[part 10 of 22: package /Cluster]
AUTOSAR XML (schema 4-3-0)
package /Cluster  (continued)
  can cluster E3V_K2CANFD: baudrate=500000, protocol-name=CAN, protocol-version=2.0, bus-off-recovery={bor-counter-l-1-to-l-2=1, bor-time-l-1=0.05, bor-time-l-2=0.2}, can-fd-baudrate=500000  (continued)
    can physical channel CHNL: comm-connectors=CN_E3V_K2CANFD  (continued)
      frame SAD_01_XIX_E3V_K2CANFD: id 0x5E0, to SAM, frame-length=8, can-addressing-mode=STANDARD, can-frame-rx-behavior=CAN-FD, can-frame-tx-behavior=CAN-FD
        pdu SAD_01_XIX_E3V_K2CANFD: length=8, minimum-delay=0.05, transmission-mode-true-timing={cyclic-timing={time-offset=0.0, time-period=0.5}, event-controlled-timing={number-of-repetitions=5, repetition-period=0.1}}, unused-bit-pattern=0  # MLBevo 8Byte LIN-CAN (1:1) Botschaft wird geroutet: - wenn entsprechender Slave codiert ist - wenn fehlerfreie Kommunikation zum Slave besteht - bei fehlerhafter Kommunikation zum Slave wird die Botschaft für 4s mit den letzten gültigen Werten versendet
          signal MD1_Position_XIX_SAD_01_XIX_E3V_K2CANFD: start 8, 7 bit, little-endian, data-type-policy=OVERRIDE, i-signal-type=PRIMITIVE, init-value=126, base-type=BT_MD1_Position, compu {phys=raw for raw 0..100, 126=Cx7e_Init (CM_MD1_Position_Cx7e_Init), 127=Cx7f_nicht_normiert (CM_MD1_Position_Cx7f_nicht_normiert); unit Unit_PerCent}, range phys 0..100 Unit_PerCent, raw 0..127, unit=Unit_PerCent, transfer-property=PENDING, to SAM  # Aktuelle Öffnungsweite Schiebedach.
          signal MD1_Lage_XIX_SAD_01_XIX_E3V_K2CANFD: start 15, 1 bit, little-endian, data-type-policy=OVERRIDE, i-signal-type=PRIMITIVE, init-value=0, base-type=BT_MD1_Lage, compu {0=Cx0_Ausstelllage (CM_MD1_Lage_Cx0_Ausstelllage), 1=Cx1_Schiebelage (CM_MD1_Lage_Cx1_Schiebelage)}, range raw 0..1, transfer-property=PENDING, to SAM  # Lage Schiebedachstellung 1 (Signal wird 1:1 vom BCM2 geroutet; ursprünglicher Sender: SAD = LIN-Slave vom BCM2)
          signal MD3_Position_XIX_SAD_01_XIX_E3V_K2CANFD: start 16, 7 bit, little-endian, data-type-policy=OVERRIDE, i-signal-type=PRIMITIVE, init-value=0, base-type=BT_MD3_Position, compu {phys=raw for raw 0..100; unit Unit_PerCent}, range phys 0..100 Unit_PerCent, raw 0..100, unit=Unit_PerCent, transfer-property=PENDING  # Schiebedachstellung 3 (Signal wird 1:1 vom BCM2 geroutet; ursprünglicher Sender: SAD = LIN-Slave vom BCM2)
          signal MD3_Lage_XIX_SAD_01_XIX_E3V_K2CANFD: start 23, 1 bit, little-endian, data-type-policy=OVERRIDE, i-signal-type=PRIMITIVE, init-value=0, base-type=BT_MD3_Lage, compu {0=Cx0_Ausstelllage (CM_MD3_Lage_Cx0_Ausstelllage), 1=Cx1_Schiebelage (CM_MD3_Lage_Cx1_Schiebelage)}, range raw 0..1, transfer-property=PENDING  # Lage Schiebedachstellung 3 (Signal wird 1:1 vom BCM2 geroutet; ursprünglicher Sender: SAD = LIN-Slave vom BCM2)
          signal MRollo_Position_XIX_SAD_01_XIX_E3V_K2CANFD: start 24, 7 bit, little-endian, data-type-policy=OVERRIDE, i-signal-type=PRIMITIVE, init-value=126, base-type=BT_MRollo_Position, compu {phys=raw for raw 0..100, 126=Cx7e_Init (CM_MRollo_Position_Cx7e_Init), 127=Cx7f_nicht_normiert (CM_MRollo_Position_Cx7f_nicht_normiert); unit Unit_PerCent}, range phys 0..100 Unit_PerCent, raw 0..127, unit=Unit_PerCent, transfer-property=PENDING  # Aktuelle Öffnungsweite des Dachrollos.
          signal MRollo_Lage_XIX_SAD_01_XIX_E3V_K2CANFD: start 31, 1 bit, little-endian, data-type-policy=OVERRIDE, i-signal-type=PRIMITIVE, init-value=0, base-type=BT_MRollo_Lage, compu {0=Cx0_Ausstelllage (CM_MRollo_Lage_Cx0_Ausstelllage), 1=Cx1_Schiebelage (CM_MRollo_Lage_Cx1_Schiebelage)}, range raw 0..1, transfer-property=PENDING  # Lage Rollo (Signal wird 1:1 vom BCM2 geroutet; ursprünglicher Sender: Rollo = LIN-Slave vom BCM2)
          signal SAD_normiert_XIX_SAD_01_XIX_E3V_K2CANFD: start 32, 1 bit, little-endian, data-type-policy=OVERRIDE, i-signal-type=PRIMITIVE, init-value=0, base-type=BT_SAD_normiert, compu {0=Cx0_inaktiv (CM_SAD_normiert_Cx0_inaktiv), 1=Cx1_aktiv (CM_SAD_normiert_Cx1_aktiv)}, range raw 0..1, transfer-property=TRIGGERED-ON-CHANGE-WITHOUT-REPETITION  # Anzeige Normierung des Schiebeausstelldaches
          signal SAD_Thermoschutz_XIX_SAD_01_XIX_E3V_K2CANFD: start 33, 1 bit, little-endian, data-type-policy=OVERRIDE, i-signal-type=PRIMITIVE, init-value=0, base-type=BT_SAD_Thermoschutz, compu {0=Cx0_inaktiv (CM_SAD_Thermoschutz_Cx0_inaktiv), 1=Cx1_aktiv (CM_SAD_Thermoschutz_Cx1_aktiv)}, range raw 0..1, transfer-property=TRIGGERED-ON-CHANGE-WITHOUT-REPETITION  # Anzeige aktivierter Thermoschutz des Schiebeausstelldaches
          signal SAD_UEKB_aktiv_XIX_SAD_01_XIX_E3V_K2CANFD: start 34, 1 bit, little-endian, data-type-policy=OVERRIDE, i-signal-type=PRIMITIVE, init-value=0, base-type=BT_SAD_UEKB_aktiv, compu {0=Cx0_inaktiv (CM_SAD_UEKB_aktiv_Cx0_inaktiv), 1=Cx1_aktiv (CM_SAD_UEKB_aktiv_Cx1_aktiv)}, range raw 0..1, transfer-property=TRIGGERED-ON-CHANGE-WITHOUT-REPETITION  # Anzeige aktivierter Überschusskraftbegrenzung des Schiebeausstelldaches
          signal Rollo_normiert_XIX_SAD_01_XIX_E3V_K2CANFD: start 35, 1 bit, little-endian, data-type-policy=OVERRIDE, i-signal-type=PRIMITIVE, init-value=0, base-type=BT_Rollo_normiert, compu {0=Cx0_inaktiv (CM_Rollo_normiert_Cx0_inaktiv), 1=Cx1_aktiv (CM_Rollo_normiert_Cx1_aktiv)}, range raw 0..1, transfer-property=TRIGGERED-ON-CHANGE-WITHOUT-REPETITION  # Anzeigen Normierung des Dachrollos
          signal Rollo_Thermoschutz_XIX_SAD_01_XIX_E3V_K2CANFD: start 36, 1 bit, little-endian, data-type-policy=OVERRIDE, i-signal-type=PRIMITIVE, init-value=0, base-type=BT_Rollo_Thermoschutz, compu {0=Cx0_inaktiv (CM_Rollo_Thermoschutz_Cx0_inaktiv), 1=Cx1_aktiv (CM_Rollo_Thermoschutz_Cx1_aktiv)}, range raw 0..1, transfer-property=TRIGGERED-ON-CHANGE-WITHOUT-REPETITION  # Anzeigen aktivierter Thermoschutz des Dachrollo
          signal Rollo_UEKB_aktiv_XIX_SAD_01_XIX_E3V_K2CANFD: start 37, 1 bit, little-endian, data-type-policy=OVERRIDE, i-signal-type=PRIMITIVE, init-value=0, base-type=BT_Rollo_UEKB_aktiv, compu {0=Cx0_inaktiv (CM_Rollo_UEKB_aktiv_Cx0_inaktiv), 1=Cx1_aktiv (CM_Rollo_UEKB_aktiv_Cx1_aktiv)}, range raw 0..1, transfer-property=TRIGGERED-ON-CHANGE-WITHOUT-REPETITION  # Anzeigen aktivierter Überschusskraftbegrenzung des Dachrollos
          signal SAD_Taster_Deckel_hi_XIX_SAD_01_XIX_E3V_K2CANFD: start 38, 4 bit, little-endian, data-type-policy=OVERRIDE, i-signal-type=PRIMITIVE, init-value=0, base-type=BT_SAD_Taster_Deckel_hi, compu {0=Cx0_nicht_betaetigt (CM_SAD_Taster_Deckel_hi_Cx0_nicht_betaetigt), 1=Cx1_man_sl_zu (CM_SAD_Taster_Deckel_hi_Cx1_man_sl_zu), 2=Cx2_auto_sl_zu (CM_SAD_Taster_Deckel_hi_Cx2_auto_sl_zu), 3=Cx3_man_sl_auf (CM_SAD_Taster_Deckel_hi_Cx3_man_sl_auf), 4=Cx4_auto_sl_auf (CM_SAD_Taster_Deckel_hi_Cx4_auto_sl_auf), 5=Cx5_man_al_auf (CM_SAD_Taster_Deckel_hi_Cx5_man_al_auf), 6=Cx6_auto_al_auf (CM_SAD_Taster_Deckel_hi_Cx6_auto_al_auf), 7=Cx7_man_al_zu (CM_SAD_Taster_Deckel_hi_Cx7_man_al_zu), 8=Cx8_auto_al_zu (CM_SAD_Taster_Deckel_hi_Cx8_auto_al_zu), 14=Cxe_fehler_schalter_haengt (CM_SAD_Taster_Deckel_hi_Cxe_fehler_schalter_haengt), 15=Cxf_fehler_schalter_unplausibel (CM_SAD_Taster_Deckel_hi_Cxf_fehler_schalter_unplausibel)}, range raw 0..15, transfer-property=TRIGGERED-ON-CHANGE  # Taster für SAD Deckel hinten
          signal SAD_Taster_Deckel_vo_XIX_SAD_01_XIX_E3V_K2CANFD: start 42, 4 bit, little-endian, data-type-policy=OVERRIDE, i-signal-type=PRIMITIVE, init-value=0, base-type=BT_SAD_Taster_Deckel_vo, compu {0=Cx0_nicht_betaetigt (CM_SAD_Taster_Deckel_vo_Cx0_nicht_betaetigt), 1=Cx1_man_sl_zu (CM_SAD_Taster_Deckel_vo_Cx1_man_sl_zu), 2=Cx2_auto_sl_zu (CM_SAD_Taster_Deckel_vo_Cx2_auto_sl_zu), 3=Cx3_man_sl_auf (CM_SAD_Taster_Deckel_vo_Cx3_man_sl_auf), 4=Cx4_auto_sl_auf (CM_SAD_Taster_Deckel_vo_Cx4_auto_sl_auf), 5=Cx5_man_al_auf (CM_SAD_Taster_Deckel_vo_Cx5_man_al_auf), 6=Cx6_auto_al_auf (CM_SAD_Taster_Deckel_vo_Cx6_auto_al_auf), 7=Cx7_man_al_zu (CM_SAD_Taster_Deckel_vo_Cx7_man_al_zu), 8=Cx8_auto_al_zu (CM_SAD_Taster_Deckel_vo_Cx8_auto_al_zu), 14=Cxe_fehler_schalter_haengt (CM_SAD_Taster_Deckel_vo_Cxe_fehler_schalter_haengt), 15=Cxf_fehler_schalter_unplausibel (CM_SAD_Taster_Deckel_vo_Cxf_fehler_schalter_unplausibel)}, range raw 0..15, transfer-property=TRIGGERED-ON-CHANGE  # Taster für SAD Deckel vorne
          signal SAD_Taster_Rollo_hi_XIX_SAD_01_XIX_E3V_K2CANFD: start 46, 3 bit, little-endian, data-type-policy=OVERRIDE, i-signal-type=PRIMITIVE, init-value=0, base-type=BT_SAD_Taster_Rollo_hi, compu {0=Cx0_nicht_betaetigt (CM_SAD_Taster_Rollo_hi_Cx0_nicht_betaetigt), 1=Cx1_man_zu (CM_SAD_Taster_Rollo_hi_Cx1_man_zu), 2=Cx2_auto_zu (CM_SAD_Taster_Rollo_hi_Cx2_auto_zu), 3=Cx3_man_auf (CM_SAD_Taster_Rollo_hi_Cx3_man_auf), 4=Cx4_auto_auf (CM_SAD_Taster_Rollo_hi_Cx4_auto_auf), 6=Cx6_fehler_schalter_haengt (CM_SAD_Taster_Rollo_hi_Cx6_fehler_schalter_haengt), 7=Cx7_fehler_schalter_unplausibel (CM_SAD_Taster_Rollo_hi_Cx7_fehler_schalter_unplausibel)}, range raw 0..7, transfer-property=TRIGGERED-ON-CHANGE  # Taster für SAD Rollo hinten
          signal SAD_Taster_Rollo_vo_XIX_SAD_01_XIX_E3V_K2CANFD: start 49, 3 bit, little-endian, data-type-policy=OVERRIDE, i-signal-type=PRIMITIVE, init-value=0, base-type=BT_SAD_Taster_Rollo_vo, compu {0=Cx0_nicht_betaetigt (CM_SAD_Taster_Rollo_vo_Cx0_nicht_betaetigt), 1=Cx1_man_zu (CM_SAD_Taster_Rollo_vo_Cx1_man_zu), 2=Cx2_auto_zu (CM_SAD_Taster_Rollo_vo_Cx2_auto_zu), 3=Cx3_man_auf (CM_SAD_Taster_Rollo_vo_Cx3_man_auf), 4=Cx4_auto_auf (CM_SAD_Taster_Rollo_vo_Cx4_auto_auf), 6=Cx6_fehler_schalter_haengt (CM_SAD_Taster_Rollo_vo_Cx6_fehler_schalter_haengt), 7=Cx7_fehler_schalter_unplausibel (CM_SAD_Taster_Rollo_vo_Cx7_fehler_schalter_unplausibel)}, range raw 0..7, transfer-property=TRIGGERED-ON-CHANGE  # Taster für SAD Rollo vorne
          signal SAD_Anf_ESC_Zuschaltung_XIX_SAD_01_XIX_E3V_K2CANFD: start 52, 1 bit, little-endian, data-type-policy=OVERRIDE, i-signal-type=PRIMITIVE, init-value=0, base-type=BT_SAD_Anf_ESC_Zuschaltung, compu {0=Cx0_inaktiv (CM_SAD_Anf_ESC_Zuschaltung_Cx0_inaktiv), 1=Cx1_aktiv (CM_SAD_Anf_ESC_Zuschaltung_Cx1_aktiv)}, range raw 0..1, transfer-property=TRIGGERED-ON-CHANGE-WITHOUT-REPETITION  # Zwangsaktivierung ESP durch SAD-SG (bei geöffnetem Schiebedach und V> xx km/h).
          signal SAD_Text_XIX_SAD_01_XIX_E3V_K2CANFD: start 53, 1 bit, little-endian, data-type-policy=OVERRIDE, i-signal-type=PRIMITIVE, init-value=0, base-type=BT_SAD_Text, compu {0=Cx0_inaktiv (CM_SAD_Text_Cx0_inaktiv), 1=Cx1_aktiv (CM_SAD_Text_Cx1_aktiv)}, range raw 0..1, transfer-property=TRIGGERED-ON-CHANGE  # Fehler Windabweiser in Abhängigkeit von der Geschwindigkeit
          signal SAD_ToggleBit_XIX_SAD_01_XIX_E3V_K2CANFD: start 54, 1 bit, little-endian, data-type-policy=OVERRIDE, i-signal-type=PRIMITIVE, init-value=0, base-type=BT_SAD_ToggleBit, compu {phys=raw for raw 0..1}, range phys 0..1, raw 0..1, transfer-property=PENDING  # SIL A Absicherung für die Signale: SAD_normiert, MD1_Lage, MD1_Position, SAD_Anf_ESC_Zuschaltung
          signal SAD_ParityBit_XIX_SAD_01_XIX_E3V_K2CANFD: start 55, 1 bit, little-endian, data-type-policy=OVERRIDE, i-signal-type=PRIMITIVE, init-value=0, base-type=BT_SAD_ParityBit, compu {phys=raw for raw 0..1}, range phys 0..1, raw 0..1, transfer-property=PENDING  # SIL A Absicherung für die Signale: SAD_normiert, MD1_Lage, MD1_Position, SAD_Anf_ESC_Zuschaltung
      frame SAL_01_XIX_E3V_K2CANFD: id 0x12DD54C9, to SAM, frame-length=8, can-addressing-mode=EXTENDED, can-frame-rx-behavior=CAN-FD, can-frame-tx-behavior=CAN-FD
        pdu SAL_01_XIX_E3V_K2CANFD_E2E: length=8, minimum-delay=0.01, transmission-mode-true-timing=event-controlled-timing={number-of-repetitions=0, repetition-period=0.0}, unused-bit-pattern=0  # Fuer die Botschaft ist das Cyclic-Timing 0.08 zu verwenden.
          signal SAL_01_CRC_XIX_SAL_01_XIX_E3V_K2CANFD: start 0, 8 bit, little-endian, data-type-policy=OVERRIDE, i-signal-type=PRIMITIVE, base-type=BT_SAL_01_CRC, compu {phys=raw for raw 0..255}, range phys 0..255, raw 0..255, to SAM(timeout 0.8 s)  # Für MLB: Berechnung siehe Lastenheft "Kommunikationsabsicherung für FlexRay und CAN" Ab MQB und MLBevo: Berechnung siehe Lastenheft "End-to-End Kommunikationsabsicherung" Endwerte siehe Begleitdokument "S-PDU Kennungsfolgen"
          signal SAL_01_BZ_XIX_SAL_01_XIX_E3V_K2CANFD: start 8, 4 bit, little-endian, data-type-policy=OVERRIDE, i-signal-type=PRIMITIVE, base-type=BT_SAL_01_BZ, compu {phys=raw for raw 0..15}, range phys 0..15, raw 0..15, to SAM(timeout 0.8 s)  # 4bit Botschaftszähler, wird mit jeder Sendebotschaft inkrementiert
          signal SAL_LDS_Abblendlicht_Anf_XIX_SAL_01_XIX_E3V_K2CANFD: start 12, 1 bit, little-endian, data-type-policy=OVERRIDE, i-signal-type=PRIMITIVE, init-value=0, base-type=BT_SAL_LDS_Abblendlicht_Anf, compu {0=Cx0_nicht_aktiv (CM_SAL_LDS_Abblendlicht_Anf_Cx0_nicht_aktiv), 1=Cx1_aktiv (CM_SAL_LDS_Abblendlicht_Anf_Cx1_aktiv)}, range raw 0..1, to SAM(timeout 0.8 s)  # Signal gibt an, ob das Abblendlicht angefordert wird.
          signal SAL_LDS_Assistenzfahrlicht_Anf_XIX_SAL_01_XIX_E3V_K2CANFD: start 13, 1 bit, little-endian, data-type-policy=OVERRIDE, i-signal-type=PRIMITIVE, init-value=0, base-type=BT_SAL_LDS_Assistenzfahrlicht_Anf, compu {0=Cx0_nicht_aktiv (CM_SAL_LDS_Assistenzfahrlicht_Anf_Cx0_nicht_aktiv), 1=Cx1_aktiv (CM_SAL_LDS_Assistenzfahrlicht_Anf_Cx1_aktiv)}, range raw 0..1, to SAM(timeout 0.8 s)  # Signal gibt an, ob das Assistenzfahrlicht (AUTO) angefordert wird.
          signal SAL_LDS_Nullstellung_Anf_XIX_SAL_01_XIX_E3V_K2CANFD: start 14, 1 bit, little-endian, data-type-policy=OVERRIDE, i-signal-type=PRIMITIVE, init-value=0, base-type=BT_SAL_LDS_Nullstellung_Anf, compu {0=Cx0_nicht_aktiv (CM_SAL_LDS_Nullstellung_Anf_Cx0_nicht_aktiv), 1=Cx1_aktiv (CM_SAL_LDS_Nullstellung_Anf_Cx1_aktiv)}, range raw 0..1, to SAM(timeout 0.8 s)  # Signal gibt an, ob das Nullstellung vom Lichtdrehschalter angefordert wird.
          signal SAL_LDS_Standlicht_Anf_XIX_SAL_01_XIX_E3V_K2CANFD: start 15, 1 bit, little-endian, data-type-policy=OVERRIDE, i-signal-type=PRIMITIVE, init-value=0, base-type=BT_SAL_LDS_Standlicht_Anf, compu {0=Cx0_nicht_aktiv (CM_SAL_LDS_Standlicht_Anf_Cx0_nicht_aktiv), 1=Cx1_aktiv (CM_SAL_LDS_Standlicht_Anf_Cx1_aktiv)}, range raw 0..1, to SAM(timeout 0.8 s)  # Signal gibt an, ob das Standlicht angefordert wird.
          signal SBBR_SL_AnimDimm_Freigabe_XIX_SAL_01_XIX_E3V_K2CANFD: start 16, 2 bit, little-endian, data-type-policy=OVERRIDE, i-signal-type=PRIMITIVE, init-value=0, base-type=BT_SBBR_SL_AnimDimm_Freigabe, compu {0=Cx0_Dimmung_aus_Animation_aus (CM_SBBR_SL_AnimDimm_Freigabe_Cx0_Dimmung_aus_Animation_aus), 1=Cx1_Dimmung_an_Animation_aus (CM_SBBR_SL_AnimDimm_Freigabe_Cx1_Dimmung_an_Animation_aus), 2=Cx2_Dimmung_aus_Animation_an (CM_SBBR_SL_AnimDimm_Freigabe_Cx2_Dimmung_aus_Animation_an), 3=Cx3_Dimmung_an_Animation_an (CM_SBBR_SL_AnimDimm_Freigabe_Cx3_Dimmung_an_Animation_an)}, range raw 0..3  # Freigabesignal für Dimmung und Animation
          signal BCM2_Bremsl_durch_ECD_XIX_SAL_01_XIX_E3V_K2CANFD: start 18, 1 bit, little-endian, data-type-policy=OVERRIDE, i-signal-type=PRIMITIVE, init-value=0, base-type=BT_BCM2_Bremsl_durch_ECD, compu {0=Cx0_Bremslicht_ist_aus (CM_BCM2_Bremsl_durch_ECD_Cx0_Bremslicht_ist_aus), 1=Cx1_Bremslicht_durch_ECD_aktiv (CM_BCM2_Bremsl_durch_ECD_Cx1_Bremslicht_durch_ECD_aktiv)}, range raw 0..1  # Bremslicht (ECD-Bremsung)
          signal SAL_LH_Anf_XIX_SAL_01_XIX_E3V_K2CANFD: start 19, 1 bit, little-endian, data-type-policy=OVERRIDE, i-signal-type=PRIMITIVE, init-value=0, base-type=BT_SAL_LH_Anf, compu {0=Cx0_nicht_angefordert (CM_SAL_LH_Anf_Cx0_nicht_angefordert), 1=Cx1_angefordert (CM_SAL_LH_Anf_Cx1_angefordert)}, range raw 0..1, to SAM(timeout 0.8 s)  # Anforderung LH an Lichtrouter
          signal SAL_BRL_Anf_XIX_SAL_01_XIX_E3V_K2CANFD: start 20, 1 bit, little-endian, data-type-policy=OVERRIDE, i-signal-type=PRIMITIVE, init-value=0, base-type=BT_SAL_BRL_Anf, compu {0=Cx0_nicht_angefordert (CM_SAL_BRL_Anf_Cx0_nicht_angefordert), 1=Cx1_angefordert (CM_SAL_BRL_Anf_Cx1_angefordert)}, range raw 0..1, to SAM(timeout 0.8 s)  # Bremslicht-Anforderung an Lichtrouter
          signal SAL_WBT_Bel_XIX_SAL_01_XIX_E3V_K2CANFD: start 21, 1 bit, little-endian, data-type-policy=OVERRIDE, i-signal-type=PRIMITIVE, init-value=0, base-type=BT_SAL_WBT_Bel, compu {0=Cx0_nicht_angefordert (CM_SAL_WBT_Bel_Cx0_nicht_angefordert), 1=Cx1_angefordert (CM_SAL_WBT_Bel_Cx1_angefordert)}, range raw 0..1, to SAM(timeout 0.8 s)  # Beleuchtung Warnblinktaster an SAM
          signal SAL_CH_Anf_XIX_SAL_01_XIX_E3V_K2CANFD: start 22, 1 bit, little-endian, data-type-policy=OVERRIDE, i-signal-type=PRIMITIVE, init-value=0, base-type=BT_SAL_CH_Anf, compu {0=Cx0_nicht_angefordert (CM_SAL_CH_Anf_Cx0_nicht_angefordert), 1=Cx1_angefordert (CM_SAL_CH_Anf_Cx1_angefordert)}, range raw 0..1, to SAM(timeout 0.8 s)  # Anforderung CH an Lichtrouter
          signal SAL_PL_R_Anf_XIX_SAL_01_XIX_E3V_K2CANFD: start 23, 1 bit, little-endian, data-type-policy=OVERRIDE, i-signal-type=PRIMITIVE, init-value=0, base-type=BT_SAL_PL_R_Anf, compu {0=Cx0_nicht_angefordert (CM_SAL_PL_R_Anf_Cx0_nicht_angefordert), 1=Cx1_angefordert (CM_SAL_PL_R_Anf_Cx1_angefordert)}, range raw 0..1, to SAM(timeout 0.8 s)  # Anforderung Parklicht rechts an Lichtrouter
          signal SAL_PL_L_Anf_XIX_SAL_01_XIX_E3V_K2CANFD: start 24, 1 bit, little-endian, data-type-policy=OVERRIDE, i-signal-type=PRIMITIVE, init-value=0, base-type=BT_SAL_PL_L_Anf, compu {0=Cx0_nicht_angefordert (CM_SAL_PL_L_Anf_Cx0_nicht_angefordert), 1=Cx1_angefordert (CM_SAL_PL_L_Anf_Cx1_angefordert)}, range raw 0..1, to SAM(timeout 0.8 s)  # Anforderung Parklicht Links an Lichtrouter.
          signal SAL_BLK_R_Anf_XIX_SAL_01_XIX_E3V_K2CANFD: start 25, 1 bit, little-endian, data-type-policy=OVERRIDE, i-signal-type=PRIMITIVE, init-value=0, base-type=BT_SAL_BLK_R_Anf, compu {0=Cx0_nicht_angefordert (CM_SAL_BLK_R_Anf_Cx0_nicht_angefordert), 1=Cx1_angefordert (CM_SAL_BLK_R_Anf_Cx1_angefordert)}, range raw 0..1, to SAM(timeout 0.8 s)  # Anforderung Blinker rechts an Lichtrouter
          signal SAL_BLK_L_Anf_XIX_SAL_01_XIX_E3V_K2CANFD: start 26, 1 bit, little-endian, data-type-policy=OVERRIDE, i-signal-type=PRIMITIVE, init-value=0, base-type=BT_SAL_BLK_L_Anf, compu {0=Cx0_nicht_angefordert (CM_SAL_BLK_L_Anf_Cx0_nicht_angefordert), 1=Cx1_angefordert (CM_SAL_BLK_L_Anf_Cx1_angefordert)}, range raw 0..1, to SAM(timeout 0.8 s)  # Blink-Anforderung links an Lichtrouter
          signal SAL_RFL_Anf_XIX_SAL_01_XIX_E3V_K2CANFD: start 27, 1 bit, little-endian, data-type-policy=OVERRIDE, i-signal-type=PRIMITIVE, init-value=0, base-type=BT_SAL_RFL_Anf, compu {0=Cx0_nicht_angefordert (CM_SAL_RFL_Anf_Cx0_nicht_angefordert), 1=Cx1_angefordert (CM_SAL_RFL_Anf_Cx1_angefordert)}, range raw 0..1, to SAM(timeout 0.8 s)  # Anforderung Rückfahrlicht an Lichtrouter
          signal SAL_NSL_Anf_XIX_SAL_01_XIX_E3V_K2CANFD: start 28, 1 bit, little-endian, data-type-policy=OVERRIDE, i-signal-type=PRIMITIVE, init-value=0, base-type=BT_SAL_NSL_Anf, compu {0=Cx0_nicht_angefordert (CM_SAL_NSL_Anf_Cx0_nicht_angefordert), 1=Cx1_angefordert (CM_SAL_NSL_Anf_Cx1_angefordert)}, range raw 0..1, to SAM(timeout 0.8 s)  # Anforderung Nebelschlussleuchte an Lichtrouter
          signal SAL_SL_Anf_XIX_SAL_01_XIX_E3V_K2CANFD: start 29, 1 bit, little-endian, data-type-policy=OVERRIDE, i-signal-type=PRIMITIVE, init-value=0, base-type=BT_SAL_SL_Anf, compu {0=Cx0_nicht_angefordert (CM_SAL_SL_Anf_Cx0_nicht_angefordert), 1=Cx1_angefordert (CM_SAL_SL_Anf_Cx1_angefordert)}, range raw 0..1, to SAM(timeout 0.8 s)  # Anforderung Standlicht an Lichtrouter.
          signal SAL_HGB_Anf_XIX_SAL_01_XIX_E3V_K2CANFD: start 30, 1 bit, little-endian, data-type-policy=OVERRIDE, i-signal-type=PRIMITIVE, init-value=0, base-type=BT_SAL_HGB_Anf, compu {0=Cx0_nicht_angefordert (CM_SAL_HGB_Anf_Cx0_nicht_angefordert), 1=Cx1_angefordert (CM_SAL_HGB_Anf_Cx1_angefordert)}, range raw 0..1, to SAM(timeout 0.8 s)  # Anforderung HGB an Lichtrouter
          signal ISignalVoid_SAL_01_XIX_E3V_K2CANFD_0: start 31, 1 bit, little-endian, system signal SignalVoid_SAL_01_0, data-type-policy=OVERRIDE, i-signal-type=PRIMITIVE, base-type=BT_SignalVoid
          signal LWR_SollDC_XIX_SAL_01_XIX_E3V_K2CANFD: start 32, 8 bit, little-endian, data-type-policy=OVERRIDE, i-signal-type=PRIMITIVE, init-value=254, base-type=BT_LWR_SollDC, invalid-value=Invalid_LWR_SollDC_XIX_SAL_01_XIX_E3V_K2CANFD:255, compu {phys=raw*0.5 for raw 0..200, 254=Cxfe_Init (CM_LWR_SollDC_Cxfe_Init), 255=Cxff_Fehler (CM_LWR_SollDC_Cxff_Fehler); unit Unit_PerCent}, range phys 0..100 Unit_PerCent, raw 0..255, unit=Unit_PerCent, to SAM(timeout 0.8 s)  # Sollspannung in [% von UBatt] des linken und rechten Abblendlichtbündels.
          signal ISignalVoid_SAL_01_XIX_E3V_K2CANFD_1: start 40, 3 bit, little-endian, system signal SignalVoid_SAL_01_1, data-type-policy=OVERRIDE, i-signal-type=PRIMITIVE, base-type=BT_SignalVoid
          signal SAL_Bremszyklus_XIX_SAL_01_XIX_E3V_K2CANFD: start 43, 1 bit, little-endian, data-type-policy=OVERRIDE, i-signal-type=PRIMITIVE, init-value=0, base-type=BT_SAL_Bremszyklus, compu {0=Cx0_nicht_aktiv (CM_SAL_Bremszyklus_Cx0_nicht_aktiv), 1=Cx1_aktiv (CM_SAL_Bremszyklus_Cx1_aktiv)}, range raw 0..1, to SAM(timeout 0.8 s)  # Das Signal ist aktiv, wenn im Falle einer Notbremsung (Bremslicht-Blinken EA bzw. NBA) das Bremslicht hochfrequenz blinkt.
          signal SAL_Blinkerzyklus_R_XIX_SAL_01_XIX_E3V_K2CANFD: start 44, 1 bit, little-endian, data-type-policy=OVERRIDE, i-signal-type=PRIMITIVE, init-value=0, base-type=BT_SAL_Blinkerzyklus_R, compu {0=Cx0_inaktiv (CM_SAL_Blinkerzyklus_R_Cx0_inaktiv), 1=Cx1_aktiv (CM_SAL_Blinkerzyklus_R_Cx1_aktiv)}, range raw 0..1, to SAM(timeout 0.8 s)  # Signal wird im MEB benötigt, um dem SAM mitzuteilen, dass eine Blinkfunktion für die rechte Seite aktiv ist.
          signal SAL_Blinkerzyklus_L_XIX_SAL_01_XIX_E3V_K2CANFD: start 45, 1 bit, little-endian, data-type-policy=OVERRIDE, i-signal-type=PRIMITIVE, init-value=0, base-type=BT_SAL_Blinkerzyklus_L, compu {0=Cx0_inaktiv (CM_SAL_Blinkerzyklus_L_Cx0_inaktiv), 1=Cx1_aktiv (CM_SAL_Blinkerzyklus_L_Cx1_aktiv)}, range raw 0..1, to SAM(timeout 0.8 s)  # Signal wird im MEB benötigt, um dem SAM mitzuteilen, dass eine Blinkfunktion für die linke Seite aktiv ist.
          signal LWR_Lampe_XIX_SAL_01_XIX_E3V_K2CANFD: start 46, 1 bit, little-endian, data-type-policy=OVERRIDE, i-signal-type=PRIMITIVE, init-value=0, base-type=BT_LWR_Lampe, compu {0=Cx0_LWR_Fehlerlampe_aus (CM_LWR_Lampe_Cx0_LWR_Fehlerlampe_aus) (LWR Fehlerlampe aus), 1=Cx1_LWR_Fehlerlampe_ein (CM_LWR_Lampe_Cx1_LWR_Fehlerlampe_ein) (LWR Fehlerlampe ein)}, range raw 0..1  # Status der Fehlerlampe: aktuell anliegender Fehlerzustand
          signal AFS_Lampe_XIX_SAL_01_XIX_E3V_K2CANFD: start 47, 1 bit, little-endian, data-type-policy=OVERRIDE, i-signal-type=PRIMITIVE, init-value=0, base-type=BT_AFS_Lampe, compu {0=Cx0_Aus (CM_AFS_Lampe_Cx0_Aus), 1=Cx1_Ein (CM_AFS_Lampe_Cx1_Ein)}, range raw 0..1  # Status der Fehlerlampe: aktuell anliegender Fehlerzustand des dynamischen oder statischen Kurvenlichtes
          signal LWR_Reisemodus_Texte_XIX_SAL_01_XIX_E3V_K2CANFD: start 48, 2 bit, little-endian, data-type-policy=OVERRIDE, i-signal-type=PRIMITIVE, init-value=0, base-type=BT_LWR_Reisemodus_Texte, compu {0=Cx0_keine_Anzeige (CM_LWR_Reisemodus_Texte_Cx0_keine_Anzeige), 1=Cx1_Umschaltung_auf_Linksverkehr_aktiv (CM_LWR_Reisemodus_Texte_Cx1_Umschaltung_auf_Linksverkehr_aktiv), 2=Cx2_Umschaltung_auf_Rechtsverkehr_aktiv (CM_LWR_Reisemodus_Texte_Cx2_Umschaltung_auf_Rechtsverkehr_aktiv)}, range raw 0..2  # Anzeige der eingestellten Verkehrsart bei aktivem Touristenlicht
          signal SAL_KZL_Anf_XIX_SAL_01_XIX_E3V_K2CANFD: start 50, 1 bit, little-endian, data-type-policy=OVERRIDE, i-signal-type=PRIMITIVE, init-value=0, base-type=BT_SAL_KZL_Anf, compu {0=Cx0_nicht_angefordert (CM_SAL_KZL_Anf_Cx0_nicht_angefordert), 1=Cx1_angefordert (CM_SAL_KZL_Anf_Cx1_angefordert)}, range raw 0..1, to SAM(timeout 0.8 s)  # Anforderung Kennzeichenleuchte an Lichtrouter
          signal SAL_KL_50_XIX_SAL_01_XIX_E3V_K2CANFD: start 51, 1 bit, little-endian, data-type-policy=OVERRIDE, i-signal-type=PRIMITIVE, init-value=0, base-type=BT_SAL_KL_50, compu {0=Cx0_aus (CM_SAL_KL_50_Cx0_aus), 1=Cx1_ein (CM_SAL_KL_50_Cx1_ein)}, range raw 0..1, to SAM(timeout 0.8 s)  # Klemme 50 nach Plausibilisierung des Startwunsches. Dies wird für das Außenlicht benötigt.
          signal SAL_KL_75a_vFzg_XIX_SAL_01_XIX_E3V_K2CANFD: start 52, 1 bit, little-endian, data-type-policy=OVERRIDE, i-signal-type=PRIMITIVE, init-value=0, base-type=BT_SAL_KL_75a_vFzg, compu {0=Cx0_aus (CM_SAL_KL_75a_vFzg_Cx0_aus), 1=Cx1_ein (CM_SAL_KL_75a_vFzg_Cx1_ein)}, range raw 0..1, to SAM(timeout 0.8 s)  # Die um die Geschwindigkeitsinformation erweiterte Kl75a.
          signal SAL_KL_75a_XIX_SAL_01_XIX_E3V_K2CANFD: start 53, 1 bit, little-endian, data-type-policy=OVERRIDE, i-signal-type=PRIMITIVE, init-value=0, base-type=BT_SAL_KL_75a, compu {0=Cx0_aus (CM_SAL_KL_75a_Cx0_aus), 1=Cx1_ein (CM_SAL_KL_75a_Cx1_ein)}, range raw 0..1, to SAM(timeout 0.8 s)  # Für Standard-Außenlicht wird die abgesicherte Kl.75a benötigt. Diese wird um das Geschwindigkeitssignal erweitert.
          signal SAL_KL_75_vFzg_XIX_SAL_01_XIX_E3V_K2CANFD: start 54, 1 bit, little-endian, data-type-policy=OVERRIDE, i-signal-type=PRIMITIVE, init-value=0, base-type=BT_SAL_KL_75_vFzg, compu {0=Cx0_aus (CM_SAL_KL_75_vFzg_Cx0_aus), 1=Cx1_ein (CM_SAL_KL_75_vFzg_Cx1_ein)}, range raw 0..1, to SAM(timeout 0.8 s)  # Die um das Geschwindigkeitssignal erweiterte Klemme 75.
          signal SAL_Kl_75_XIX_SAL_01_XIX_E3V_K2CANFD: start 55, 1 bit, little-endian, data-type-policy=OVERRIDE, i-signal-type=PRIMITIVE, init-value=0, base-type=BT_SAL_Kl_75, compu {0=Cx0_aus (CM_SAL_Kl_75_Cx0_aus), 1=Cx1_ein (CM_SAL_Kl_75_Cx1_ein)}, range raw 0..1, to SAM(timeout 0.8 s)  # Für Standard-Außenlicht wird die abgesicherte Kl.75 benötigt. Diese wird um das Geschwindigkeitssignal erweitert.
          signal SAL_KL_50_5s_XIX_SAL_01_XIX_E3V_K2CANFD: start 56, 1 bit, little-endian, data-type-policy=OVERRIDE, i-signal-type=PRIMITIVE, init-value=0, base-type=BT_SAL_KL_50_5s, compu {0=Cx0_aus (CM_SAL_KL_50_5s_Cx0_aus), 1=Cx1_ein (CM_SAL_KL_50_5s_Cx1_ein)}, range raw 0..1, to SAM(timeout 0.8 s)  # Kl_50_5s ist die um 5 Sekunden verzögerte Klemme 50.
          signal SAL_Kl_15_vFzg_S_XIX_SAL_01_XIX_E3V_K2CANFD: start 57, 1 bit, little-endian, data-type-policy=OVERRIDE, i-signal-type=PRIMITIVE, init-value=0, base-type=BT_SAL_Kl_15_vFzg_S, compu {0=Cx0_aus (CM_SAL_Kl_15_vFzg_S_Cx0_aus), 1=Cx1_ein (CM_SAL_Kl_15_vFzg_S_Cx1_ein)}, range raw 0..1, to SAM(timeout 0.8 s)  # Kl_15_vfzg_S für Sicherheitsanforderung im Außenlicht.
          signal SAL_Kl_15_vFzg_XIX_SAL_01_XIX_E3V_K2CANFD: start 58, 1 bit, little-endian, data-type-policy=OVERRIDE, i-signal-type=PRIMITIVE, init-value=0, base-type=BT_SAL_Kl_15_vFzg, compu {0=Cx0_aus (CM_SAL_Kl_15_vFzg_Cx0_aus), 1=Cx1_ein (CM_SAL_Kl_15_vFzg_Cx1_ein)}, range raw 0..1, to SAM(timeout 0.8 s)  # Die Kl-15 Botschaft, erweitert um die Information, ob das Fahrzeug aktive Wegstrecke zurücklegt.
          signal SAL_Kl_15_XIX_SAL_01_XIX_E3V_K2CANFD: start 59, 1 bit, little-endian, data-type-policy=OVERRIDE, i-signal-type=PRIMITIVE, init-value=0, base-type=BT_SAL_Kl_15, compu {0=Cx0_aus (CM_SAL_Kl_15_Cx0_aus), 1=Cx1_ein (CM_SAL_Kl_15_Cx1_ein)}, range raw 0..1, to SAM(timeout 0.8 s)  # Vom Standard Außenlicht generierte Kl15, welche durch das Geschwindigkeitssignal plausibilisiert ist. Hiermit wird sichergestellt, dass das Licht nicht erlischt, wenn die Kl15 aus ist und das FZG trotzdem rollt.
          signal DLI_Ambex_RefStatus_XIX_SAL_01_XIX_E3V_K2CANFD: start 60, 3 bit, little-endian, data-type-policy=OVERRIDE, i-signal-type=PRIMITIVE, init-value=0, base-type=BT_DLI_Ambex_RefStatus, invalid-value=Invalid_DLI_Ambex_RefStatus_XIX_SAL_01_XIX_E3V_K2CANFD:4, compu {0=Cx0_Init (CM_DLI_Ambex_RefStatus_Cx0_Init), 1=Cx1_notAvailable (CM_DLI_Ambex_RefStatus_Cx1_notAvailable), 2=Cx2_Referenzlaufaktiv (CM_DLI_Ambex_RefStatus_Cx2_Referenzlaufaktiv), 3=Cx3_Referenzlaufbeendet (CM_DLI_Ambex_RefStatus_Cx3_Referenzlaufbeendet), 4=Cx4_Fehler (CM_DLI_Ambex_RefStatus_Cx4_Fehler)}, range raw 0..4, to SAM(timeout 0.8 s)  # Status vom DLI an das Exterieur Ambiente
          signal SAL_Aussenbeleuchtung_defekt_XIX_SAL_01_XIX_E3V_K2CANFD: start 63, 1 bit, little-endian, data-type-policy=OVERRIDE, i-signal-type=PRIMITIVE, init-value=0, base-type=BT_SAL_Aussenbeleuchtung_defekt, compu {0=Cx0_ok (CM_SAL_Aussenbeleuchtung_defekt_Cx0_ok), 1=Cx1_defekt (CM_SAL_Aussenbeleuchtung_defekt_Cx1_defekt)}, range raw 0..1  # Signal gibt an, ob mindestens ein Leuchtmittel der Außenbeleuchtung defekt ist. Dies wird für Funktionen benötigt, die bei defekter Außenbeleuchtung nicht starten bzw. abbrechen (z.B. IPA/RPA, Parkhauspilot, etc.)
          mapping SG_SAL_01_XIX_E3V_K2CANFD: i-signal-group=SG_SAL_01_XIX_E3V_K2CANFD, transfer-property=TRIGGERED-WITHOUT-REPETITION
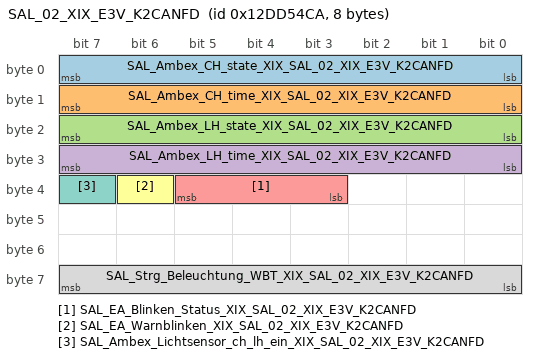
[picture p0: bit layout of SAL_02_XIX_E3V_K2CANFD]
      frame SAL_02_XIX_E3V_K2CANFD: id 0x12DD54CA, to SAM, frame-length=8, can-addressing-mode=EXTENDED, can-frame-rx-behavior=CAN-FD, can-frame-tx-behavior=CAN-FD
        pdu SAL_02_XIX_E3V_K2CANFD: length=8, minimum-delay=0.01, transmission-mode-true-timing={cyclic-timing={time-offset=0.0, time-period=0.1}, event-controlled-timing={number-of-repetitions=5, repetition-period=0.05}}, unused-bit-pattern=0
          signal SAL_Ambex_CH_state_XIX_SAL_02_XIX_E3V_K2CANFD: start 0, 8 bit, little-endian, data-type-policy=OVERRIDE, i-signal-type=PRIMITIVE, init-value=0, base-type=BT_SAL_Ambex_CH_state, compu {0=Cx0_ComingHomeOFF (CM_SAL_Ambex_CH_state_Cx0_ComingHomeOFF), 1=Cx1_ComingHomeSTATIC (CM_SAL_Ambex_CH_state_Cx1_ComingHomeSTATIC), 3=Cx3_ComingHomeAMBIANCE (CM_SAL_Ambex_CH_state_Cx3_ComingHomeAMBIANCE)}, range raw 0..3, transfer-property=TRIGGERED-ON-CHANGE-WITHOUT-REPETITION, to SAM(timeout 1 s)  # Weiterleitung vom Coming Home State aus dem BAP_Aussenlicht
          signal SAL_Ambex_CH_time_XIX_SAL_02_XIX_E3V_K2CANFD: start 8, 8 bit, little-endian, data-type-policy=OVERRIDE, i-signal-type=PRIMITIVE, init-value=0, base-type=BT_SAL_Ambex_CH_time, compu {phys=raw for raw 0..90; unit Unit_Secon}, range phys 0..90 Unit_Secon, raw 0..90, unit=Unit_Secon, transfer-property=TRIGGERED-ON-CHANGE-WITHOUT-REPETITION, to SAM(timeout 1 s)  # Weiterleitung vom Coming Home Time aus dem BAP_Aussenlicht
          signal SAL_Ambex_LH_state_XIX_SAL_02_XIX_E3V_K2CANFD: start 16, 8 bit, little-endian, data-type-policy=OVERRIDE, i-signal-type=PRIMITIVE, init-value=0, base-type=BT_SAL_Ambex_LH_state, compu {0=Cx0_LeavingHomeOFF (CM_SAL_Ambex_LH_state_Cx0_LeavingHomeOFF), 1=Cx1_LeavingHomeSTATIC (CM_SAL_Ambex_LH_state_Cx1_LeavingHomeSTATIC), 3=Cx3_LeavingHomeAMBIANCE (CM_SAL_Ambex_LH_state_Cx3_LeavingHomeAMBIANCE)}, range raw 0..3, transfer-property=TRIGGERED-ON-CHANGE-WITHOUT-REPETITION, to SAM(timeout 1 s)  # Weiterleitung vom Leaving Home State aus dem BAP_Aussenlicht
          signal SAL_Ambex_LH_time_XIX_SAL_02_XIX_E3V_K2CANFD: start 24, 8 bit, little-endian, data-type-policy=OVERRIDE, i-signal-type=PRIMITIVE, init-value=0, base-type=BT_SAL_Ambex_LH_time, compu {phys=raw for raw 0..90; unit Unit_Secon}, range phys 0..90 Unit_Secon, raw 0..90, unit=Unit_Secon, transfer-property=TRIGGERED-ON-CHANGE-WITHOUT-REPETITION, to SAM(timeout 1 s)  # Weiterleitung vom Leaving Home Time aus dem BAP_Aussenlicht
          signal SAL_EA_Blinken_Status_XIX_SAL_02_XIX_E3V_K2CANFD: start 35, 3 bit, little-endian, data-type-policy=OVERRIDE, i-signal-type=PRIMITIVE, init-value=0, base-type=BT_SAL_EA_Blinken_Status, compu {0=Cx0_init (CM_SAL_EA_Blinken_Status_Cx0_init), 1=Cx1_nicht_bereit (CM_SAL_EA_Blinken_Status_Cx1_nicht_bereit), 2=Cx2_bereit (CM_SAL_EA_Blinken_Status_Cx2_bereit), 3=Cx3_aktiv_links (CM_SAL_EA_Blinken_Status_Cx3_aktiv_links), 4=Cx4_aktiv_rechts (CM_SAL_EA_Blinken_Status_Cx4_aktiv_rechts)}, range raw 0..4, transfer-property=TRIGGERED-ON-CHANGE-WITHOUT-REPETITION  # Rückkanal des durch EA angeforderten Warnblinken
          signal SAL_EA_Warnblinken_XIX_SAL_02_XIX_E3V_K2CANFD: start 38, 1 bit, little-endian, data-type-policy=OVERRIDE, i-signal-type=PRIMITIVE, init-value=0, base-type=BT_SAL_EA_Warnblinken, compu {0=Cx0_inaktiv (CM_SAL_EA_Warnblinken_Cx0_inaktiv), 1=Cx1_aktiv (CM_SAL_EA_Warnblinken_Cx1_aktiv)}, range raw 0..1, transfer-property=TRIGGERED-ON-CHANGE-WITHOUT-REPETITION  # SAL Rückmeldung EA Blinker-Status an Funktion EA
          signal SAL_Ambex_Lichtsensor_ch_lh_ein_XIX_SAL_02_XIX_E3V_K2CANFD: start 39, 1 bit, little-endian, data-type-policy=OVERRIDE, i-signal-type=PRIMITIVE, init-value=0, base-type=BT_SAL_Ambex_Lichtsensor_ch_lh_ein, compu {0=Cx0_Tag_erkannt (CM_SAL_Ambex_Lichtsensor_ch_lh_ein_Cx0_Tag_erkannt), 1=Cx1_Nacht_erkannt (CM_SAL_Ambex_Lichtsensor_ch_lh_ein_Cx1_Nacht_erkannt)}, range raw 0..1, transfer-property=TRIGGERED-ON-CHANGE-WITHOUT-REPETITION, to SAM(timeout 1 s)  # Signal gibt an, welchen Zustand das Standardaußenlicht erkennt, bezüglich Tag/Nacht (Umgebungshelligkeit)
          signal SAL_Strg_Beleuchtung_WBT_XIX_SAL_02_XIX_E3V_K2CANFD: start 56, 8 bit, little-endian, data-type-policy=OVERRIDE, i-signal-type=PRIMITIVE, init-value=254, base-type=BT_SAL_Strg_Beleuchtung_WBT, invalid-value=Invalid_SAL_Strg_Beleuchtung_WBT_XIX_SAL_02_XIX_E3V_K2CANFD:255, compu {phys=raw*0.5 for raw 0..200, 254=Cxfe_Init (CM_SAL_Strg_Beleuchtung_WBT_Cxfe_Init), 255=Cxff_Fehler (CM_SAL_Strg_Beleuchtung_WBT_Cxff_Fehler); unit Unit_PerCent}, range phys 0..100 Unit_PerCent, raw 0..255, unit=Unit_PerCent, transfer-property=TRIGGERED-ON-CHANGE  # Anforderungssignal zur Ansteuerung der Warnblinktaster-Beleuchtung. Das Signal gibt den Dimmwert an, mit dem die WBT-Beleuchtung angesteuert werden soll.
      frame SAM_01_XIX_E3V_K2CANFD: id 0x205, from SAM, frame-length=8, can-addressing-mode=STANDARD, can-frame-rx-behavior=CAN-FD, can-frame-tx-behavior=CAN-FD
        pdu SAM_01_XIX_E3V_K2CANFD_E2E: length=8, minimum-delay=0.01, transmission-mode-true-timing=event-controlled-timing={number-of-repetitions=0, repetition-period=0.0}, unused-bit-pattern=0  # Fuer die Botschaft ist das Cyclic-Timing 0.2 zu verwenden.
          signal SAM_01_CRC_XIX_SAM_01_XIX_E3V_K2CANFD: start 0, 8 bit, little-endian, data-type-policy=OVERRIDE, i-signal-type=PRIMITIVE, base-type=BT_SAM_01_CRC, compu {phys=raw for raw 0..255}, range phys 0..255, raw 0..255  # Für MLB: Berechnung siehe Lastenheft "Kommunikationsabsicherung für FlexRay und CAN" Ab MQB und MLBevo: Berechnung siehe Lastenheft "End-to-End Kommunikationsabsicherung" Endwerte siehe Begleitdokument "S-PDU Kennungsfolgen"
          signal SAM_01_BZ_XIX_SAM_01_XIX_E3V_K2CANFD: start 8, 4 bit, little-endian, data-type-policy=OVERRIDE, i-signal-type=PRIMITIVE, base-type=BT_SAM_01_BZ, compu {phys=raw for raw 0..15}, range phys 0..15, raw 0..15  # 4bit Botschaftszähler, wird mit jeder Sendebotschaft inkrementiert
          signal ZV_Ladeklappe_VerEntriegeln_XIX_SAM_01_XIX_E3V_K2CANFD: start 12, 2 bit, little-endian, data-type-policy=OVERRIDE, i-signal-type=PRIMITIVE, init-value=0, base-type=BT_ZV_Ladeklappe_VerEntriegeln, compu {0=Cx0_Init (CM_ZV_Ladeklappe_VerEntriegeln_Cx0_Init), 1=Cx1_Ladeklappe_verriegeln (CM_ZV_Ladeklappe_VerEntriegeln_Cx1_Ladeklappe_verriegeln), 2=Cx2_Ladeklappe_entriegeln (CM_ZV_Ladeklappe_VerEntriegeln_Cx2_Ladeklappe_entriegeln), 3=Cx3_keine_Anforderung (CM_ZV_Ladeklappe_VerEntriegeln_Cx3_keine_Anforderung)}, range raw 0..3  # Ver- u. Entriegeln der Ladeklappe
          signal ZV_LadeklappenStatus_XIX_SAM_01_XIX_E3V_K2CANFD: start 14, 1 bit, little-endian, data-type-policy=OVERRIDE, i-signal-type=PRIMITIVE, init-value=0, base-type=BT_ZV_LadeklappenStatus, compu {0=Cx0_Ladeklappe_geschlossen (CM_ZV_LadeklappenStatus_Cx0_Ladeklappe_geschlossen), 1=Cx1_Ladeklappe_geoeffnet (CM_ZV_LadeklappenStatus_Cx1_Ladeklappe_geoeffnet)}, range raw 0..1  # Gibt den Staus der Ladeklappe aus
          signal ISignalVoid_SAM_01_XIX_E3V_K2CANFD_0: start 15, 1 bit, little-endian, system signal SignalVoid_SAM_01_0, data-type-policy=OVERRIDE, i-signal-type=PRIMITIVE, base-type=BT_SignalVoid
          signal ISignalVoid_SAM_01_XIX_E3V_K2CANFD_1: start 16, 8 bit, little-endian, system signal SignalVoid_SAM_01_1, data-type-policy=OVERRIDE, i-signal-type=PRIMITIVE, base-type=BT_SignalVoid
          signal ISignalVoid_SAM_01_XIX_E3V_K2CANFD_2: start 24, 5 bit, little-endian, system signal SignalVoid_SAM_01_2, data-type-policy=OVERRIDE, i-signal-type=PRIMITIVE, base-type=BT_SignalVoid
          signal SAM_Fehler_DC_LWR_XIX_SAM_01_XIX_E3V_K2CANFD: start 29, 1 bit, little-endian, data-type-policy=OVERRIDE, i-signal-type=PRIMITIVE, init-value=0, base-type=BT_SAM_Fehler_DC_LWR, invalid-value=Invalid_SAM_Fehler_DC_LWR_XIX_SAM_01_XIX_E3V_K2CANFD:1, compu {0=Cx0_kein_Fehler (CM_SAM_Fehler_DC_LWR_Cx0_kein_Fehler), 1=Cx1_Fehler (CM_SAM_Fehler_DC_LWR_Cx1_Fehler)}, range raw 0..1  # Fehler im DC-Steller
          signal BCM_Bremsbelag_Sensor_Rdw_XIX_SAM_01_XIX_E3V_K2CANFD: start 30, 2 bit, little-endian, data-type-policy=OVERRIDE, i-signal-type=PRIMITIVE, init-value=0, base-type=BT_BCM_Bremsbelag_Sensor_Rdw, compu {0=Cx0_OK (CM_BCM_Bremsbelag_Sensor_Rdw_Cx0_OK), 1=Cx1_Bremsbelag_unter_min_iID (CM_BCM_Bremsbelag_Sensor_Rdw_Cx1_Bremsbelag_unter_min_iID), 2=Cx2_Bremsbelag_unter_min_MOD (CM_BCM_Bremsbelag_Sensor_Rdw_Cx2_Bremsbelag_unter_min_MOD)}, range raw 0..2  # Fahrerinformation Warnfall RdW wenn ISO-Symbol (ggf. auch im Display) oder auch für US, wenn eigene BRAKE WARE- Symbolik vorhanden.
          signal BCM_Bremsbelag_Sensor_NAR_XIX_SAM_01_XIX_E3V_K2CANFD: start 32, 1 bit, little-endian, data-type-policy=OVERRIDE, i-signal-type=PRIMITIVE, init-value=0, base-type=BT_BCM_Bremsbelag_Sensor_NAR, compu {0=Cx0_OK (CM_BCM_Bremsbelag_Sensor_NAR_Cx0_OK), 1=Cx1_Bremsbelag_unter_min (CM_BCM_Bremsbelag_Sensor_NAR_Cx1_Bremsbelag_unter_min)}, range raw 0..1  # Fahrerinformation Warnfall US (sofern keine eigne BRAKE WARE- Symbolik vorhanden und daher die Gesetzeserfüllung über eine statische BKL-Ansteuerung erfolgen muss.
          signal BCM_Bremsbelag_Sensor_CND_XIX_SAM_01_XIX_E3V_K2CANFD: start 33, 1 bit, little-endian, data-type-policy=OVERRIDE, i-signal-type=PRIMITIVE, init-value=0, base-type=BT_BCM_Bremsbelag_Sensor_CND, compu {0=Cx0_OK (CM_BCM_Bremsbelag_Sensor_CND_Cx0_OK), 1=Cx1_Bremsbelag_unter_min (CM_BCM_Bremsbelag_Sensor_CND_Cx1_Bremsbelag_unter_min)}, range raw 0..1  # Fahrerinformation Warnfall CND wenn ISO-Symbol (ggf. auch im Display)
          signal KST_BSW_Klemme_15_HW_Ist_XIX_SAM_01_XIX_E3V_K2CANFD: start 34, 2 bit, little-endian, data-type-policy=OVERRIDE, i-signal-type=PRIMITIVE, init-value=0, base-type=BT_KST_BSW_Klemme_15_HW_Ist, invalid-value=Invalid_KST_BSW_Klemme_15_HW_Ist_XIX_SAM_01_XIX_E3V_K2CANFD:3, compu {0=Cx0_Klemme15HW_aus (CM_KST_BSW_Klemme_15_HW_Ist_Cx0_Klemme15HW_aus), 1=Cx1_Klemme15HW_ein (CM_KST_BSW_Klemme_15_HW_Ist_Cx1_Klemme15HW_ein), 3=Cx3_Fehler (CM_KST_BSW_Klemme_15_HW_Ist_Cx3_Fehler)}, range raw 0..3  # Spiegelung des Klemme 15 Hardware Status auf dem CAN, welcher im MEB durch das SAM gesetzt wird
          signal BRL_Bremslicht_Schalter_XIX_SAM_01_XIX_E3V_K2CANFD: start 36, 1 bit, little-endian, data-type-policy=OVERRIDE, i-signal-type=PRIMITIVE, init-value=0, base-type=BT_BRL_Bremslicht_Schalter, compu {0=Cx0_nicht_betaetigt (CM_BRL_Bremslicht_Schalter_Cx0_nicht_betaetigt), 1=Cx1_betaetigt (CM_BRL_Bremslicht_Schalter_Cx1_betaetigt)}, range raw 0..1  # Einlesen des Bremslicht-Schalters
          signal SAL_li1_Blinker_Status_XIX_SAM_01_XIX_E3V_K2CANFD: start 37, 1 bit, little-endian, data-type-policy=OVERRIDE, i-signal-type=PRIMITIVE, init-value=0, base-type=BT_SAL_li1_Blinker_Status, compu {0=Cx0_Blinker_aus (CM_SAL_li1_Blinker_Status_Cx0_Blinker_aus), 1=Cx1_Blinker_an (CM_SAL_li1_Blinker_Status_Cx1_Blinker_an)}, range raw 0..1  # Blinker-Statusüberwachung des SAM zur Erfüllung der funktionalen Sicherheit (Falschblinken, Blinken ohne Anforderung).
          signal SAL_re1_Blinker_Status_XIX_SAM_01_XIX_E3V_K2CANFD: start 38, 1 bit, little-endian, data-type-policy=OVERRIDE, i-signal-type=PRIMITIVE, init-value=0, base-type=BT_SAL_re1_Blinker_Status, compu {0=Cx0_Blinker_aus (CM_SAL_re1_Blinker_Status_Cx0_Blinker_aus), 1=Cx1_Blinker_an (CM_SAL_re1_Blinker_Status_Cx1_Blinker_an)}, range raw 0..1  # Blinker-Statusüberwachung des SAM zur Erfüllung der funktionalen Sicherheit (Falschblinken, Blinken ohne Anforderung).
          signal KST_BSW_Fehlermode2_XIX_SAM_01_XIX_E3V_K2CANFD: start 39, 1 bit, little-endian, data-type-policy=OVERRIDE, i-signal-type=PRIMITIVE, init-value=0, base-type=BT_KST_BSW_Fehlermode2, compu {0=Cx0_Aus (CM_KST_BSW_Fehlermode2_Cx0_Aus), 1=Cx1_Ein (CM_KST_BSW_Fehlermode2_Cx1_Ein)}, range raw 0..1  # Signal wird gesetzt, wenn das SAM einen klemmensteuerungs-relevanten Fehler diagnostiziert. Fehler, die das Weiterfahren mit der Anforderung eines zeitnahen Werkstattbesuches erlauben, werden in den Fehlermode 2 eingestuft.
          signal HW_Drehfalle_Tuer_HR_XIX_SAM_01_XIX_E3V_K2CANFD: start 40, 1 bit, little-endian, data-type-policy=OVERRIDE, i-signal-type=PRIMITIVE, init-value=0, base-type=BT_HW_Drehfalle_Tuer_HR, compu {0=Cx0_geschlossen (CM_HW_Drehfalle_Tuer_HR_Cx0_geschlossen), 1=Cx1_offen (CM_HW_Drehfalle_Tuer_HR_Cx1_offen)}, range raw 0..1  # Hardwaresignal der Drehfalle der Tür Hinten Rechts
          signal HW_Drehfalle_Tuer_HL_XIX_SAM_01_XIX_E3V_K2CANFD: start 41, 1 bit, little-endian, data-type-policy=OVERRIDE, i-signal-type=PRIMITIVE, init-value=0, base-type=BT_HW_Drehfalle_Tuer_HL, compu {0=Cx0_geschlossen (CM_HW_Drehfalle_Tuer_HL_Cx0_geschlossen), 1=Cx1_offen (CM_HW_Drehfalle_Tuer_HL_Cx1_offen)}, range raw 0..1  # Hardwaresignal der Drehfalle der Tür Hinten Links
          signal HW_Status_Schloss_verriegelt_HR_XIX_SAM_01_XIX_E3V_K2CANFD: start 42, 1 bit, little-endian, data-type-policy=OVERRIDE, i-signal-type=PRIMITIVE, init-value=0, base-type=BT_HW_Status_Schloss_verriegelt_HR, compu {0=Cx0_nicht_verriegelt (CM_HW_Status_Schloss_verriegelt_HR_Cx0_nicht_verriegelt), 1=Cx1_verriegelt (CM_HW_Status_Schloss_verriegelt_HR_Cx1_verriegelt)}, range raw 0..1  # Hardwaresignal Schlossstatus verriegelt
          signal HW_Status_Schloss_verriegelt_HL_XIX_SAM_01_XIX_E3V_K2CANFD: start 43, 1 bit, little-endian, data-type-policy=OVERRIDE, i-signal-type=PRIMITIVE, init-value=0, base-type=BT_HW_Status_Schloss_verriegelt_HL, compu {0=Cx0_nicht_verriegelt (CM_HW_Status_Schloss_verriegelt_HL_Cx0_nicht_verriegelt), 1=Cx1_verriegelt (CM_HW_Status_Schloss_verriegelt_HL_Cx1_verriegelt)}, range raw 0..1  # Hardwaresignal Schlossstatus verriegelt
          signal HW_Status_Schloss_gesafet_HR_XIX_SAM_01_XIX_E3V_K2CANFD: start 44, 1 bit, little-endian, data-type-policy=OVERRIDE, i-signal-type=PRIMITIVE, init-value=0, base-type=BT_HW_Status_Schloss_gesafet_HR, compu {0=Cx0_nicht_gesafet (CM_HW_Status_Schloss_gesafet_HR_Cx0_nicht_gesafet), 1=Cx1_gesafet (CM_HW_Status_Schloss_gesafet_HR_Cx1_gesafet)}, range raw 0..1  # HW-Signal Schlossstatus gesafet
          signal HW_Status_Schloss_gesafet_HL_XIX_SAM_01_XIX_E3V_K2CANFD: start 45, 1 bit, little-endian, data-type-policy=OVERRIDE, i-signal-type=PRIMITIVE, init-value=0, base-type=BT_HW_Status_Schloss_gesafet_HL, compu {0=Cx0_nicht_gesafet (CM_HW_Status_Schloss_gesafet_HL_Cx0_nicht_gesafet), 1=Cx1_gesafet (CM_HW_Status_Schloss_gesafet_HL_Cx1_gesafet)}, range raw 0..1  # HW-Signal Schlossstatus gesafet
          signal HW_Tankdeckel_offen_XIX_SAM_01_XIX_E3V_K2CANFD: start 46, 1 bit, little-endian, data-type-policy=OVERRIDE, i-signal-type=PRIMITIVE, init-value=0, base-type=BT_HW_Tankdeckel_offen, compu {0=Cx0_geschlossen (CM_HW_Tankdeckel_offen_Cx0_geschlossen), 1=Cx1_offen (CM_HW_Tankdeckel_offen_Cx1_offen)}, range raw 0..1  # Signal zum Erfassen des Status des Tankdeckels. Signal vom Aktor Steuergerät für die Auswertung im ZV-Master
          signal BCM_KiSi_Umschalt_gesperrt_XIX_SAM_01_XIX_E3V_K2CANFD: start 47, 1 bit, little-endian, data-type-policy=OVERRIDE, i-signal-type=PRIMITIVE, init-value=0, base-type=BT_BCM_KiSi_Umschalt_gesperrt, compu {0=Cx0_nicht_gesperrt (CM_BCM_KiSi_Umschalt_gesperrt_Cx0_nicht_gesperrt), 1=Cx1_gesperrt (CM_BCM_KiSi_Umschalt_gesperrt_Cx1_gesperrt)}, range raw 0..1  # Umschalten der Kindersicherung gesperrt
          signal Fronthaube_geoeffnet_XIX_SAM_01_XIX_E3V_K2CANFD: start 48, 1 bit, little-endian, data-type-policy=OVERRIDE, i-signal-type=PRIMITIVE, init-value=0, base-type=BT_Fronthaube_geoeffnet, compu {0=Cx0_geschlossen (CM_Fronthaube_geoeffnet_Cx0_geschlossen), 1=Cx1_geoeffnet (CM_Fronthaube_geoeffnet_Cx1_geoeffnet)}, range raw 0..1  # Information über den Status der Fronthaube
          signal Wischer_aktiv_XIX_SAM_01_XIX_E3V_K2CANFD: start 49, 1 bit, little-endian, data-type-policy=OVERRIDE, i-signal-type=PRIMITIVE, init-value=0, base-type=BT_Wischer_aktiv, compu {0=Cx0_inaktiv (CM_Wischer_aktiv_Cx0_inaktiv), 1=Cx1_aktiv (CM_Wischer_aktiv_Cx1_aktiv)}, range raw 0..1  # Frontwischermotor aktiv
          signal ISignalVoid_SAM_01_XIX_E3V_K2CANFD_3: start 50, 2 bit, little-endian, system signal SignalVoid_SAM_01_3, data-type-policy=OVERRIDE, i-signal-type=PRIMITIVE, base-type=BT_SignalVoid
          signal HW_HSB_erkannt_XIX_SAM_01_XIX_E3V_K2CANFD: start 52, 1 bit, little-endian, data-type-policy=OVERRIDE, i-signal-type=PRIMITIVE, init-value=0, base-type=BT_HW_HSB_erkannt, compu {0=Cx0_nicht_aktiv (CM_HW_HSB_erkannt_Cx0_nicht_aktiv), 1=Cx1_aktiv (CM_HW_HSB_erkannt_Cx1_aktiv)}, range raw 0..1  # Signal wird verwendet, um den DWA-Master einen Heckscheibenbruch zu signalisieren. Die Qualifizierung erfolgt im Sensorsteuergerät.
          signal HD_Hauptraste_XIX_SAM_01_XIX_E3V_K2CANFD: start 53, 1 bit, little-endian, data-type-policy=OVERRIDE, i-signal-type=PRIMITIVE, init-value=0, base-type=BT_HD_Hauptraste, compu {0=Cx0_geschlossen (CM_HD_Hauptraste_Cx0_geschlossen), 1=Cx1_offen (CM_HD_Hauptraste_Cx1_offen)}, range raw 0..1  # SBL-Schloss (MQB/MLBevo): Drehfalle Heckdeckel sonst (MQB): Hauptraste Heckdeckel
          signal HD_Vorraste_XIX_SAM_01_XIX_E3V_K2CANFD: start 54, 1 bit, little-endian, data-type-policy=OVERRIDE, i-signal-type=PRIMITIVE, init-value=0, base-type=BT_HD_Vorraste, compu {0=Cx0_geschlossen (CM_HD_Vorraste_Cx0_geschlossen), 1=Cx1_offen (CM_HD_Vorraste_Cx1_offen)}, range raw 0..1  # SBL_Schloss (MQB/MLBevo): Sperrklinke Heckdeckel sonst (MQB): Vorraste Heckdeckel
          signal KST_BSW_Klemmenhochschalten_Sper_XIX_SAM_01_XIX_E3V_K2CANFD: start 55, 1 bit, little-endian, data-type-policy=OVERRIDE, i-signal-type=PRIMITIVE, init-value=0, base-type=BT_KST_BSW_Klemmenhochschalten_Sper, compu {0=Cx0_nicht_gesperrt (CM_KST_BSW_Klemmenhochschalten_Sper_Cx0_nicht_gesperrt), 1=Cx1_gesperrt (CM_KST_BSW_Klemmenhochschalten_Sper_Cx1_gesperrt)}, range raw 0..1  # Hochschalten der Klemmen im SAM gesperrt
          signal BCM_Tankklappensteller_Fehler_XIX_SAM_01_XIX_E3V_K2CANFD: start 56, 1 bit, little-endian, data-type-policy=OVERRIDE, i-signal-type=PRIMITIVE, init-value=0, base-type=BT_BCM_Tankklappensteller_Fehler, invalid-value=Invalid_BCM_Tankklappensteller_Fehler_XIX_SAM_01_XIX_E3V_K2CANFD:1, compu {0=Cx0_kein_Fehler (CM_BCM_Tankklappensteller_Fehler_Cx0_kein_Fehler), 1=Cx1_Fehler (CM_BCM_Tankklappensteller_Fehler_Cx1_Fehler)}, range raw 0..1  # Fehler: nicht Funktionalität des Tankklappenstellers
          signal HW_HD_Taste_Innenraum_XIX_SAM_01_XIX_E3V_K2CANFD: start 57, 1 bit, little-endian, data-type-policy=OVERRIDE, i-signal-type=PRIMITIVE, init-value=0, base-type=BT_HW_HD_Taste_Innenraum, compu {0=Cx0_Innentaster_nicht_betaetigt (CM_HW_HD_Taste_Innenraum_Cx0_Innentaster_nicht_betaetigt), 1=Cx1_Innentaster_betaetigt (CM_HW_HD_Taste_Innenraum_Cx1_Innentaster_betaetigt)}, range raw 0..1  # Hardwaresignal des Heckdeckeltasters im Innenraum
          signal HW_Softtouch_betaetigt_XIX_SAM_01_XIX_E3V_K2CANFD: start 58, 1 bit, little-endian, data-type-policy=OVERRIDE, i-signal-type=PRIMITIVE, init-value=0, base-type=BT_HW_Softtouch_betaetigt, compu {0=Cx0_Softtouch_nicht_betaetigt (CM_HW_Softtouch_betaetigt_Cx0_Softtouch_nicht_betaetigt), 1=Cx1_Softtouch_betaetigt (CM_HW_Softtouch_betaetigt_Cx1_Softtouch_betaetigt)}, range raw 0..1  # Hardwaresignal des Softtouchs.
          signal ISignalVoid_SAM_01_XIX_E3V_K2CANFD_4: start 59, 3 bit, little-endian, system signal SignalVoid_SAM_01_4, data-type-policy=OVERRIDE, i-signal-type=PRIMITIVE, base-type=BT_SignalVoid
          signal KST_BSW_Not_Taster_betaetigt_XIX_SAM_01_XIX_E3V_K2CANFD: start 62, 1 bit, little-endian, data-type-policy=OVERRIDE, i-signal-type=PRIMITIVE, init-value=0, base-type=BT_KST_BSW_Not_Taster_betaetigt, compu {0=Cx0_nicht_betaetigt (CM_KST_BSW_Not_Taster_betaetigt_Cx0_nicht_betaetigt), 1=Cx1_betaetigt (CM_KST_BSW_Not_Taster_betaetigt_Cx1_betaetigt)}, range raw 0..1  # Not-Taster betätigt
          signal KST_BSW_ZAT_betaetigt_XIX_SAM_01_XIX_E3V_K2CANFD: start 63, 1 bit, little-endian, data-type-policy=OVERRIDE, i-signal-type=PRIMITIVE, init-value=0, base-type=BT_KST_BSW_ZAT_betaetigt, compu {0=Cx0_Aus (CM_KST_BSW_ZAT_betaetigt_Cx0_Aus), 1=Cx1_Ein (CM_KST_BSW_ZAT_betaetigt_Cx1_Ein)}, range raw 0..1  # Zündanlass-Taster (ZAT) betätigt
          mapping SG_SAM_01_XIX_E3V_K2CANFD: i-signal-group=SG_SAM_01_XIX_E3V_K2CANFD, transfer-property=TRIGGERED-WITHOUT-REPETITION
      frame SMLS_01_XIX_E3V_K2CANFD: id 0x3D4, from SAM, to SAM, frame-length=8, can-addressing-mode=STANDARD, can-frame-rx-behavior=CAN-FD, can-frame-tx-behavior=CAN-FD
        pdu SMLS_01_XIX_E3V_K2CANFD_E2E: length=8, minimum-delay=0.05, transmission-mode-true-timing=event-controlled-timing={number-of-repetitions=0, repetition-period=0.0}, unused-bit-pattern=0  # Fuer die Botschaft ist das Cyclic-Timing 1.0 zu verwenden.
          signal SMLS_01_CRC_XIX_SMLS_01_XIX_E3V_K2CANFD: start 0, 8 bit, little-endian, data-type-policy=OVERRIDE, i-signal-type=PRIMITIVE, base-type=BT_SMLS_01_CRC, compu {phys=raw for raw 0..255}, range phys 0..255, raw 0..255, to SAM(timeout 5 s)  # Für MLB: "Berechnung siehe Lastenheft "Kommunikationsabsicherung für FlexRay und CAN"" Ab MQB und MLBevo: "Berechnung siehe Lastenheft "End-to-End Kommunikationsabsicherung"" Endwerte siehe Begleitdokument "S-PDU Kennungsfolgen"
          signal SMLS_01_BZ_XIX_SMLS_01_XIX_E3V_K2CANFD: start 8, 4 bit, little-endian, data-type-policy=OVERRIDE, i-signal-type=PRIMITIVE, base-type=BT_SMLS_01_BZ, compu {phys=raw for raw 0..15}, range phys 0..15, raw 0..15, to SAM(timeout 5 s)  # 4bit Botschaftszaehler, wird mit jeder Sendebotschaft inkrementiert
          signal BH_Blinker_li_XIX_SMLS_01_XIX_E3V_K2CANFD: start 12, 1 bit, little-endian, data-type-policy=OVERRIDE, i-signal-type=PRIMITIVE, init-value=0, base-type=BT_BH_Blinker_li, compu {0=Cx0_nicht_betaetigt (CM_BH_Blinker_li_Cx0_nicht_betaetigt), 1=Cx1_Blinkerhebel_Pos_li_betaetigt (CM_BH_Blinker_li_Cx1_Blinkerhebel_Pos_li_betaetigt)}, range raw 0..1, to SAM(timeout 5 s)  # Blinkerhebel Richtung links
          signal BH_Blinker_re_XIX_SMLS_01_XIX_E3V_K2CANFD: start 13, 1 bit, little-endian, data-type-policy=OVERRIDE, i-signal-type=PRIMITIVE, init-value=0, base-type=BT_BH_Blinker_re, compu {0=Cx0_nicht_betaetigt (CM_BH_Blinker_re_Cx0_nicht_betaetigt), 1=Cx1_Blinkerhebel_Pos_re_betaetigt (CM_BH_Blinker_re_Cx1_Blinkerhebel_Pos_re_betaetigt)}, range raw 0..1, to SAM(timeout 5 s)  # Blinkerhebel Richtung rechts
          signal BH_Lichthupe_XIX_SMLS_01_XIX_E3V_K2CANFD: start 14, 1 bit, little-endian, data-type-policy=OVERRIDE, i-signal-type=PRIMITIVE, init-value=0, base-type=BT_BH_Lichthupe, compu {0=Cx0_nicht_betaetigt (CM_BH_Lichthupe_Cx0_nicht_betaetigt), 1=Cx1_Blinkerhebel_in_Richtung_Lichthupe_betaetigt (CM_BH_Lichthupe_Cx1_Blinkerhebel_in_Richtung_Lichthupe_betaetigt) (Blinkerhebel in Richtung Lichthupe betaetigt)}, range raw 0..1, to SAM(timeout 5 s)  # Betaetigung Lichthupe
          signal BH_Fernlicht_XIX_SMLS_01_XIX_E3V_K2CANFD: start 15, 1 bit, little-endian, data-type-policy=OVERRIDE, i-signal-type=PRIMITIVE, init-value=0, base-type=BT_BH_Fernlicht, compu {0=Cx0_nicht_betaetigt (CM_BH_Fernlicht_Cx0_nicht_betaetigt), 1=Cx1_Blinkerhebel_in_Richtung_Fernlicht_betaetigt (CM_BH_Fernlicht_Cx1_Blinkerhebel_in_Richtung_Fernlicht_betaetigt)}, range raw 0..1, to SAM(timeout 5 s)  # Betaetigung Fernlicht
          signal WH_Tipwischen_XIX_SMLS_01_XIX_E3V_K2CANFD: start 16, 1 bit, little-endian, data-type-policy=OVERRIDE, i-signal-type=PRIMITIVE, init-value=0, base-type=BT_WH_Tipwischen, compu {0=Cx0_nicht_betaetigt (CM_WH_Tipwischen_Cx0_nicht_betaetigt), 1=Cx1_betaetigt (CM_WH_Tipwischen_Cx1_betaetigt)}, range raw 0..1, to SAM(timeout 5 s)  # Wischerhebel: Tippwischen MQB A0/ PQ26: Bei Verbau LSS (kein SMLS): gespiegelter Wert zu Signal WH_WischerStufe1
          signal WH_Intervall_XIX_SMLS_01_XIX_E3V_K2CANFD: start 17, 1 bit, little-endian, data-type-policy=OVERRIDE, i-signal-type=PRIMITIVE, init-value=0, base-type=BT_WH_Intervall, compu {0=Cx0_aus (CM_WH_Intervall_Cx0_aus), 1=Cx1_Wischerhebel_in_Stellung_Intervall (CM_WH_Intervall_Cx1_Wischerhebel_in_Stellung_Intervall) (Wischerhebel in Stellung Intervall)}, range raw 0..1, to SAM(timeout 5 s)  # Wischerhebel: Stellung Intervall
          signal WH_WischerStufe1_XIX_SMLS_01_XIX_E3V_K2CANFD: start 18, 1 bit, little-endian, data-type-policy=OVERRIDE, i-signal-type=PRIMITIVE, init-value=0, base-type=BT_WH_WischerStufe1, compu {0=Cx0_aus (CM_WH_WischerStufe1_Cx0_aus), 1=Cx1_Wischerhebel_in_Stufe_Wischen_1 (CM_WH_WischerStufe1_Cx1_Wischerhebel_in_Stufe_Wischen_1) (Wischerhebel in Stufe Wischen 1)}, range raw 0..1, to SAM(timeout 5 s)  # Wischerhebel: Stufe Wischen 1
          signal WH_WischerStufe2_XIX_SMLS_01_XIX_E3V_K2CANFD: start 19, 1 bit, little-endian, data-type-policy=OVERRIDE, i-signal-type=PRIMITIVE, init-value=0, base-type=BT_WH_WischerStufe2, compu {0=Cx0_aus (CM_WH_WischerStufe2_Cx0_aus), 1=Cx1_Wischerhebel_in_Stufe_Wischen_2 (CM_WH_WischerStufe2_Cx1_Wischerhebel_in_Stufe_Wischen_2) (Wischerhebel in Stufe Wischen 2)}, range raw 0..1, to SAM(timeout 5 s)  # Wischerhebel: Stufe Wischen 2
          signal WH_Frontwaschen_XIX_SMLS_01_XIX_E3V_K2CANFD: start 20, 1 bit, little-endian, data-type-policy=OVERRIDE, i-signal-type=PRIMITIVE, init-value=0, base-type=BT_WH_Frontwaschen, compu {0=Cx0_aus (CM_WH_Frontwaschen_Cx0_aus), 1=Cx1_Wischerhebel_in_Stellung_Wisch_Wasch_vorne (CM_WH_Frontwaschen_Cx1_Wischerhebel_in_Stellung_Wisch_Wasch_vorne) (Wischerhebel in Stellung Wisch Wasch vorne)}, range raw 0..1, to SAM(timeout 5 s)  # Wischerhebel: Stellung Wisch Wasch vorne
          signal WH_Heckintervall_XIX_SMLS_01_XIX_E3V_K2CANFD: start 21, 1 bit, little-endian, data-type-policy=OVERRIDE, i-signal-type=PRIMITIVE, init-value=0, base-type=BT_WH_Heckintervall, compu {0=Cx0_nicht_betaetigt (CM_WH_Heckintervall_Cx0_nicht_betaetigt), 1=Cx1_Wischerhebel_in_Stellung_Heckintervall (CM_WH_Heckintervall_Cx1_Wischerhebel_in_Stellung_Heckintervall) (Wischerhebel in Stellung Heckintervall)}, range raw 0..1, to SAM(timeout 5 s)  # Wischerhebel: Stellung Heckintervall
          signal WH_Heckwaschen_XIX_SMLS_01_XIX_E3V_K2CANFD: start 22, 1 bit, little-endian, data-type-policy=OVERRIDE, i-signal-type=PRIMITIVE, init-value=0, base-type=BT_WH_Heckwaschen, compu {0=Cx0_nicht_betaetigt (CM_WH_Heckwaschen_Cx0_nicht_betaetigt), 1=Cx1_Wischerhebel_in_Stellung_Wisch_Wasch_hinten (CM_WH_Heckwaschen_Cx1_Wischerhebel_in_Stellung_Wisch_Wasch_hinten) (Wischerhebel in Stellung Wisch Wasch hinten)}, range raw 0..1, to SAM(timeout 5 s)  # Wischerhebel: Stellung Wisch Wasch hinten
          signal WH_Intervallstufen_XIX_SMLS_01_XIX_E3V_K2CANFD: start 23, 4 bit, little-endian, data-type-policy=OVERRIDE, i-signal-type=PRIMITIVE, init-value=0, base-type=BT_WH_Intervallstufen, invalid-value=Invalid_WH_Intervallstufen_XIX_SMLS_01_XIX_E3V_K2CANFD:15, compu {0=Cx0_Init_Default (CM_WH_Intervallstufen_Cx0_Init_Default) (Init / Default), 1=Cx1_Intervallstufe_1 (CM_WH_Intervallstufen_Cx1_Intervallstufe_1) (Intervallstufe 1), 5=Cx5_Intervallstufe_2 (CM_WH_Intervallstufen_Cx5_Intervallstufe_2) (Intervallstufe 2), 9=Cx9_Intervallstufe_3 (CM_WH_Intervallstufen_Cx9_Intervallstufe_3) (Intervallstufe 3), 13=Cxd_Intervallstufe_4 (CM_WH_Intervallstufen_Cxd_Intervallstufe_4) (Intervallstufe 4), 15=Cxf_Fehler (CM_WH_Intervallstufen_Cxf_Fehler)}, range raw 0..15, to SAM(timeout 5 s)  # Wischerhebel: Stellung Intervallstufen
          signal FAS_Taster_XIX_SMLS_01_XIX_E3V_K2CANFD: start 27, 1 bit, little-endian, data-type-policy=OVERRIDE, i-signal-type=PRIMITIVE, init-value=0, base-type=BT_FAS_Taster, compu {0=Cx0_nicht_betaetigt (CM_FAS_Taster_Cx0_nicht_betaetigt), 1=Cx1_betaetigt (CM_FAS_Taster_Cx1_betaetigt)}, range raw 0..1, to SAM(timeout 5 s)  # Betaetigung FAS Taster
          signal FAS_Taster_Fehler_XIX_SMLS_01_XIX_E3V_K2CANFD: start 28, 1 bit, little-endian, data-type-policy=OVERRIDE, i-signal-type=PRIMITIVE, init-value=0, base-type=BT_FAS_Taster_Fehler, invalid-value=Invalid_FAS_Taster_Fehler_XIX_SMLS_01_XIX_E3V_K2CANFD:1, compu {0=Cx0_kein_Fehler (CM_FAS_Taster_Fehler_Cx0_kein_Fehler), 1=Cx1_Fehler (CM_FAS_Taster_Fehler_Cx1_Fehler)}, range raw 0..1  # Fehlerstatus FAS Taster
          signal SMLS_Hupe_XIX_SMLS_01_XIX_E3V_K2CANFD: start 29, 1 bit, little-endian, data-type-policy=OVERRIDE, i-signal-type=PRIMITIVE, init-value=0, base-type=BT_SMLS_Hupe, compu {0=Cx0_nicht_betaetigt (CM_SMLS_Hupe_Cx0_nicht_betaetigt), 1=Cx1_Hupe_gedrueckt (CM_SMLS_Hupe_Cx1_Hupe_gedrueckt)}, range raw 0..1, to SAM(timeout 5 s)  # Betaetigung Hupe
          signal LRH_On_Off_XIX_SMLS_01_XIX_E3V_K2CANFD: start 30, 2 bit, little-endian, data-type-policy=OVERRIDE, i-signal-type=PRIMITIVE, init-value=0, base-type=BT_LRH_On_Off, invalid-value=Invalid_LRH_On_Off_XIX_SMLS_01_XIX_E3V_K2CANFD:3, compu {0=Cx0_LRH_aus_keine_Anzeige (CM_LRH_On_Off_Cx0_LRH_aus_keine_Anzeige) (LRH_aus__keine Anzeige), 1=Cx1_LRH_aus (CM_LRH_On_Off_Cx1_LRH_aus), 2=Cx2_LRH_ein (CM_LRH_On_Off_Cx2_LRH_ein), 3=Cx3_Fehler (CM_LRH_On_Off_Cx3_Fehler)}, range raw 0..3, to SAM(timeout 5 s)  # Status Lenkradheizung
          signal LSS_Tastencode_XIX_SMLS_01_XIX_E3V_K2CANFD: start 32, 8 bit, little-endian, data-type-policy=OVERRIDE, i-signal-type=PRIMITIVE, init-value=0, base-type=BT_LSS_Tastencode, compu {0=Cx0_Key_Released_No_Key (CM_LSS_Tastencode_Cx0_Key_Released_No_Key) (Key_Released__No_Key), 4=Cx4_Up (CM_LSS_Tastencode_Cx4_Up), 5=Cx5_Down (CM_LSS_Tastencode_Cx5_Down), 7=Cx7_OK_ThumbWheel_Button (CM_LSS_Tastencode_Cx7_OK_ThumbWheel_Button) (OK__ThumbWheel_Button)}, range raw 0..7, to SAM(timeout 5 s)  # 0x00 = No key pressed / key released 0x01 = Menu 0x02 = Menu Up / Next Screen 0x03 = Menu Down / Previous Screen 0x04 = Up 0x05 = Down 0x06 = Up / Down ThumbWheel 0x07 = OK (ThumbWheel-Button) 0x08 = Cancel / Escape 0x09..0x0F = reserved for further menu controls 0x10 = Volume Up 0x11 = Volume Down 0x12 = Volume Up / Down ThumbWheel 0x13 = Volume-ThumbWheel-Button 0x14 = Audio Source 0x15 = Arrow A Up / Right 0x16 = Arrow A Down / Left 0x17 = Arrow B Up / Right 0x18 = Arrow B Down / Left 0x19 = PTT (Push To Talk) 0x1A = PTT Cancel 0x1B = Route Info 0x1C = Hook 0x1D = Hang Up 0x1E = Off Hook 0x1F = Light On / Off 0x20 = Mute 0x21 = Joker1 0x22 = Joker2 0x23..0xEF = reserved for further function controls 0xF0 = Startup_Reset
          signal LRH_aktiv_XIX_SMLS_01_XIX_E3V_K2CANFD: start 40, 1 bit, little-endian, data-type-policy=OVERRIDE, i-signal-type=PRIMITIVE, init-value=0, base-type=BT_LRH_aktiv, compu {0=Cx0_inaktiv (CM_LRH_aktiv_Cx0_inaktiv), 1=Cx1_aktiv (CM_LRH_aktiv_Cx1_aktiv)}, range raw 0..1, to SAM(timeout 5 s)  # Signal gibt an, ob ein Heizstrom durch die Lenkradheizung fließt. Es dient der Auswertung durch das Energiemanagement.
          signal SMLS_P_verriegelt_XIX_SMLS_01_XIX_E3V_K2CANFD: start 41, 2 bit, little-endian, data-type-policy=OVERRIDE, i-signal-type=PRIMITIVE, init-value=0, base-type=BT_SMLS_P_verriegelt, invalid-value=Invalid_SMLS_P_verriegelt_XIX_SMLS_01_XIX_E3V_K2CANFD:3, compu {0=Cx0_Init (CM_SMLS_P_verriegelt_Cx0_Init), 1=Cx1_nicht_verriegelt (CM_SMLS_P_verriegelt_Cx1_nicht_verriegelt), 2=Cx2_verriegelt (CM_SMLS_P_verriegelt_Cx2_verriegelt), 3=Cx3_Fehler (CM_SMLS_P_verriegelt_Cx3_Fehler)}, range raw 0..3  # Signal stellt den Status des Signals P-verriegelt auf den Fahrzeugbus zur Verfügung. Nutzer sind z.B. die ELV, die das Signal für die Verriegelung benötigt und die Funktion Verlassenswarnung, die den Fahrer beim Verrollen des Fahrzeugs warnt.
          signal SMLS_P_verriegelt_plausibel_XIX_SMLS_01_XIX_E3V_K2CANFD: start 43, 1 bit, little-endian, data-type-policy=OVERRIDE, i-signal-type=PRIMITIVE, init-value=0, base-type=BT_SMLS_P_verriegelt_plausibel, compu {0=Cx0_unplausibel (CM_SMLS_P_verriegelt_plausibel_Cx0_unplausibel), 1=Cx1_plausibel (CM_SMLS_P_verriegelt_plausibel_Cx1_plausibel)}, range raw 0..1  # Signal stellt den Plausibilisierungstatus des Signals p_verriegelt auf den Fahrzeugbus zur Verfügung. Eine Plausibilität muss explizit erkannt werden. Initial wird "unplausibel" gesendet. Ein plausibles Signal wird erkannt, wenn p_verriegelt plausibel gegenüber Geschwindigkeit oder der Wählhebelposition ist. Nutzer des Signals ist die Funktion Verlassenskonzept mit der Automatischen Klemmenabschaltung.
          signal WH_SRA_XIX_SMLS_01_XIX_E3V_K2CANFD: start 44, 1 bit, little-endian, data-type-policy=OVERRIDE, i-signal-type=PRIMITIVE, init-value=0, base-type=BT_WH_SRA, compu {0=Cx0_SRA_Aus (CM_WH_SRA_Cx0_SRA_Aus), 1=Cx1_SRA_Ein (CM_WH_SRA_Cx1_SRA_Ein)}, range raw 0..1  # Scheinwerferreinigungsanlage derzeit nur bei PAG umgesetzt
          signal WH_Wischer_Fehler_XIX_SMLS_01_XIX_E3V_K2CANFD: start 45, 1 bit, little-endian, data-type-policy=OVERRIDE, i-signal-type=PRIMITIVE, init-value=0, base-type=BT_WH_Wischer_Fehler, invalid-value=Invalid_WH_Wischer_Fehler_XIX_SMLS_01_XIX_E3V_K2CANFD:1, compu {0=Cx0_kein_Fehler (CM_WH_Wischer_Fehler_Cx0_kein_Fehler), 1=Cx1_Fehler (CM_WH_Wischer_Fehler_Cx1_Fehler)}, range raw 0..1, to SAM(timeout 5 s)  # Anzeige, ob am Lenkstockschalter ein Fehler anliegt. Notwendig aufgrund ASIL-Einstufung
          signal BH_Blinker_Fehler_XIX_SMLS_01_XIX_E3V_K2CANFD: start 46, 1 bit, little-endian, data-type-policy=OVERRIDE, i-signal-type=PRIMITIVE, init-value=0, base-type=BT_BH_Blinker_Fehler, invalid-value=Invalid_BH_Blinker_Fehler_XIX_SMLS_01_XIX_E3V_K2CANFD:1, compu {0=Cx0_kein_Fehler (CM_BH_Blinker_Fehler_Cx0_kein_Fehler), 1=Cx1_Fehler (CM_BH_Blinker_Fehler_Cx1_Fehler)}, range raw 0..1, to SAM(timeout 5 s)  # Anzeige, ob am Lenkstockschalter ein Fehler anliegt. Notwendig aufgrund ASIL-Einstufung
          signal SMLS_PTT_XIX_SMLS_01_XIX_E3V_K2CANFD: start 47, 1 bit, little-endian, data-type-policy=OVERRIDE, i-signal-type=PRIMITIVE, init-value=0, base-type=BT_SMLS_PTT, compu {0=Cx0_nicht_betaetigt (CM_SMLS_PTT_Cx0_nicht_betaetigt), 1=Cx1_PTT_gedrueckt (CM_SMLS_PTT_Cx1_PTT_gedrueckt)}, range raw 0..1  # Betaetigung PTT
          signal WH_Tipwischen_lang_XIX_SMLS_01_XIX_E3V_K2CANFD: start 48, 1 bit, little-endian, data-type-policy=OVERRIDE, i-signal-type=PRIMITIVE, init-value=0, base-type=BT_WH_Tipwischen_lang, compu {0=Cx0_nicht_betaetigt (CM_WH_Tipwischen_lang_Cx0_nicht_betaetigt), 1=Cx1_betaetigt (CM_WH_Tipwischen_lang_Cx1_betaetigt)}, range raw 0..1  # Wischerhebel: Tippwischen lang (dient zur Auswertung für die Unterscheidung Tippwischen oder Serviceposition Wischer)
          signal ISignalVoid_SMLS_01_XIX_E3V_K2CANFD_0: start 49, 7 bit, little-endian, system signal SignalVoid_SMLS_01_0, data-type-policy=OVERRIDE, i-signal-type=PRIMITIVE, base-type=BT_SignalVoid
          signal ISignalVoid_SMLS_01_XIX_E3V_K2CANFD_1: start 56, 8 bit, little-endian, system signal SignalVoid_SMLS_01_1, data-type-policy=OVERRIDE, i-signal-type=PRIMITIVE, base-type=BT_SignalVoid
          mapping SG_SMLS_01_XIX_E3V_K2CANFD: i-signal-group=SG_SMLS_01_XIX_E3V_K2CANFD, transfer-property=TRIGGERED-WITHOUT-REPETITION
      frame SOK_FoD_BCM_Req_Chal_06_XIX_E3V_K2CANFD: id 0x12E0200E, from SAM, frame-length=8, can-addressing-mode=EXTENDED, can-frame-rx-behavior=CAN-FD, can-frame-tx-behavior=CAN-FD
        pdu SOK_FoD_BCM_Req_Chal_06_XIX_E3V_K2CANFD: length=8, minimum-delay=0.05, transmission-mode-true-timing=event-controlled-timing={number-of-repetitions=0, repetition-period=0.0}, unused-bit-pattern=0
          signal SOK_FoD_BCM1_Req_Challenge_XIX_SOK_FoD_BCM_Req_Chal_06_XIX_E3V_K2CANFD: start 0, 64 bit, opaque, data-type-policy=OVERRIDE, i-signal-type=ARRAY, base-type=BT_SOK_FoD_BCM1_Req_Challenge, compu {phys=raw for raw 0..18446744073709551615; unit Unit_None}, range phys 0..18446744073709551615 Unit_None, raw 0..18446744073709551615, unit=Unit_None, transfer-property=TRIGGERED-ON-CHANGE-WITHOUT-REPETITION  # Challenge im Rahmen des SOK Challenge-Response Protokolls. Geschützte Funktion: Function on Demand
      frame SOK_FoD_BCM_Resp_Chal_06_XIX_E3V_K2CANFD: id 0x12E2300E, to SAM, frame-length=8, can-addressing-mode=EXTENDED, can-frame-rx-behavior=CAN-FD, can-frame-tx-behavior=CAN-FD
        pdu SOK_FoD_BCM_Resp_Chal_06_XIX_E3V_K2CANFD: length=8, minimum-delay=0.05, transmission-mode-true-timing=event-controlled-timing={number-of-repetitions=0, repetition-period=0.0}, unused-bit-pattern=0
          signal SOK_FoD_BCM1_Resp_Challenge_XIX_SOK_FoD_BCM_Resp_Chal_06_XIX_E3V_K2CANFD: start 0, 64 bit, opaque, data-type-policy=OVERRIDE, i-signal-type=ARRAY, base-type=BT_SOK_FoD_BCM1_Resp_Challenge, compu {phys=raw for raw 0..18446744073709551615; unit Unit_None}, range phys 0..18446744073709551615 Unit_None, raw 0..18446744073709551615, unit=Unit_None, transfer-property=TRIGGERED-ON-CHANGE-WITHOUT-REPETITION, to SAM  # Challenge im Rahmen des SOK Challenge-Response Protokolls. Geschützte Funktion: Function on Demand
      frame SOK_KST_BCM_Chal_05_XIX_E3V_K2CANFD: id 0x12E0100E, from SAM, frame-length=8, can-addressing-mode=EXTENDED, can-frame-rx-behavior=CAN-FD, can-frame-tx-behavior=CAN-FD
        pdu SOK_KST_BCM_Chal_05_XIX_E3V_K2CANFD: length=8, minimum-delay=0.02, transmission-mode-true-timing=event-controlled-timing={number-of-repetitions=0, repetition-period=0.0}, unused-bit-pattern=0
          signal SOK_KST_Challenge_XIX_SOK_KST_BCM_Chal_05_XIX_E3V_K2CANFD: start 0, 64 bit, opaque, data-type-policy=OVERRIDE, i-signal-type=ARRAY, base-type=BT_SOK_KST_Challenge, compu {phys=raw for raw 0..18446744073709551615; unit Unit_None}, range phys 0..18446744073709551615 Unit_None, raw 0..18446744073709551615, unit=Unit_None, transfer-property=TRIGGERED-ON-CHANGE-WITHOUT-REPETITION  # Challenge im Rahmen des SOK Challenge-Response Protokolls. Geschützte Funktion: Klemmensteuerung
      frame SOK_KST_BCM_Resp_05_SOK_XIX_E3V_K2CANFD: id 0x12E2200E, to SAM, frame-length=8, can-addressing-mode=EXTENDED, can-frame-rx-behavior=CAN-FD, can-frame-tx-behavior=CAN-FD
        secured i pdu SOK_KST_BCM_Resp_05_SOK_XIX_E3V_K2CANFD:
          length=8
          authentication-props=SecureCommunicationAuthenticationProps_XIX_32
          freshness-props=SecureCommunicationFreshnessProps
          payload=PT_SOK_KST_BCM_Resp_05
          secure-communication-props={auth-data-freshness-length=0, auth-data-freshness-start-position=0, auth-info-tx-length=32, authentication-build-attempts=1, authentication-retries=1, data-id=50, freshness-value-id=0, freshness-value-length=64, freshness-value-tx-length=0}
          use-as-cryptographic-i-pdu=false
      frame SOK_NoAuthenticTime_01_XIX_E3V_K2CANFD: id 0x1A5555AC, to SAM, frame-length=8, can-addressing-mode=EXTENDED, can-frame-rx-behavior=CAN-FD, can-frame-tx-behavior=CAN-FD
        pdu SOK_NoAuthenticTime_01_XIX_E3V_K2CANFD: length=8, minimum-delay=0.1, transmission-mode-true-timing={cyclic-timing={time-offset=0.0, time-period=1.0}, event-controlled-timing={number-of-repetitions=0, repetition-period=0.0}}, unused-bit-pattern=0
          signal SOK_ungeschuetzte_Zeit_XIX_SOK_NoAuthenticTime_01_XIX_E3V_K2CANFD: start 8, 56 bit, opaque, data-type-policy=OVERRIDE, i-signal-type=ARRAY, base-type=BT_SOK_ungeschuetzte_Zeit, compu {0=Cx0_Init (CM_SOK_ungeschuetzte_Zeit_Cx0_Init), phys=raw for raw 1..72057594037927935; unit Unit_None}, range phys 1..72057594037927935 Unit_None, raw 0..72057594037927935, unit=Unit_None, transfer-property=TRIGGERED-ON-CHANGE-WITHOUT-REPETITION, to SAM(timeout 5 s)  # Periodisch verschickter SOK Zeitwert des SOK Zeitmasters als Referenzzeit zur Erkennung von Clockjitter durch andere SOK Teilnehmer. Der Empfang dieses Signals ist verpflichtend für jedes Steuergerät, das durch die authentische Broadcast Funktionalität von SOK geschützte Daten versendet oder empfängt.
      frame SOK_ZV_HBFS_BCM_Chal_04_XIX_E3V_K2CANFD: id 0x7F8200E, from SAM, frame-length=8, can-addressing-mode=EXTENDED, can-frame-rx-behavior=CAN-FD, can-frame-tx-behavior=CAN-FD
        pdu SOK_ZV_HBFS_BCM_Chal_04_XIX_E3V_K2CANFD: length=8, minimum-delay=0.01, transmission-mode-true-timing=event-controlled-timing={number-of-repetitions=0, repetition-period=0.0}, unused-bit-pattern=0
          signal SOK_ZV_HBFS_Challenge_XIX_SOK_ZV_HBFS_BCM_Chal_04_XIX_E3V_K2CANFD: start 0, 64 bit, opaque, data-type-policy=OVERRIDE, i-signal-type=ARRAY, base-type=BT_SOK_ZV_HBFS_Challenge, compu {phys=raw for raw 0..18446744073709551615; unit Unit_None}, range phys 0..18446744073709551615 Unit_None, raw 0..18446744073709551615, unit=Unit_None, transfer-property=TRIGGERED-ON-CHANGE-WITHOUT-REPETITION  # Challenge im Rahmen des SOK Challenge-Response Protokolls. Geschützte Funktion: Fahrzeugentriegelung
      frame SOK_ZV_HBFS_BCM_Resp_04_SOK_XIX_E3V_K2CANFD: id 0x7FA200E, to SAM, frame-length=8, can-addressing-mode=EXTENDED, can-frame-rx-behavior=CAN-FD, can-frame-tx-behavior=CAN-FD
        secured i pdu SOK_ZV_HBFS_BCM_Resp_04_SOK_XIX_E3V_K2CANFD:
          length=8
          authentication-props=SecureCommunicationAuthenticationProps_XIX_32
          freshness-props=SecureCommunicationFreshnessProps
          payload=PT_SOK_ZV_HBFS_BCM_Resp_04
          secure-communication-props={auth-data-freshness-length=0, auth-data-freshness-start-position=0, auth-info-tx-length=32, authentication-build-attempts=1, authentication-retries=1, data-id=62, freshness-value-id=1, freshness-value-length=64, freshness-value-tx-length=0}
          use-as-cryptographic-i-pdu=false
      frame SOK_ZV_HFS_BCM_Chal_03_XIX_E3V_K2CANFD: id 0x7F8100E, from SAM, frame-length=8, can-addressing-mode=EXTENDED, can-frame-rx-behavior=CAN-FD, can-frame-tx-behavior=CAN-FD
        pdu SOK_ZV_HFS_BCM_Chal_03_XIX_E3V_K2CANFD: length=8, minimum-delay=0.01, transmission-mode-true-timing=event-controlled-timing={number-of-repetitions=0, repetition-period=0.0}, unused-bit-pattern=0
          signal SOK_ZV_HFS_Challenge_XIX_SOK_ZV_HFS_BCM_Chal_03_XIX_E3V_K2CANFD: start 0, 64 bit, opaque, data-type-policy=OVERRIDE, i-signal-type=ARRAY, base-type=BT_SOK_ZV_HFS_Challenge, compu {phys=raw for raw 0..18446744073709551615; unit Unit_None}, range phys 0..18446744073709551615 Unit_None, raw 0..18446744073709551615, unit=Unit_None, transfer-property=TRIGGERED-ON-CHANGE-WITHOUT-REPETITION  # Challenge im Rahmen des SOK Challenge-Response Protokolls. Geschützte Funktion: Fahrzeugentriegelung
      frame SOK_ZV_HFS_BCM_Resp_03_SOK_XIX_E3V_K2CANFD: id 0x7FA100E, to SAM, frame-length=8, can-addressing-mode=EXTENDED, can-frame-rx-behavior=CAN-FD, can-frame-tx-behavior=CAN-FD
        secured i pdu SOK_ZV_HFS_BCM_Resp_03_SOK_XIX_E3V_K2CANFD:
          length=8
          authentication-props=SecureCommunicationAuthenticationProps_XIX_32
          freshness-props=SecureCommunicationFreshnessProps
          payload=PT_SOK_ZV_HFS_BCM_Resp_03
          secure-communication-props={auth-data-freshness-length=0, auth-data-freshness-start-position=0, auth-info-tx-length=32, authentication-build-attempts=1, authentication-retries=1, data-id=61, freshness-value-id=2, freshness-value-length=64, freshness-value-tx-length=0}
          use-as-cryptographic-i-pdu=false
      frame SOK_ZV_HW_BCM_Chal_02_XIX_E3V_K2CANFD: id 0x7F8000E, from SAM, frame-length=8, can-addressing-mode=EXTENDED, can-frame-rx-behavior=CAN-FD, can-frame-tx-behavior=CAN-FD
        pdu SOK_ZV_HW_BCM_Chal_02_XIX_E3V_K2CANFD: length=8, minimum-delay=0.01, transmission-mode-true-timing=event-controlled-timing={number-of-repetitions=0, repetition-period=0.0}, unused-bit-pattern=0
          signal SOK_ZV_HW_Challenge_XIX_SOK_ZV_HW_BCM_Chal_02_XIX_E3V_K2CANFD: start 0, 64 bit, opaque, data-type-policy=OVERRIDE, i-signal-type=ARRAY, base-type=BT_SOK_ZV_HW_Challenge, compu {phys=raw for raw 0..18446744073709551615; unit Unit_None}, range phys 0..18446744073709551615 Unit_None, raw 0..18446744073709551615, unit=Unit_None, transfer-property=TRIGGERED-ON-CHANGE-WITHOUT-REPETITION  # Challenge im Rahmen des SOK Challenge-Response Protokolls. Geschützte Funktion: Fahrzeugentriegelung
      frame SOK_ZV_HW_BCM_Resp_02_SOK_XIX_E3V_K2CANFD: id 0x7FA000E, to SAM, frame-length=8, can-addressing-mode=EXTENDED, can-frame-rx-behavior=CAN-FD, can-frame-tx-behavior=CAN-FD
        secured i pdu SOK_ZV_HW_BCM_Resp_02_SOK_XIX_E3V_K2CANFD:
          length=8
          authentication-props=SecureCommunicationAuthenticationProps_XIX_32
          freshness-props=SecureCommunicationFreshnessProps
          payload=PT_SOK_ZV_HW_BCM_Resp_02
          secure-communication-props={auth-data-freshness-length=0, auth-data-freshness-start-position=0, auth-info-tx-length=32, authentication-build-attempts=1, authentication-retries=1, data-id=63, freshness-value-id=3, freshness-value-length=64, freshness-value-tx-length=0}
          use-as-cryptographic-i-pdu=false
      frame SOK_ZV_Rueck_HW_Gateway_Chal_01_XIX_E3V_K2CANFD: id 0x7F80010, to SAM, frame-length=8, can-addressing-mode=EXTENDED, can-frame-rx-behavior=CAN-FD, can-frame-tx-behavior=CAN-FD
        pdu SOK_ZV_Rueck_HW_Gateway_Chal_01_XIX_E3V_K2CANFD: length=8, minimum-delay=0.01, transmission-mode-true-timing=event-controlled-timing={number-of-repetitions=0, repetition-period=0.0}, unused-bit-pattern=0
          signal SOK_ZV_Rueck_HW_Challenge_XIX_SOK_ZV_Rueck_HW_Gateway_Chal_01_XIX_E3V_K2CANFD: start 0, 64 bit, opaque, data-type-policy=OVERRIDE, i-signal-type=ARRAY, base-type=BT_SOK_ZV_Rueck_HW_Challenge, compu {phys=raw for raw 0..18446744073709551615; unit Unit_None}, range phys 0..18446744073709551615 Unit_None, raw 0..18446744073709551615, unit=Unit_None, transfer-property=TRIGGERED-ON-CHANGE-WITHOUT-REPETITION, to SAM  # Challenge im Rahmen des SOK Challenge-Response Protokolls. Geschützte Funktion: Fahrzeugentriegelung
      frame SOK_ZV_Rueck_HW_Gateway_Resp_01_SOK_XIX_E3V_K2CANFD: id 0x7FA0010, from SAM, frame-length=8, can-addressing-mode=EXTENDED, can-frame-rx-behavior=CAN-FD, can-frame-tx-behavior=CAN-FD
        secured i pdu SOK_ZV_Rueck_HW_Gateway_Resp_01_SOK_XIX_E3V_K2CANFD:
          length=8
          authentication-props=SecureCommunicationAuthenticationProps_XIX_32
          freshness-props=SecureCommunicationFreshnessProps
          payload=PT_SOK_ZV_Rueck_HW_Gateway_Resp_01
          secure-communication-props={auth-data-freshness-length=0, auth-data-freshness-start-position=0, auth-info-tx-length=32, authentication-build-attempts=1, authentication-retries=1, data-id=68, freshness-value-id=0, freshness-value-length=64, freshness-value-tx-length=0}
          use-as-cryptographic-i-pdu=false
      frame SoSe_01_XIX_E3V_K2CANFD: id 0x5BB, from SAM, frame-length=8, can-addressing-mode=STANDARD, can-frame-rx-behavior=CAN-FD, can-frame-tx-behavior=CAN-FD
        pdu SoSe_01_XIX_E3V_K2CANFD: length=8, transmission-mode-true-timing=cyclic-timing={time-offset=0.0, time-period=0.5}, unused-bit-pattern=0
          signal SoSe_SunInt_2D_Li_XIX_SoSe_01_XIX_E3V_K2CANFD: start 0, 8 bit, little-endian, data-type-policy=OVERRIDE, i-signal-type=PRIMITIVE, init-value=254, base-type=BT_SoSe_SunInt_2D_Li, invalid-value=Invalid_SoSe_SunInt_2D_Li_XIX_SoSe_01_XIX_E3V_K2CANFD:255, compu {phys=raw*5 for raw 0..240, 254=Cxfe_Init (CM_SoSe_SunInt_2D_Li_Cxfe_Init), 255=Cxff_Fehler (CM_SoSe_SunInt_2D_Li_Cxff_Fehler); unit Unit_WattPerMeterSquar}, range phys 0..1200 Unit_WattPerMeterSquar, raw 0..255, unit=Unit_WattPerMeterSquar, transfer-property=PENDING  # Sonnenintensität links (2D Sensor)
          signal SoSe_SunInt_2D_Re_XIX_SoSe_01_XIX_E3V_K2CANFD: start 8, 8 bit, little-endian, data-type-policy=OVERRIDE, i-signal-type=PRIMITIVE, init-value=254, base-type=BT_SoSe_SunInt_2D_Re, invalid-value=Invalid_SoSe_SunInt_2D_Re_XIX_SoSe_01_XIX_E3V_K2CANFD:255, compu {phys=raw*5 for raw 0..240, 254=Cxfe_Init (CM_SoSe_SunInt_2D_Re_Cxfe_Init), 255=Cxff_Fehler (CM_SoSe_SunInt_2D_Re_Cxff_Fehler); unit Unit_WattPerMeterSquar}, range phys 0..1200 Unit_WattPerMeterSquar, raw 0..255, unit=Unit_WattPerMeterSquar, transfer-property=PENDING  # Sonnenintensität rechts (2D Sensor)
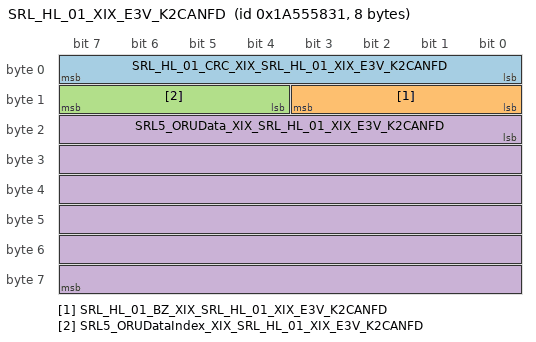
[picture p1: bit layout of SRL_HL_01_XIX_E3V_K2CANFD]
      frame SRL_HL_01_XIX_E3V_K2CANFD: id 0x1A555831, to SAM, frame-length=8, can-addressing-mode=EXTENDED, can-frame-rx-behavior=CAN-FD, can-frame-tx-behavior=CAN-FD
        pdu SRL_HL_01_XIX_E3V_K2CANFD_E2E: length=8, transmission-mode-true-timing=event-controlled-timing={number-of-repetitions=0, repetition-period=0.0}, unused-bit-pattern=0  # Fuer die Botschaft ist das Cyclic-Timing 0.5 zu verwenden.
          signal SRL_HL_01_CRC_XIX_SRL_HL_01_XIX_E3V_K2CANFD: start 0, 8 bit, little-endian, data-type-policy=OVERRIDE, i-signal-type=PRIMITIVE, init-value=0, base-type=BT_SRL_HL_01_CRC, compu {phys=raw for raw 0..255}, range phys 0..255, raw 0..255, to SAM(timeout 5 s)  # Für MLB: Berechnung siehe Lastenheft "Kommunikationsabsicherung für FlexRay und CAN" Ab MQB und MLBevo: Berechnung siehe Lastenheft "End-to-End Kommunikationsabsicherung" Endwerte siehe Begleitdokument "S-PDU Kennungsfolgen"
          signal SRL_HL_01_BZ_XIX_SRL_HL_01_XIX_E3V_K2CANFD: start 8, 4 bit, little-endian, data-type-policy=OVERRIDE, i-signal-type=PRIMITIVE, init-value=0, base-type=BT_SRL_HL_01_BZ, compu {phys=raw for raw 0..15}, range phys 0..15, raw 0..15, to SAM(timeout 5 s)
          signal SRL5_ORUDataIndex_XIX_SRL_HL_01_XIX_E3V_K2CANFD: start 12, 4 bit, little-endian, data-type-policy=OVERRIDE, i-signal-type=PRIMITIVE, init-value=0, base-type=BT_SRL5_ORUDataIndex, compu {phys=raw for raw 0..15}, range phys 0..15, raw 0..15, to SAM(timeout 5 s)  # Data index of the last 6 Bytes
          signal SRL5_ORUData_XIX_SRL_HL_01_XIX_E3V_K2CANFD: start 16, 48 bit, little-endian, data-type-policy=OVERRIDE, i-signal-type=PRIMITIVE, init-value=0, base-type=BT_SRL5_ORUData, compu {phys=raw for raw 0..281474976710655}, range phys 0..281474976710655, raw 0..281474976710655, to SAM(timeout 5 s)  # "ORU information multiplexed - diagnostic address (2 bytes) - HW-part no (11 bytes) - HW version no. (3 bytes) - SW version no. (4 bytes) - IVD-P Value (64 bytes) need to be sent in combination with ORUDataIndex"
          mapping SG_SRL_HL_01_XIX_E3V_K2CANFD: i-signal-group=SG_SRL_HL_01_XIX_E3V_K2CANFD, transfer-property=TRIGGERED-WITHOUT-REPETITION
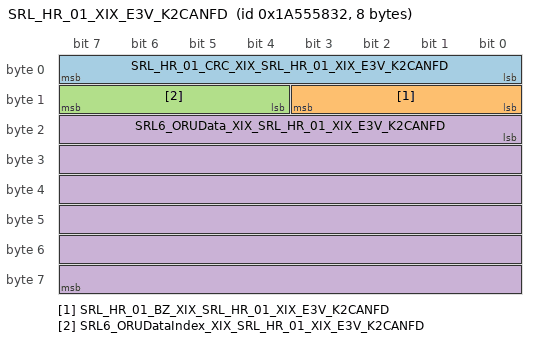
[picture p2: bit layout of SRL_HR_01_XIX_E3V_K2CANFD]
      frame SRL_HR_01_XIX_E3V_K2CANFD: id 0x1A555832, to SAM, frame-length=8, can-addressing-mode=EXTENDED, can-frame-rx-behavior=CAN-FD, can-frame-tx-behavior=CAN-FD
        pdu SRL_HR_01_XIX_E3V_K2CANFD_E2E: length=8, transmission-mode-true-timing=event-controlled-timing={number-of-repetitions=0, repetition-period=0.0}, unused-bit-pattern=0  # Fuer die Botschaft ist das Cyclic-Timing 0.5 zu verwenden.
          signal SRL_HR_01_CRC_XIX_SRL_HR_01_XIX_E3V_K2CANFD: start 0, 8 bit, little-endian, data-type-policy=OVERRIDE, i-signal-type=PRIMITIVE, init-value=0, base-type=BT_SRL_HR_01_CRC, compu {phys=raw for raw 0..255}, range phys 0..255, raw 0..255, to SAM(timeout 5 s)  # Für MLB: Berechnung siehe Lastenheft "Kommunikationsabsicherung für FlexRay und CAN" Ab MQB und MLBevo: Berechnung siehe Lastenheft "End-to-End Kommunikationsabsicherung" Endwerte siehe Begleitdokument "S-PDU Kennungsfolgen"
          signal SRL_HR_01_BZ_XIX_SRL_HR_01_XIX_E3V_K2CANFD: start 8, 4 bit, little-endian, data-type-policy=OVERRIDE, i-signal-type=PRIMITIVE, init-value=0, base-type=BT_SRL_HR_01_BZ, compu {phys=raw for raw 0..15}, range phys 0..15, raw 0..15, to SAM(timeout 5 s)
          signal SRL6_ORUDataIndex_XIX_SRL_HR_01_XIX_E3V_K2CANFD: start 12, 4 bit, little-endian, data-type-policy=OVERRIDE, i-signal-type=PRIMITIVE, init-value=0, base-type=BT_SRL6_ORUDataIndex, compu {phys=raw for raw 0..15}, range phys 0..15, raw 0..15, to SAM(timeout 5 s)  # Data index of the last 6 Bytes
          signal SRL6_ORUData_XIX_SRL_HR_01_XIX_E3V_K2CANFD: start 16, 48 bit, little-endian, data-type-policy=OVERRIDE, i-signal-type=PRIMITIVE, init-value=0, base-type=BT_SRL6_ORUData, compu {phys=raw for raw 0..281474976710655}, range phys 0..281474976710655, raw 0..281474976710655, to SAM(timeout 5 s)  # "ORU information multiplexed - diagnostic address (2 bytes) - HW-part no (11 bytes) - HW version no. (3 bytes) - SW version no. (4 bytes) - IVD-P Value (64 bytes) need to be sent in combination with ORUDataIndex"
          mapping SG_SRL_HR_01_XIX_E3V_K2CANFD: i-signal-group=SG_SRL_HR_01_XIX_E3V_K2CANFD, transfer-property=TRIGGERED-WITHOUT-REPETITION
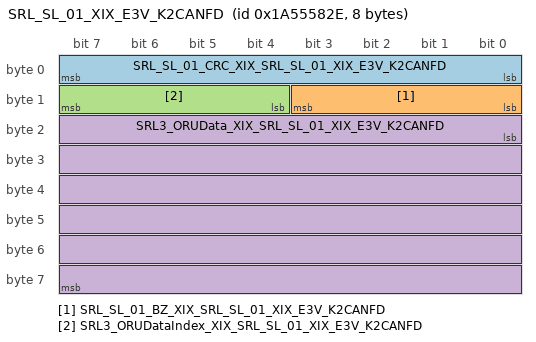
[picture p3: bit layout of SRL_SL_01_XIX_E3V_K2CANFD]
      frame SRL_SL_01_XIX_E3V_K2CANFD: id 0x1A55582E, to SAM, frame-length=8, can-addressing-mode=EXTENDED, can-frame-rx-behavior=CAN-FD, can-frame-tx-behavior=CAN-FD
        pdu SRL_SL_01_XIX_E3V_K2CANFD_E2E: length=8, transmission-mode-true-timing=event-controlled-timing={number-of-repetitions=0, repetition-period=0.0}, unused-bit-pattern=0  # Fuer die Botschaft ist das Cyclic-Timing 0.5 zu verwenden.
          signal SRL_SL_01_CRC_XIX_SRL_SL_01_XIX_E3V_K2CANFD: start 0, 8 bit, little-endian, data-type-policy=OVERRIDE, i-signal-type=PRIMITIVE, init-value=0, base-type=BT_SRL_SL_01_CRC, compu {phys=raw for raw 0..255}, range phys 0..255, raw 0..255, to SAM(timeout 5 s)  # Für MLB: Berechnung siehe Lastenheft "Kommunikationsabsicherung für FlexRay und CAN" Ab MQB und MLBevo: Berechnung siehe Lastenheft "End-to-End Kommunikationsabsicherung" Endwerte siehe Begleitdokument "S-PDU Kennungsfolgen"
          signal SRL_SL_01_BZ_XIX_SRL_SL_01_XIX_E3V_K2CANFD: start 8, 4 bit, little-endian, data-type-policy=OVERRIDE, i-signal-type=PRIMITIVE, init-value=0, base-type=BT_SRL_SL_01_BZ, compu {phys=raw for raw 0..15}, range phys 0..15, raw 0..15, to SAM(timeout 5 s)
          signal SRL3_ORUDataIndex_XIX_SRL_SL_01_XIX_E3V_K2CANFD: start 12, 4 bit, little-endian, data-type-policy=OVERRIDE, i-signal-type=PRIMITIVE, init-value=0, base-type=BT_SRL3_ORUDataIndex, compu {phys=raw for raw 0..15}, range phys 0..15, raw 0..15, to SAM(timeout 5 s)  # Data index of the last 6 Bytes
          signal SRL3_ORUData_XIX_SRL_SL_01_XIX_E3V_K2CANFD: start 16, 48 bit, little-endian, data-type-policy=OVERRIDE, i-signal-type=PRIMITIVE, init-value=0, base-type=BT_SRL3_ORUData, compu {phys=raw for raw 0..281474976710655}, range phys 0..281474976710655, raw 0..281474976710655, to SAM(timeout 5 s)  # "ORU information multiplexed - diagnostic address (2 bytes) - HW-part no (11 bytes) - HW version no. (3 bytes) - SW version no. (4 bytes) - IVD-P Value (64 bytes) need to be sent in combination with ORUDataIndex"
          mapping SG_SRL_SL_01_XIX_E3V_K2CANFD: i-signal-group=SG_SRL_SL_01_XIX_E3V_K2CANFD, transfer-property=TRIGGERED-WITHOUT-REPETITION
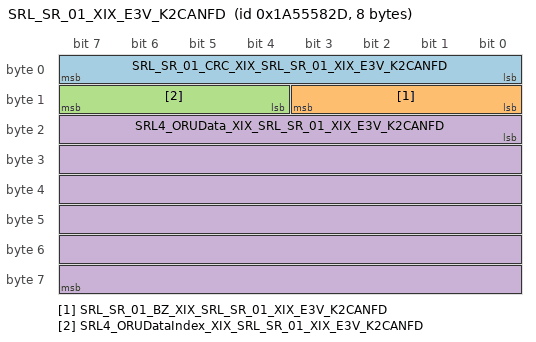
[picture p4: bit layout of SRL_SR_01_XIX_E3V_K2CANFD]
      frame SRL_SR_01_XIX_E3V_K2CANFD: id 0x1A55582D, to SAM, frame-length=8, can-addressing-mode=EXTENDED, can-frame-rx-behavior=CAN-FD, can-frame-tx-behavior=CAN-FD
        pdu SRL_SR_01_XIX_E3V_K2CANFD_E2E: length=8, transmission-mode-true-timing=event-controlled-timing={number-of-repetitions=0, repetition-period=0.0}, unused-bit-pattern=0  # Fuer die Botschaft ist das Cyclic-Timing 0.5 zu verwenden.
          signal SRL_SR_01_CRC_XIX_SRL_SR_01_XIX_E3V_K2CANFD: start 0, 8 bit, little-endian, data-type-policy=OVERRIDE, i-signal-type=PRIMITIVE, init-value=0, base-type=BT_SRL_SR_01_CRC, compu {phys=raw for raw 0..255}, range phys 0..255, raw 0..255, to SAM(timeout 5 s)  # Für MLB: Berechnung siehe Lastenheft "Kommunikationsabsicherung für FlexRay und CAN" Ab MQB und MLBevo: Berechnung siehe Lastenheft "End-to-End Kommunikationsabsicherung" Endwerte siehe Begleitdokument "S-PDU Kennungsfolgen"
          signal SRL_SR_01_BZ_XIX_SRL_SR_01_XIX_E3V_K2CANFD: start 8, 4 bit, little-endian, data-type-policy=OVERRIDE, i-signal-type=PRIMITIVE, init-value=0, base-type=BT_SRL_SR_01_BZ, compu {phys=raw for raw 0..15}, range phys 0..15, raw 0..15, to SAM(timeout 5 s)
          signal SRL4_ORUDataIndex_XIX_SRL_SR_01_XIX_E3V_K2CANFD: start 12, 4 bit, little-endian, data-type-policy=OVERRIDE, i-signal-type=PRIMITIVE, init-value=0, base-type=BT_SRL4_ORUDataIndex, compu {phys=raw for raw 0..15}, range phys 0..15, raw 0..15, to SAM(timeout 5 s)  # Data index of the last 6 Bytes
          signal SRL4_ORUData_XIX_SRL_SR_01_XIX_E3V_K2CANFD: start 16, 48 bit, little-endian, data-type-policy=OVERRIDE, i-signal-type=PRIMITIVE, init-value=0, base-type=BT_SRL4_ORUData, compu {phys=raw for raw 0..281474976710655}, range phys 0..281474976710655, raw 0..281474976710655, to SAM(timeout 5 s)  # "ORU information multiplexed - diagnostic address (2 bytes) - HW-part no (11 bytes) - HW version no. (3 bytes) - SW version no. (4 bytes) - IVD-P Value (64 bytes) need to be sent in combination with ORUDataIndex"
          mapping SG_SRL_SR_01_XIX_E3V_K2CANFD: i-signal-group=SG_SRL_SR_01_XIX_E3V_K2CANFD, transfer-property=TRIGGERED-WITHOUT-REPETITION
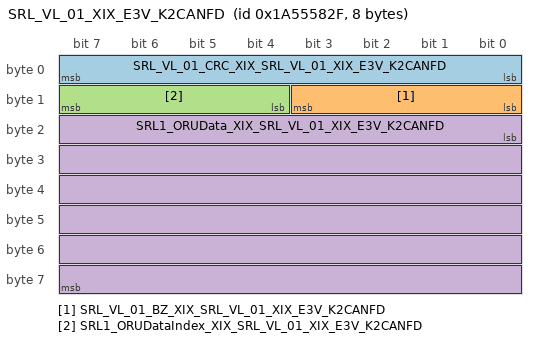
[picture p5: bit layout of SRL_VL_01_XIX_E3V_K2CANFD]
      frame SRL_VL_01_XIX_E3V_K2CANFD: id 0x1A55582F, to SAM, frame-length=8, can-addressing-mode=EXTENDED, can-frame-rx-behavior=CAN-FD, can-frame-tx-behavior=CAN-FD
        pdu SRL_VL_01_XIX_E3V_K2CANFD_E2E: length=8, transmission-mode-true-timing=event-controlled-timing={number-of-repetitions=0, repetition-period=0.0}, unused-bit-pattern=0  # Fuer die Botschaft ist das Cyclic-Timing 0.5 zu verwenden.
          signal SRL_VL_01_CRC_XIX_SRL_VL_01_XIX_E3V_K2CANFD: start 0, 8 bit, little-endian, data-type-policy=OVERRIDE, i-signal-type=PRIMITIVE, init-value=0, base-type=BT_SRL_VL_01_CRC, compu {phys=raw for raw 0..255}, range phys 0..255, raw 0..255, to SAM(timeout 5 s)  # Für MLB: Berechnung siehe Lastenheft "Kommunikationsabsicherung für FlexRay und CAN" Ab MQB und MLBevo: Berechnung siehe Lastenheft "End-to-End Kommunikationsabsicherung" Endwerte siehe Begleitdokument "S-PDU Kennungsfolgen"
          signal SRL_VL_01_BZ_XIX_SRL_VL_01_XIX_E3V_K2CANFD: start 8, 4 bit, little-endian, data-type-policy=OVERRIDE, i-signal-type=PRIMITIVE, init-value=0, base-type=BT_SRL_VL_01_BZ, compu {phys=raw for raw 0..15}, range phys 0..15, raw 0..15, to SAM(timeout 5 s)
          signal SRL1_ORUDataIndex_XIX_SRL_VL_01_XIX_E3V_K2CANFD: start 12, 4 bit, little-endian, data-type-policy=OVERRIDE, i-signal-type=PRIMITIVE, init-value=0, base-type=BT_SRL1_ORUDataIndex, compu {phys=raw for raw 0..15}, range phys 0..15, raw 0..15, to SAM(timeout 5 s)  # Data index of the last 6 Bytes
          signal SRL1_ORUData_XIX_SRL_VL_01_XIX_E3V_K2CANFD: start 16, 48 bit, little-endian, data-type-policy=OVERRIDE, i-signal-type=PRIMITIVE, init-value=0, base-type=BT_SRL1_ORUData, compu {phys=raw for raw 0..281474976710655}, range phys 0..281474976710655, raw 0..281474976710655, to SAM(timeout 5 s)  # "ORU information multiplexed - diagnostic address (2 bytes) - HW-part no (11 bytes) - HW version no. (3 bytes) - SW version no. (4 bytes) - IVD-P Value (64 bytes) need to be sent in combination with ORUDataIndex"
          mapping SG_SRL_VL_01_XIX_E3V_K2CANFD: i-signal-group=SG_SRL_VL_01_XIX_E3V_K2CANFD, transfer-property=TRIGGERED-WITHOUT-REPETITION
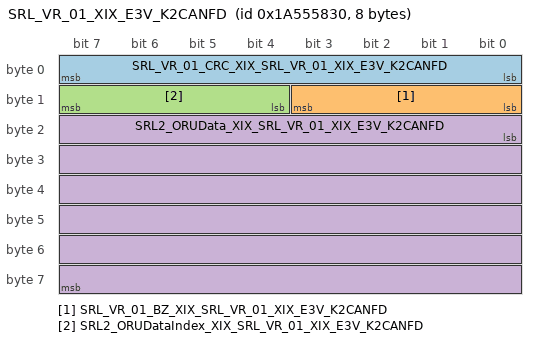
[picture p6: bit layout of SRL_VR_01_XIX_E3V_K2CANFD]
      frame SRL_VR_01_XIX_E3V_K2CANFD: id 0x1A555830, to SAM, frame-length=8, can-addressing-mode=EXTENDED, can-frame-rx-behavior=CAN-FD, can-frame-tx-behavior=CAN-FD
        pdu SRL_VR_01_XIX_E3V_K2CANFD_E2E: length=8, transmission-mode-true-timing=event-controlled-timing={number-of-repetitions=0, repetition-period=0.0}, unused-bit-pattern=0  # Fuer die Botschaft ist das Cyclic-Timing 0.5 zu verwenden.
          signal SRL_VR_01_CRC_XIX_SRL_VR_01_XIX_E3V_K2CANFD: start 0, 8 bit, little-endian, data-type-policy=OVERRIDE, i-signal-type=PRIMITIVE, init-value=0, base-type=BT_SRL_VR_01_CRC, compu {phys=raw for raw 0..255}, range phys 0..255, raw 0..255, to SAM(timeout 5 s)  # Für MLB: Berechnung siehe Lastenheft "Kommunikationsabsicherung für FlexRay und CAN" Ab MQB und MLBevo: Berechnung siehe Lastenheft "End-to-End Kommunikationsabsicherung" Endwerte siehe Begleitdokument "S-PDU Kennungsfolgen"
          signal SRL_VR_01_BZ_XIX_SRL_VR_01_XIX_E3V_K2CANFD: start 8, 4 bit, little-endian, data-type-policy=OVERRIDE, i-signal-type=PRIMITIVE, init-value=0, base-type=BT_SRL_VR_01_BZ, compu {phys=raw for raw 0..15}, range phys 0..15, raw 0..15, to SAM(timeout 5 s)
          signal SRL2_ORUDataIndex_XIX_SRL_VR_01_XIX_E3V_K2CANFD: start 12, 4 bit, little-endian, data-type-policy=OVERRIDE, i-signal-type=PRIMITIVE, init-value=0, base-type=BT_SRL2_ORUDataIndex, compu {phys=raw for raw 0..15}, range phys 0..15, raw 0..15, to SAM(timeout 5 s)  # Data index of the last 6 Bytes
          signal SRL2_ORUData_XIX_SRL_VR_01_XIX_E3V_K2CANFD: start 16, 48 bit, little-endian, data-type-policy=OVERRIDE, i-signal-type=PRIMITIVE, init-value=0, base-type=BT_SRL2_ORUData, compu {phys=raw for raw 0..281474976710655}, range phys 0..281474976710655, raw 0..281474976710655, to SAM(timeout 5 s)  # "ORU information multiplexed - diagnostic address (2 bytes) - HW-part no (11 bytes) - HW version no. (3 bytes) - SW version no. (4 bytes) - IVD-P Value (64 bytes) need to be sent in combination with ORUDataIndex"
          mapping SG_SRL_VR_01_XIX_E3V_K2CANFD: i-signal-group=SG_SRL_VR_01_XIX_E3V_K2CANFD, transfer-property=TRIGGERED-WITHOUT-REPETITION
      frame STSG_HBFS_01_XIX_E3V_K2CANFD: id 0x340, to SAM, frame-length=8, can-addressing-mode=STANDARD, can-frame-rx-behavior=CAN-FD, can-frame-tx-behavior=CAN-FD
        pdu STSG_HBFS_01_XIX_E3V_K2CANFD: length=8, minimum-delay=0.02, transmission-mode-true-timing={cyclic-timing={time-offset=0.0, time-period=0.1}, event-controlled-timing={number-of-repetitions=0, repetition-period=0.0}}, unused-bit-pattern=0
          signal STSG_HBFS_AD_oeffnen_Anf_XIX_STSG_HBFS_01_XIX_E3V_K2CANFD: start 9, 1 bit, little-endian, data-type-policy=OVERRIDE, i-signal-type=PRIMITIVE, init-value=0, base-type=BT_STSG_HBFS_AD_oeffnen_Anf, compu {0=Cx0_Keine_Anforderung (CM_STSG_HBFS_AD_oeffnen_Anf_Cx0_Keine_Anforderung), 1=Cx1_Anforderung (CM_STSG_HBFS_AD_oeffnen_Anf_Cx1_Anforderung)}, range raw 0..1, transfer-property=PENDING, to SAM(timeout 1 s)  # Öffnungsanforderung Schiebetür per Remote
          signal STSG_HBFS_BTF_Status_XIX_STSG_HBFS_01_XIX_E3V_K2CANFD: start 10, 1 bit, little-endian, data-type-policy=OVERRIDE, i-signal-type=PRIMITIVE, init-value=1, base-type=BT_STSG_HBFS_BTF_Status, compu {0=Cx0_inaktiv (CM_STSG_HBFS_BTF_Status_Cx0_inaktiv), 1=Cx1_aktiv (CM_STSG_HBFS_BTF_Status_Cx1_aktiv)}, range raw 0..1, transfer-property=TRIGGERED-ON-CHANGE-WITHOUT-REPETITION  # Status des B-Säulen Tasters
          signal STSG_HBFS_Status_Feststeller_XIX_STSG_HBFS_01_XIX_E3V_K2CANFD: start 35, 1 bit, little-endian, data-type-policy=OVERRIDE, i-signal-type=PRIMITIVE, init-value=0, base-type=BT_STSG_HBFS_Status_Feststeller, compu {0=Cx0_geloest (CM_STSG_HBFS_Status_Feststeller_Cx0_geloest), 1=Cx1_festgestellt (CM_STSG_HBFS_Status_Feststeller_Cx1_festgestellt)}, range raw 0..1, transfer-property=TRIGGERED-ON-CHANGE-WITHOUT-REPETITION  # Status des Schiebetür Feststeller Beifahrerseite. gelöst/Festgestellt
          signal STSG_HBFS_Tuer_Position_XIX_STSG_HBFS_01_XIX_E3V_K2CANFD: start 36, 7 bit, little-endian, data-type-policy=OVERRIDE, i-signal-type=PRIMITIVE, base-type=BT_STSG_HBFS_Tuer_Position, compu {phys=raw for raw 0..127; unit Unit_PerCent}, range phys 0..127 Unit_PerCent, raw 0..127, unit=Unit_PerCent, transfer-property=PENDING  # Position der Schiebetür. 0%: Tuer geschlossen 100%: Tuer geoeffnet bis Softendanschlag >100%: Tuer geoeffnet ueber Softendanschlag hinaus
          signal STSG_HBFS_TIG_bet_schliessen_XIX_STSG_HBFS_01_XIX_E3V_K2CANFD: start 43, 1 bit, little-endian, data-type-policy=OVERRIDE, i-signal-type=PRIMITIVE, base-type=BT_STSG_HBFS_TIG_bet_schliessen, compu {0=Cx0_nicht_betaetigt (CM_STSG_HBFS_TIG_bet_schliessen_Cx0_nicht_betaetigt), 1=Cx1_betaetigt (CM_STSG_HBFS_TIG_bet_schliessen_Cx1_betaetigt)}, range raw 0..1, transfer-property=TRIGGERED-ON-CHANGE-WITHOUT-REPETITION  # Türinnenbetätigung, Taster Tür schliessen.
          signal STSG_HBFS_TIG_bet_oeffnen_XIX_STSG_HBFS_01_XIX_E3V_K2CANFD: start 44, 1 bit, little-endian, data-type-policy=OVERRIDE, i-signal-type=PRIMITIVE, base-type=BT_STSG_HBFS_TIG_bet_oeffnen, compu {0=Cx0_nicht_betaetigt (CM_STSG_HBFS_TIG_bet_oeffnen_Cx0_nicht_betaetigt), 1=Cx1_betaetigt (CM_STSG_HBFS_TIG_bet_oeffnen_Cx1_betaetigt)}, range raw 0..1, transfer-property=TRIGGERED-ON-CHANGE-WITHOUT-REPETITION  # Türinnenbetätigung, Taster Tür öffnen.
          signal STSG_HBFS_FFB_Taste_Schiebtuer_XIX_STSG_HBFS_01_XIX_E3V_K2CANFD: start 45, 1 bit, little-endian, data-type-policy=OVERRIDE, i-signal-type=PRIMITIVE, base-type=BT_STSG_HBFS_FFB_Taste_Schiebtuer, compu {0=Cx0_nicht_betaetigt (CM_STSG_HBFS_FFB_Taste_Schiebtuer_Cx0_nicht_betaetigt), 1=Cx1_betaetigt (CM_STSG_HBFS_FFB_Taste_Schiebtuer_Cx1_betaetigt)}, range raw 0..1, transfer-property=TRIGGERED-ON-CHANGE-WITHOUT-REPETITION  # Taste für Schiebetür auf der Funkfernbedienung.
          signal STSG_HBFS_TAG_betaetigt_XIX_STSG_HBFS_01_XIX_E3V_K2CANFD: start 46, 1 bit, little-endian, data-type-policy=OVERRIDE, i-signal-type=PRIMITIVE, base-type=BT_STSG_HBFS_TAG_betaetigt, compu {0=Cx0_nicht_betaetigt (CM_STSG_HBFS_TAG_betaetigt_Cx0_nicht_betaetigt), 1=Cx1_betaetigt (CM_STSG_HBFS_TAG_betaetigt_Cx1_betaetigt)}, range raw 0..1, transfer-property=TRIGGERED-ON-CHANGE-WITHOUT-REPETITION  # Türaussenbetaetigung
          signal STSG_HBFS_Tuer_Sperrklinke_XIX_STSG_HBFS_01_XIX_E3V_K2CANFD: start 47, 1 bit, little-endian, data-type-policy=OVERRIDE, i-signal-type=PRIMITIVE, init-value=0, base-type=BT_STSG_HBFS_Tuer_Sperrklinke, compu {0=Cx0_nicht_in_Vorraste (CM_STSG_HBFS_Tuer_Sperrklinke_Cx0_nicht_in_Vorraste), 1=Cx1_in_Vorraste (CM_STSG_HBFS_Tuer_Sperrklinke_Cx1_in_Vorraste)}, range raw 0..1, transfer-property=TRIGGERED-ON-CHANGE-WITHOUT-REPETITION  # STSG Sperrklinke
          signal STSG_HBFS_entriegeln_anfordern_XIX_STSG_HBFS_01_XIX_E3V_K2CANFD: start 48, 1 bit, little-endian, data-type-policy=OVERRIDE, i-signal-type=PRIMITIVE, init-value=0, base-type=BT_STSG_HBFS_entriegeln_anfordern, compu {0=Cx0_nicht_anfordern (CM_STSG_HBFS_entriegeln_anfordern_Cx0_nicht_anfordern), 1=Cx1_anfordern (CM_STSG_HBFS_entriegeln_anfordern_Cx1_anfordern)}, range raw 0..1, transfer-property=TRIGGERED-ON-CHANGE-WITHOUT-REPETITION, to SAM(timeout 1 s)  # Das STSG fordert an, die Schiebetür zu entriegeln.
          signal STSG_HBFS_Tuer_Vorraste_XIX_STSG_HBFS_01_XIX_E3V_K2CANFD: start 49, 1 bit, little-endian, data-type-policy=OVERRIDE, i-signal-type=PRIMITIVE, init-value=0, base-type=BT_STSG_HBFS_Tuer_Vorraste, compu {0=Cx0_nicht_in_Vorraste (CM_STSG_HBFS_Tuer_Vorraste_Cx0_nicht_in_Vorraste), 1=Cx1_in_Vorraste (CM_STSG_HBFS_Tuer_Vorraste_Cx1_in_Vorraste)}, range raw 0..1, transfer-property=TRIGGERED-ON-CHANGE-WITHOUT-REPETITION  # STSG Vorraste
          signal STSG_HBFS_Thermo_aktiv_XIX_STSG_HBFS_01_XIX_E3V_K2CANFD: start 50, 1 bit, little-endian, data-type-policy=OVERRIDE, i-signal-type=PRIMITIVE, init-value=0, base-type=BT_STSG_HBFS_Thermo_aktiv, compu {0=Cx0_inaktiv (CM_STSG_HBFS_Thermo_aktiv_Cx0_inaktiv), 1=Cx1_aktiv (CM_STSG_HBFS_Thermo_aktiv_Cx1_aktiv)}, range raw 0..1, transfer-property=TRIGGERED-ON-CHANGE-WITHOUT-REPETITION  # STSG Thermoschutz
          signal STSG_HBFS_Bew_zu_XIX_STSG_HBFS_01_XIX_E3V_K2CANFD: start 51, 1 bit, little-endian, data-type-policy=OVERRIDE, i-signal-type=PRIMITIVE, init-value=0, base-type=BT_STSG_HBFS_Bew_zu, compu {0=Cx0_schliesst_nicht_und_steht (CM_STSG_HBFS_Bew_zu_Cx0_schliesst_nicht_und_steht), 1=Cx1_schliesst (CM_STSG_HBFS_Bew_zu_Cx1_schliesst)}, range raw 0..1, transfer-property=TRIGGERED-ON-CHANGE-WITHOUT-REPETITION, to SAM(timeout 1 s)  # STSG Tür-Bewegung schliessen
          signal STSG_HBFS_Bew_auf_XIX_STSG_HBFS_01_XIX_E3V_K2CANFD: start 52, 1 bit, little-endian, data-type-policy=OVERRIDE, i-signal-type=PRIMITIVE, init-value=0, base-type=BT_STSG_HBFS_Bew_auf, compu {0=Cx0_oeffnet_nicht_und_steht (CM_STSG_HBFS_Bew_auf_Cx0_oeffnet_nicht_und_steht), 1=Cx1_oeffnet (CM_STSG_HBFS_Bew_auf_Cx1_oeffnet)}, range raw 0..1, transfer-property=TRIGGERED-ON-CHANGE-WITHOUT-REPETITION, to SAM(timeout 1 s)  # STSG Tür-Bewegung öffnen
          signal STSG_HBFS_EOE_aktiv_XIX_STSG_HBFS_01_XIX_E3V_K2CANFD: start 53, 1 bit, little-endian, data-type-policy=OVERRIDE, i-signal-type=PRIMITIVE, init-value=0, base-type=BT_STSG_HBFS_EOE_aktiv, compu {0=Cx0_nicht_angesteuert (CM_STSG_HBFS_EOE_aktiv_Cx0_nicht_angesteuert), 1=Cx1_angesteuert (CM_STSG_HBFS_EOE_aktiv_Cx1_angesteuert)}, range raw 0..1, transfer-property=TRIGGERED-ON-CHANGE-WITHOUT-REPETITION  # STSG eÖ-Motor
          signal STSG_HBFS_ZZH_Status_zu_XIX_STSG_HBFS_01_XIX_E3V_K2CANFD: start 54, 1 bit, little-endian, data-type-policy=OVERRIDE, i-signal-type=PRIMITIVE, init-value=0, base-type=BT_STSG_HBFS_ZZH_Status_zu, compu {0=Cx0_ZZH_steht (CM_STSG_HBFS_ZZH_Status_zu_Cx0_ZZH_steht), 1=Cx1_ZZH_zieht_zu (CM_STSG_HBFS_ZZH_Status_zu_Cx1_ZZH_zieht_zu)}, range raw 0..1, transfer-property=TRIGGERED-ON-CHANGE-WITHOUT-REPETITION  # STSG Status zuziehen
          signal STSG_HBFS_ZZH_Status_auf_XIX_STSG_HBFS_01_XIX_E3V_K2CANFD: start 55, 1 bit, little-endian, data-type-policy=OVERRIDE, i-signal-type=PRIMITIVE, init-value=0, base-type=BT_STSG_HBFS_ZZH_Status_auf, compu {0=Cx0_ZZH_steht (CM_STSG_HBFS_ZZH_Status_auf_Cx0_ZZH_steht), 1=Cx1_ZZH_faehrt_aus (CM_STSG_HBFS_ZZH_Status_auf_Cx1_ZZH_faehrt_aus)}, range raw 0..1, transfer-property=TRIGGERED-ON-CHANGE-WITHOUT-REPETITION  # STSG Status ausfahren
          signal STSG_HBFS_ZZH_Initialisierung_XIX_STSG_HBFS_01_XIX_E3V_K2CANFD: start 56, 1 bit, little-endian, data-type-policy=OVERRIDE, i-signal-type=PRIMITIVE, init-value=0, base-type=BT_STSG_HBFS_ZZH_Initialisierung, compu {0=Cx0_Zuziehen_beendet (CM_STSG_HBFS_ZZH_Initialisierung_Cx0_Zuziehen_beendet), 1=Cx1_STSG_will_zuziehen (CM_STSG_HBFS_ZZH_Initialisierung_Cx1_STSG_will_zuziehen)}, range raw 0..1, transfer-property=TRIGGERED-ON-CHANGE-WITHOUT-REPETITION  # STSG Zuziehhilfe Initialisierung
          signal STSG_HBFS_ZZH_Freigabe_XIX_STSG_HBFS_01_XIX_E3V_K2CANFD: start 57, 1 bit, little-endian, data-type-policy=OVERRIDE, i-signal-type=PRIMITIVE, init-value=0, base-type=BT_STSG_HBFS_ZZH_Freigabe, compu {0=Cx0_keine_Freigabe (CM_STSG_HBFS_ZZH_Freigabe_Cx0_keine_Freigabe), 1=Cx1_Freigabe (CM_STSG_HBFS_ZZH_Freigabe_Cx1_Freigabe)}, range raw 0..1, transfer-property=TRIGGERED-ON-CHANGE-WITHOUT-REPETITION  # STSG Zuziehhilfe Freigabe
          signal STSG_HBFS_UEKB_aktiv_XIX_STSG_HBFS_01_XIX_E3V_K2CANFD: start 58, 1 bit, little-endian, data-type-policy=OVERRIDE, i-signal-type=PRIMITIVE, init-value=0, base-type=BT_STSG_HBFS_UEKB_aktiv, compu {0=Cx0_inaktiv (CM_STSG_HBFS_UEKB_aktiv_Cx0_inaktiv), 1=Cx1_aktiv (CM_STSG_HBFS_UEKB_aktiv_Cx1_aktiv)}, range raw 0..1, transfer-property=TRIGGERED-ON-CHANGE-WITHOUT-REPETITION  # STSG Überschusskraftbegrenzung
          signal STSG_HBFS_Einklemm_defekt_XIX_STSG_HBFS_01_XIX_E3V_K2CANFD: start 59, 1 bit, little-endian, data-type-policy=OVERRIDE, i-signal-type=PRIMITIVE, init-value=0, base-type=BT_STSG_HBFS_Einklemm_defekt, compu {0=Cx0_iO (CM_STSG_HBFS_Einklemm_defekt_Cx0_iO), 1=Cx1_defekt (CM_STSG_HBFS_Einklemm_defekt_Cx1_defekt)}, range raw 0..1, transfer-property=TRIGGERED-ON-CHANGE-WITHOUT-REPETITION  # STSG Einklemmschutzvorrichtung defekt
          signal STSG_HBFS_Einklemm_aktiv_XIX_STSG_HBFS_01_XIX_E3V_K2CANFD: start 60, 1 bit, little-endian, data-type-policy=OVERRIDE, i-signal-type=PRIMITIVE, init-value=0, base-type=BT_STSG_HBFS_Einklemm_aktiv, compu {0=Cx0_inaktiv (CM_STSG_HBFS_Einklemm_aktiv_Cx0_inaktiv), 1=Cx1_aktiv (CM_STSG_HBFS_Einklemm_aktiv_Cx1_aktiv)}, range raw 0..1, transfer-property=TRIGGERED-ON-CHANGE-WITHOUT-REPETITION  # STSG Einklemmschutzvorrichtung aktiv
          signal STSG_HBFS_TAT_XIX_STSG_HBFS_01_XIX_E3V_K2CANFD: start 61, 1 bit, little-endian, data-type-policy=OVERRIDE, i-signal-type=PRIMITIVE, init-value=0, base-type=BT_STSG_HBFS_TAT, compu {0=Cx0_nicht_betaetigt (CM_STSG_HBFS_TAT_Cx0_nicht_betaetigt), 1=Cx1_betaetigt (CM_STSG_HBFS_TAT_Cx1_betaetigt)}, range raw 0..1, transfer-property=TRIGGERED-ON-CHANGE-WITHOUT-REPETITION, to SAM(timeout 1 s)  # STSG TAT Betätigung
          signal STSG_HBFS_ST_deaktivieren_XIX_STSG_HBFS_01_XIX_E3V_K2CANFD: start 62, 1 bit, little-endian, data-type-policy=OVERRIDE, i-signal-type=PRIMITIVE, init-value=0, base-type=BT_STSG_HBFS_ST_deaktivieren, compu {0=Cx0_inaktiv (CM_STSG_HBFS_ST_deaktivieren_Cx0_inaktiv), 1=Cx1_aktiv (CM_STSG_HBFS_ST_deaktivieren_Cx1_aktiv)}, range raw 0..1, transfer-property=TRIGGERED-ON-CHANGE-WITHOUT-REPETITION, to SAM(timeout 1 s)  # STSG deaktivieren
          signal STSG_HBFS_BTF_XIX_STSG_HBFS_01_XIX_E3V_K2CANFD: start 63, 1 bit, little-endian, data-type-policy=OVERRIDE, i-signal-type=PRIMITIVE, init-value=0, base-type=BT_STSG_HBFS_BTF, compu {0=Cx0_nicht_betaetigt (CM_STSG_HBFS_BTF_Cx0_nicht_betaetigt), 1=Cx1_betaetigt (CM_STSG_HBFS_BTF_Cx1_betaetigt)}, range raw 0..1, transfer-property=TRIGGERED-ON-CHANGE-WITHOUT-REPETITION, to SAM(timeout 1 s)  # STSG BTF Betätigung
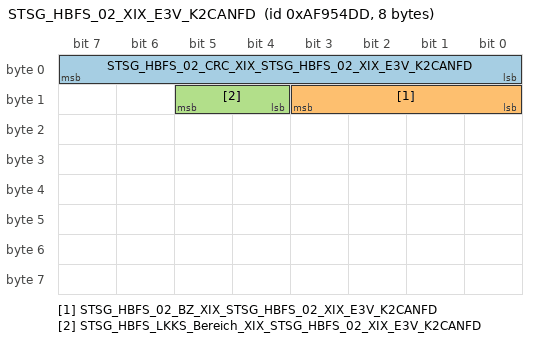
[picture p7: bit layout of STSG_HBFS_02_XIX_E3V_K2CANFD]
      frame STSG_HBFS_02_XIX_E3V_K2CANFD: id 0xAF954DD, to SAM, frame-length=8, can-addressing-mode=EXTENDED, can-frame-rx-behavior=CAN-FD, can-frame-tx-behavior=CAN-FD
        pdu STSG_HBFS_02_XIX_E3V_K2CANFD: length=8, minimum-delay=0.02, transmission-mode-true-timing={cyclic-timing={time-offset=0.0, time-period=0.1}, event-controlled-timing={number-of-repetitions=0, repetition-period=0.0}}, unused-bit-pattern=0
          signal STSG_HBFS_02_CRC_XIX_STSG_HBFS_02_XIX_E3V_K2CANFD: start 0, 8 bit, little-endian, data-type-policy=OVERRIDE, i-signal-type=PRIMITIVE, init-value=0, base-type=BT_STSG_HBFS_02_CRC, compu {phys=raw for raw 0..255}, range phys 0..255, raw 0..255, transfer-property=PENDING  # Für MLB: Berechnung siehe Lastenheft "Kommunikationsabsicherung für FlexRay und CAN" Ab MQB und MLBevo: Berechnung siehe Lastenheft "End-to-End Kommunikationsabsicherung" Endwerte siehe Begleitdokument "S-PDU Kennungsfolgen"
          signal STSG_HBFS_02_BZ_XIX_STSG_HBFS_02_XIX_E3V_K2CANFD: start 8, 4 bit, little-endian, data-type-policy=OVERRIDE, i-signal-type=PRIMITIVE, init-value=0, base-type=BT_STSG_HBFS_02_BZ, compu {phys=raw for raw 0..15}, range phys 0..15, raw 0..15, transfer-property=PENDING  # 4bit Botschaftszähler, wird mit jeder Sendebotschaft inkrementiert
          signal STSG_HBFS_LKKS_Bereich_XIX_STSG_HBFS_02_XIX_E3V_K2CANFD: start 12, 2 bit, little-endian, data-type-policy=OVERRIDE, i-signal-type=PRIMITIVE, init-value=0, base-type=BT_STSG_HBFS_LKKS_Bereich, compu {0=Cx0_Init (CM_STSG_HBFS_LKKS_Bereich_Cx0_Init), 1=Cx1_sicherer_Bereich (CM_STSG_HBFS_LKKS_Bereich_Cx1_sicherer_Bereich), 2=Cx2_Bremsbereich (CM_STSG_HBFS_LKKS_Bereich_Cx2_Bremsbereich), 3=Cx3_Kollisionsbereich (CM_STSG_HBFS_LKKS_Bereich_Cx3_Kollisionsbereich)}, range raw 0..3, transfer-property=TRIGGERED-ON-CHANGE-WITHOUT-REPETITION, to SAM(timeout 1 s)  # Gibt den Bereich bekannt in dem sich die Schiebetür bei einem Linkslenker im Verhältnis zur Ladeklappe befindet. Dieser Bereich teilt sich auf in: - sicherer Bereich - Bremsbereich - Kollisionsbereich
      frame STSG_HFS_01_XIX_E3V_K2CANFD: id 0x33F, to SAM, frame-length=8, can-addressing-mode=STANDARD, can-frame-rx-behavior=CAN-FD, can-frame-tx-behavior=CAN-FD
        pdu STSG_HFS_01_XIX_E3V_K2CANFD: length=8, minimum-delay=0.02, transmission-mode-true-timing={cyclic-timing={time-offset=0.0, time-period=0.1}, event-controlled-timing={number-of-repetitions=0, repetition-period=0.0}}, unused-bit-pattern=0
          signal STSG_HFS_AD_oeffnen_Anf_XIX_STSG_HFS_01_XIX_E3V_K2CANFD: start 9, 1 bit, little-endian, data-type-policy=OVERRIDE, i-signal-type=PRIMITIVE, init-value=0, base-type=BT_STSG_HFS_AD_oeffnen_Anf, compu {0=Cx0_Keine_Anforderung (CM_STSG_HFS_AD_oeffnen_Anf_Cx0_Keine_Anforderung), 1=Cx1_Anforderung (CM_STSG_HFS_AD_oeffnen_Anf_Cx1_Anforderung)}, range raw 0..1, transfer-property=PENDING, to SAM(timeout 1 s)  # Öffnungsanforderung Schiebetür per Remote
          signal STSG_HFS_BTF_Status_XIX_STSG_HFS_01_XIX_E3V_K2CANFD: start 10, 1 bit, little-endian, data-type-policy=OVERRIDE, i-signal-type=PRIMITIVE, init-value=1, base-type=BT_STSG_HFS_BTF_Status, compu {0=Cx0_inaktiv (CM_STSG_HFS_BTF_Status_Cx0_inaktiv), 1=Cx1_aktiv (CM_STSG_HFS_BTF_Status_Cx1_aktiv)}, range raw 0..1, transfer-property=TRIGGERED-ON-CHANGE-WITHOUT-REPETITION  # Status des B-Säulen Tasters
          signal STSG_HFS_Status_Feststeller_XIX_STSG_HFS_01_XIX_E3V_K2CANFD: start 35, 1 bit, little-endian, data-type-policy=OVERRIDE, i-signal-type=PRIMITIVE, init-value=0, base-type=BT_STSG_HFS_Status_Feststeller, compu {0=Cx0_geloest (CM_STSG_HFS_Status_Feststeller_Cx0_geloest), 1=Cx1_festgestellt (CM_STSG_HFS_Status_Feststeller_Cx1_festgestellt)}, range raw 0..1, transfer-property=TRIGGERED-ON-CHANGE-WITHOUT-REPETITION  # Status des Schiebetür Feststeller Fahrerseite gelöst/Festgestellt
          signal STSG_HFS_Tuer_Position_XIX_STSG_HFS_01_XIX_E3V_K2CANFD: start 36, 7 bit, little-endian, data-type-policy=OVERRIDE, i-signal-type=PRIMITIVE, base-type=BT_STSG_HFS_Tuer_Position, compu {phys=raw for raw 0..127; unit Unit_PerCent}, range phys 0..127 Unit_PerCent, raw 0..127, unit=Unit_PerCent, transfer-property=PENDING  # Position der Schiebetür. 0%: Tuer geschlossen 100%: Tuer geoeffnet bis Softendanschlag >100%: Tuer geoeffnet ueber Softendanschlag hinaus
          signal STSG_HFS_TIG_bet_schliessen_XIX_STSG_HFS_01_XIX_E3V_K2CANFD: start 43, 1 bit, little-endian, data-type-policy=OVERRIDE, i-signal-type=PRIMITIVE, init-value=0, base-type=BT_STSG_HFS_TIG_bet_schliessen, compu {0=Cx0_nicht_betaetigt (CM_STSG_HFS_TIG_bet_schliessen_Cx0_nicht_betaetigt), 1=Cx1_betaetigt (CM_STSG_HFS_TIG_bet_schliessen_Cx1_betaetigt)}, range raw 0..1, transfer-property=TRIGGERED-ON-CHANGE-WITHOUT-REPETITION  # Türinnenbetätigung, Taster Tür schliessen.
          signal STSG_HFS_TIG_bet_oeffnen_XIX_STSG_HFS_01_XIX_E3V_K2CANFD: start 44, 1 bit, little-endian, data-type-policy=OVERRIDE, i-signal-type=PRIMITIVE, init-value=0, base-type=BT_STSG_HFS_TIG_bet_oeffnen, compu {0=Cx0_nicht_betaetigt (CM_STSG_HFS_TIG_bet_oeffnen_Cx0_nicht_betaetigt), 1=Cx1_betaetigt (CM_STSG_HFS_TIG_bet_oeffnen_Cx1_betaetigt)}, range raw 0..1, transfer-property=TRIGGERED-ON-CHANGE-WITHOUT-REPETITION  # Türinnenbetätigung, Taster Tür öffnen.
          signal STSG_HFS_FFB_Taste_Schiebetuer_XIX_STSG_HFS_01_XIX_E3V_K2CANFD: start 45, 1 bit, little-endian, data-type-policy=OVERRIDE, i-signal-type=PRIMITIVE, init-value=0, base-type=BT_STSG_HFS_FFB_Taste_Schiebetuer, compu {0=Cx0_nicht_betaetigt (CM_STSG_HFS_FFB_Taste_Schiebetuer_Cx0_nicht_betaetigt), 1=Cx1_betaetigt (CM_STSG_HFS_FFB_Taste_Schiebetuer_Cx1_betaetigt)}, range raw 0..1, transfer-property=TRIGGERED-ON-CHANGE-WITHOUT-REPETITION  # Taste für Schiebetür auf der Funkfernbedienung.
          signal STSG_HFS_TAG_betaetigt_XIX_STSG_HFS_01_XIX_E3V_K2CANFD: start 46, 1 bit, little-endian, data-type-policy=OVERRIDE, i-signal-type=PRIMITIVE, init-value=0, base-type=BT_STSG_HFS_TAG_betaetigt, compu {0=Cx0_nicht_betaetigt (CM_STSG_HFS_TAG_betaetigt_Cx0_nicht_betaetigt), 1=Cx1_betaetigt (CM_STSG_HFS_TAG_betaetigt_Cx1_betaetigt)}, range raw 0..1, transfer-property=TRIGGERED-ON-CHANGE-WITHOUT-REPETITION  # Türaussenbetaetigung
          signal STSG_HFS_Tuer_Sperrklinke_XIX_STSG_HFS_01_XIX_E3V_K2CANFD: start 47, 1 bit, little-endian, data-type-policy=OVERRIDE, i-signal-type=PRIMITIVE, init-value=0, base-type=BT_STSG_HFS_Tuer_Sperrklinke, compu {0=Cx0_nicht_in_Vorraste (CM_STSG_HFS_Tuer_Sperrklinke_Cx0_nicht_in_Vorraste), 1=Cx1_in_Vorraste (CM_STSG_HFS_Tuer_Sperrklinke_Cx1_in_Vorraste)}, range raw 0..1, transfer-property=TRIGGERED-ON-CHANGE-WITHOUT-REPETITION  # STSG Sperrklinke
          signal STSG_HFS_entriegeln_anforderen_XIX_STSG_HFS_01_XIX_E3V_K2CANFD: start 48, 1 bit, little-endian, data-type-policy=OVERRIDE, i-signal-type=PRIMITIVE, init-value=0, base-type=BT_STSG_HFS_entriegeln_anforderen, compu {0=Cx0_nicht_anforden (CM_STSG_HFS_entriegeln_anforderen_Cx0_nicht_anforden), 1=Cx1_anfordern (CM_STSG_HFS_entriegeln_anforderen_Cx1_anfordern)}, range raw 0..1, transfer-property=TRIGGERED-ON-CHANGE-WITHOUT-REPETITION, to SAM(timeout 1 s)  # Das STSG fordert an, die Schiebetür zu entriegeln.
          signal STSG_HFS_Tuer_Vorraste_XIX_STSG_HFS_01_XIX_E3V_K2CANFD: start 49, 1 bit, little-endian, data-type-policy=OVERRIDE, i-signal-type=PRIMITIVE, init-value=0, base-type=BT_STSG_HFS_Tuer_Vorraste, compu {0=Cx0_nicht_in_Vorraste (CM_STSG_HFS_Tuer_Vorraste_Cx0_nicht_in_Vorraste), 1=Cx1_in_Vorraste (CM_STSG_HFS_Tuer_Vorraste_Cx1_in_Vorraste)}, range raw 0..1, transfer-property=TRIGGERED-ON-CHANGE-WITHOUT-REPETITION  # STSG Vorraste
          signal STSG_HFS_Thermo_aktiv_XIX_STSG_HFS_01_XIX_E3V_K2CANFD: start 50, 1 bit, little-endian, data-type-policy=OVERRIDE, i-signal-type=PRIMITIVE, init-value=0, base-type=BT_STSG_HFS_Thermo_aktiv, compu {0=Cx0_inaktiv (CM_STSG_HFS_Thermo_aktiv_Cx0_inaktiv), 1=Cx1_aktiv (CM_STSG_HFS_Thermo_aktiv_Cx1_aktiv)}, range raw 0..1, transfer-property=TRIGGERED-ON-CHANGE-WITHOUT-REPETITION  # STSG Thermoschutz
          signal STSG_HFS_Bew_zu_XIX_STSG_HFS_01_XIX_E3V_K2CANFD: start 51, 1 bit, little-endian, data-type-policy=OVERRIDE, i-signal-type=PRIMITIVE, init-value=0, base-type=BT_STSG_HFS_Bew_zu, compu {0=Cx0_schliesst_nicht_und_steht (CM_STSG_HFS_Bew_zu_Cx0_schliesst_nicht_und_steht), 1=Cx1_schliesst (CM_STSG_HFS_Bew_zu_Cx1_schliesst)}, range raw 0..1, transfer-property=TRIGGERED-ON-CHANGE-WITHOUT-REPETITION, to SAM(timeout 1 s)  # STSG Tür-Bewegung schliessen
          signal STSG_HFS_Bew_auf_XIX_STSG_HFS_01_XIX_E3V_K2CANFD: start 52, 1 bit, little-endian, data-type-policy=OVERRIDE, i-signal-type=PRIMITIVE, init-value=0, base-type=BT_STSG_HFS_Bew_auf, compu {0=Cx0_oeffnet_nicht_und_steht (CM_STSG_HFS_Bew_auf_Cx0_oeffnet_nicht_und_steht), 1=Cx1_oeffnet (CM_STSG_HFS_Bew_auf_Cx1_oeffnet)}, range raw 0..1, transfer-property=TRIGGERED-ON-CHANGE-WITHOUT-REPETITION, to SAM(timeout 1 s)  # STSG Tür-Bewegung öffnen
          signal STSG_HFS_EOE_aktiv_XIX_STSG_HFS_01_XIX_E3V_K2CANFD: start 53, 1 bit, little-endian, data-type-policy=OVERRIDE, i-signal-type=PRIMITIVE, init-value=0, base-type=BT_STSG_HFS_EOE_aktiv, compu {0=Cx0_nicht_angesteuert (CM_STSG_HFS_EOE_aktiv_Cx0_nicht_angesteuert), 1=Cx1_angesteuert (CM_STSG_HFS_EOE_aktiv_Cx1_angesteuert)}, range raw 0..1, transfer-property=TRIGGERED-ON-CHANGE-WITHOUT-REPETITION  # STSG eÖ-Motor
          signal STSG_HFS_ZZH_Status_zu_XIX_STSG_HFS_01_XIX_E3V_K2CANFD: start 54, 1 bit, little-endian, data-type-policy=OVERRIDE, i-signal-type=PRIMITIVE, init-value=0, base-type=BT_STSG_HFS_ZZH_Status_zu, compu {0=Cx0_ZZH_steht (CM_STSG_HFS_ZZH_Status_zu_Cx0_ZZH_steht), 1=Cx1_ZZH_zieht_zu (CM_STSG_HFS_ZZH_Status_zu_Cx1_ZZH_zieht_zu)}, range raw 0..1, transfer-property=TRIGGERED-ON-CHANGE-WITHOUT-REPETITION  # STSG Status zuziehen
          signal STSG_HFS_ZZH_Status_auf_XIX_STSG_HFS_01_XIX_E3V_K2CANFD: start 55, 1 bit, little-endian, data-type-policy=OVERRIDE, i-signal-type=PRIMITIVE, init-value=0, base-type=BT_STSG_HFS_ZZH_Status_auf, compu {0=Cx0_ZZH_steht (CM_STSG_HFS_ZZH_Status_auf_Cx0_ZZH_steht), 1=Cx1_ZZH_faehrt_aus (CM_STSG_HFS_ZZH_Status_auf_Cx1_ZZH_faehrt_aus)}, range raw 0..1, transfer-property=TRIGGERED-ON-CHANGE-WITHOUT-REPETITION  # STSG Status ausfahren
          signal STSG_HFS_ZZH_Initialisierung_XIX_STSG_HFS_01_XIX_E3V_K2CANFD: start 56, 1 bit, little-endian, data-type-policy=OVERRIDE, i-signal-type=PRIMITIVE, init-value=0, base-type=BT_STSG_HFS_ZZH_Initialisierung, compu {0=Cx0_Zuziehen_beendet (CM_STSG_HFS_ZZH_Initialisierung_Cx0_Zuziehen_beendet), 1=Cx1_STSG_will_zuziehen (CM_STSG_HFS_ZZH_Initialisierung_Cx1_STSG_will_zuziehen)}, range raw 0..1, transfer-property=TRIGGERED-ON-CHANGE-WITHOUT-REPETITION  # STSG Zuziehhilfe Initialisierung
          signal STSG_HFS_ZZH_Freigabe_XIX_STSG_HFS_01_XIX_E3V_K2CANFD: start 57, 1 bit, little-endian, data-type-policy=OVERRIDE, i-signal-type=PRIMITIVE, init-value=0, base-type=BT_STSG_HFS_ZZH_Freigabe, compu {0=Cx0_keine_Freigabe (CM_STSG_HFS_ZZH_Freigabe_Cx0_keine_Freigabe), 1=Cx1_Freigabe (CM_STSG_HFS_ZZH_Freigabe_Cx1_Freigabe)}, range raw 0..1, transfer-property=TRIGGERED-ON-CHANGE-WITHOUT-REPETITION  # STSG Zuziehhilfe Freigabe
          signal STSG_HFS_UEKB_aktiv_XIX_STSG_HFS_01_XIX_E3V_K2CANFD: start 58, 1 bit, little-endian, data-type-policy=OVERRIDE, i-signal-type=PRIMITIVE, init-value=0, base-type=BT_STSG_HFS_UEKB_aktiv, compu {0=Cx0_inaktiv (CM_STSG_HFS_UEKB_aktiv_Cx0_inaktiv), 1=Cx1_aktiv (CM_STSG_HFS_UEKB_aktiv_Cx1_aktiv)}, range raw 0..1, transfer-property=TRIGGERED-ON-CHANGE-WITHOUT-REPETITION  # STSG Überschusskraftbegrenzung
          signal STSG_HFS_Einklemm_defekt_XIX_STSG_HFS_01_XIX_E3V_K2CANFD: start 59, 1 bit, little-endian, data-type-policy=OVERRIDE, i-signal-type=PRIMITIVE, init-value=0, base-type=BT_STSG_HFS_Einklemm_defekt, compu {0=Cx0_iO (CM_STSG_HFS_Einklemm_defekt_Cx0_iO), 1=Cx1_defekt (CM_STSG_HFS_Einklemm_defekt_Cx1_defekt)}, range raw 0..1, transfer-property=TRIGGERED-ON-CHANGE-WITHOUT-REPETITION  # STSG Einklemmschutzvorrichtung defekt
          signal STSG_HFS_Einklemm_aktiv_XIX_STSG_HFS_01_XIX_E3V_K2CANFD: start 60, 1 bit, little-endian, data-type-policy=OVERRIDE, i-signal-type=PRIMITIVE, init-value=0, base-type=BT_STSG_HFS_Einklemm_aktiv, compu {0=Cx0_inaktiv (CM_STSG_HFS_Einklemm_aktiv_Cx0_inaktiv), 1=Cx1_aktiv (CM_STSG_HFS_Einklemm_aktiv_Cx1_aktiv)}, range raw 0..1, transfer-property=TRIGGERED-ON-CHANGE-WITHOUT-REPETITION  # STSG Einklemmschutzvorrichtung aktiv
          signal STSG_HFS_TAT_XIX_STSG_HFS_01_XIX_E3V_K2CANFD: start 61, 1 bit, little-endian, data-type-policy=OVERRIDE, i-signal-type=PRIMITIVE, init-value=0, base-type=BT_STSG_HFS_TAT, compu {0=Cx0_nicht_betaetigt (CM_STSG_HFS_TAT_Cx0_nicht_betaetigt), 1=Cx1_betaetigt (CM_STSG_HFS_TAT_Cx1_betaetigt)}, range raw 0..1, transfer-property=TRIGGERED-ON-CHANGE-WITHOUT-REPETITION, to SAM(timeout 1 s)  # STSG TAT Betätigung
          signal STSG_HFS_ST_deaktivieren_XIX_STSG_HFS_01_XIX_E3V_K2CANFD: start 62, 1 bit, little-endian, data-type-policy=OVERRIDE, i-signal-type=PRIMITIVE, init-value=0, base-type=BT_STSG_HFS_ST_deaktivieren, compu {0=Cx0_inaktiv (CM_STSG_HFS_ST_deaktivieren_Cx0_inaktiv), 1=Cx1_aktiv (CM_STSG_HFS_ST_deaktivieren_Cx1_aktiv)}, range raw 0..1, transfer-property=TRIGGERED-ON-CHANGE-WITHOUT-REPETITION, to SAM(timeout 1 s)  # STSG deaktivieren
          signal STSG_HFS_BTF_XIX_STSG_HFS_01_XIX_E3V_K2CANFD: start 63, 1 bit, little-endian, data-type-policy=OVERRIDE, i-signal-type=PRIMITIVE, init-value=0, base-type=BT_STSG_HFS_BTF, compu {0=Cx0_nicht_betaetigt (CM_STSG_HFS_BTF_Cx0_nicht_betaetigt), 1=Cx1_betaetigt (CM_STSG_HFS_BTF_Cx1_betaetigt)}, range raw 0..1, transfer-property=TRIGGERED-ON-CHANGE-WITHOUT-REPETITION, to SAM(timeout 1 s)  # STSG BTF Betätigung
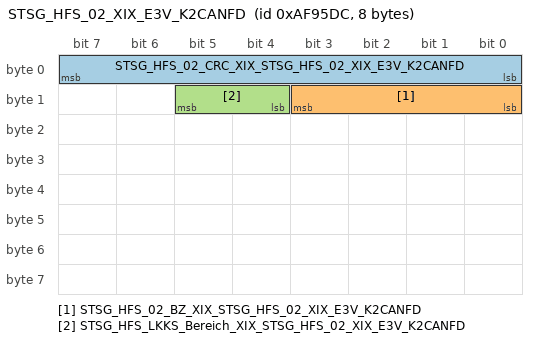
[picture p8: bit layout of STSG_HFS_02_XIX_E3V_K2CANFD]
      frame STSG_HFS_02_XIX_E3V_K2CANFD: id 0xAF95DC, to SAM, frame-length=8, can-addressing-mode=EXTENDED, can-frame-rx-behavior=CAN-FD, can-frame-tx-behavior=CAN-FD
        pdu STSG_HFS_02_XIX_E3V_K2CANFD: length=8, minimum-delay=0.02, transmission-mode-true-timing={cyclic-timing={time-offset=0.0, time-period=0.1}, event-controlled-timing={number-of-repetitions=0, repetition-period=0.0}}, unused-bit-pattern=0
          signal STSG_HFS_02_CRC_XIX_STSG_HFS_02_XIX_E3V_K2CANFD: start 0, 8 bit, little-endian, data-type-policy=OVERRIDE, i-signal-type=PRIMITIVE, init-value=0, base-type=BT_STSG_HFS_02_CRC, compu {phys=raw for raw 0..255}, range phys 0..255, raw 0..255, transfer-property=PENDING  # Für MLB: Berechnung siehe Lastenheft "Kommunikationsabsicherung für FlexRay und CAN" Ab MQB und MLBevo: Berechnung siehe Lastenheft "End-to-End Kommunikationsabsicherung" Endwerte siehe Begleitdokument "S-PDU Kennungsfolgen"
          signal STSG_HFS_02_BZ_XIX_STSG_HFS_02_XIX_E3V_K2CANFD: start 8, 4 bit, little-endian, data-type-policy=OVERRIDE, i-signal-type=PRIMITIVE, init-value=0, base-type=BT_STSG_HFS_02_BZ, compu {phys=raw for raw 0..15}, range phys 0..15, raw 0..15, transfer-property=PENDING  # 4bit Botschaftszähler, wird mit jeder Sendebotschaft inkrementiert
          signal STSG_HFS_LKKS_Bereich_XIX_STSG_HFS_02_XIX_E3V_K2CANFD: start 12, 2 bit, little-endian, data-type-policy=OVERRIDE, i-signal-type=PRIMITIVE, init-value=0, base-type=BT_STSG_HFS_LKKS_Bereich, compu {0=Cx0_Init (CM_STSG_HFS_LKKS_Bereich_Cx0_Init), 1=Cx1_sicherer_Bereich (CM_STSG_HFS_LKKS_Bereich_Cx1_sicherer_Bereich), 2=Cx2_Bremsbereich (CM_STSG_HFS_LKKS_Bereich_Cx2_Bremsbereich), 3=Cx3_Kollisionsbereich (CM_STSG_HFS_LKKS_Bereich_Cx3_Kollisionsbereich)}, range raw 0..3, transfer-property=TRIGGERED-ON-CHANGE-WITHOUT-REPETITION, to SAM(timeout 1 s)  # Gibt den Bereich bekannt in dem sich die Schiebetür bei einem Rechtslenker im Verhältnis zur Ladeklappe befindet. Dieser Bereich teilt sich auf in: - sicherer Bereich - Bremsbereich - Kollisionsbereich
      frame Systeminfo_01_XIX_E3V_K2CANFD: id 0x585, to SAM, frame-length=8, can-addressing-mode=STANDARD, can-frame-rx-behavior=CAN-FD, can-frame-tx-behavior=CAN-FD
        pdu Systeminfo_01_XIX_E3V_K2CANFD: length=8, minimum-delay=0.01, transmission-mode-true-timing={cyclic-timing={time-offset=0.0, time-period=1.0}, event-controlled-timing={number-of-repetitions=0, repetition-period=0.0}}, unused-bit-pattern=0  # MQB, MLBevo
          signal SI_Sammel_SG_Fehler_XIX_Systeminfo_01_XIX_E3V_K2CANFD: start 0, 6 bit, little-endian, data-type-policy=OVERRIDE, i-signal-type=PRIMITIVE, init-value=63, base-type=BT_SI_Sammel_SG_Fehler, compu {phys=raw for raw 0..60, 61=Cx3d_Reserviert (CM_SI_Sammel_SG_Fehler_Cx3d_Reserviert), 62=Cx3e_Overflow (CM_SI_Sammel_SG_Fehler_Cx3e_Overflow), 63=Cx3f_ungueltig (CM_SI_Sammel_SG_Fehler_Cx3f_ungueltig)}, range phys 0..60, raw 0..63, transfer-property=PENDING  # Anzahl der gesetzten KD-Fehler direkt angeschlossener Steuergeräte der DK3 und DK4 gemäß 80127. Hinweis: Ein Subbusmaster stellt nur die gesammelte Information der an ihn angeschlossenen Steuergeräte der DK3 und DK4 zur Verfügung. Für ServiceKey Auswertung
          signal SI_P_Mode_gueltig_XIX_Systeminfo_01_XIX_E3V_K2CANFD: start 6, 1 bit, little-endian, data-type-policy=OVERRIDE, i-signal-type=PRIMITIVE, init-value=0, base-type=BT_SI_P_Mode_gueltig, compu {0=Cx0_dezentraler_Produktionsmode (CM_SI_P_Mode_gueltig_Cx0_dezentraler_Produktionsmode), 1=Cx1_zentraler_Produktionsmode (CM_SI_P_Mode_gueltig_Cx1_zentraler_Produktionsmode)}, range raw 0..1, transfer-property=TRIGGERED-ON-CHANGE-WITHOUT-REPETITION, to SAM(timeout 5 s)  # zeigt an, ob es sich um ein Fahrzeug mit zentraler oder dezentraler Steu-erung des Produktionsmodes handelt Siehe Q-LAH Produktionsmode (LAH.DUM.907.AS)
          signal SI_Diagnose_Aktiv_XIX_Systeminfo_01_XIX_E3V_K2CANFD: start 7, 1 bit, little-endian, data-type-policy=OVERRIDE, i-signal-type=PRIMITIVE, init-value=0, base-type=BT_SI_Diagnose_Aktiv, compu {0=Cx0_inaktiv (CM_SI_Diagnose_Aktiv_Cx0_inaktiv), 1=Cx1_aktiv (CM_SI_Diagnose_Aktiv_Cx1_aktiv)}, range raw 0..1, transfer-property=TRIGGERED-ON-CHANGE-WITHOUT-REPETITION  # Gibt an ob Diagnose-Botschaften empfangen werden und somit eine Diagnose aktiv ist. MQB: Gibt an ob Diagnose-Bus Botschaften empfangen werden und somit eine Diagnose aktiv ist.
          signal SI_QRS_Mode_XIX_Systeminfo_01_XIX_E3V_K2CANFD: start 8, 1 bit, little-endian, data-type-policy=OVERRIDE, i-signal-type=PRIMITIVE, init-value=0, base-type=BT_SI_QRS_Mode, compu {0=Cx0_QRS_Messmodus_nicht_aktiv (CM_SI_QRS_Mode_Cx0_QRS_Messmodus_nicht_aktiv), 1=Cx1_QRS_Messmodus_aktiv (CM_SI_QRS_Mode_Cx1_QRS_Messmodus_aktiv)}, range raw 0..1, transfer-property=TRIGGERED-ON-CHANGE-WITHOUT-REPETITION, to SAM(timeout 5 s)  # Messmodus Quick-Ruhestrom
          signal SI_T_Mode_XIX_Systeminfo_01_XIX_E3V_K2CANFD: start 9, 1 bit, little-endian, data-type-policy=OVERRIDE, i-signal-type=PRIMITIVE, init-value=0, base-type=BT_SI_T_Mode, compu {0=Cx0_Transportmodus_nicht_aktiv (CM_SI_T_Mode_Cx0_Transportmodus_nicht_aktiv), 1=Cx1_Transportmodus_aktiv (CM_SI_T_Mode_Cx1_Transportmodus_aktiv)}, range raw 0..1, transfer-property=TRIGGERED-ON-CHANGE-WITHOUT-REPETITION, to SAM(timeout 5 s)  # 0x0: Transportmodus nicht aktiv 0x1: Transportmodus aktiv
          signal SI_NWDF_XIX_Systeminfo_01_XIX_E3V_K2CANFD: start 10, 1 bit, little-endian, data-type-policy=OVERRIDE, i-signal-type=PRIMITIVE, init-value=0, base-type=BT_SI_NWDF, compu {0=Cx0_Ueberwachung_nicht_freigegeben (CM_SI_NWDF_Cx0_Ueberwachung_nicht_freigegeben), 1=Cx1_Ueberwachung_freigegeben (CM_SI_NWDF_Cx1_Ueberwachung_freigegeben)}, range raw 0..1, transfer-property=TRIGGERED-ON-CHANGE-WITHOUT-REPETITION, to SAM(timeout 5 s)  # Netzwerk-Diagnose Freigebe zur zentralen Aktivierung der Netzwerkdiagnose
          signal SI_NWDF_gueltig_XIX_Systeminfo_01_XIX_E3V_K2CANFD: start 11, 1 bit, little-endian, data-type-policy=OVERRIDE, i-signal-type=PRIMITIVE, base-type=BT_SI_NWDF_gueltig, compu {0=Cx0_NWDF_wird_nicht_unterstuetzt (CM_SI_NWDF_gueltig_Cx0_NWDF_wird_nicht_unterstuetzt), 1=Cx1_NWDF_wird_unterstuetzt (CM_SI_NWDF_gueltig_Cx1_NWDF_wird_unterstuetzt)}, range raw 0..1, transfer-property=TRIGGERED-ON-CHANGE-WITHOUT-REPETITION, to SAM(timeout 5 s)  # Gültigkeitsbit zu SI_NWDF gemäß Lastenheft: Zentrale Aktivierung Netzwerkdiagnose
          signal SI_Sammelfehler_XIX_Systeminfo_01_XIX_E3V_K2CANFD: start 12, 1 bit, little-endian, data-type-policy=OVERRIDE, i-signal-type=PRIMITIVE, init-value=0, base-type=BT_SI_Sammelfehler, compu {0=Cx0_kein_Sammelfehler (CM_SI_Sammelfehler_Cx0_kein_Sammelfehler), 1=Cx1_Sammelfehler (CM_SI_Sammelfehler_Cx1_Sammelfehler)}, range raw 0..1, transfer-property=TRIGGERED-ON-CHANGE-WITHOUT-REPETITION  # Sammelfehlermeldung zur Anzeige im Kombi - siehe Spez. Sammelfehlermeldung Hinweis: Einzelne Steuergeräte können zur Anpassung an den Produktionsprozess im Gateway auskodiert werden!
          signal GW_KD_Fehler_XIX_Systeminfo_01_XIX_E3V_K2CANFD: start 13, 1 bit, little-endian, data-type-policy=OVERRIDE, i-signal-type=PRIMITIVE, init-value=0, base-type=BT_GW_KD_Fehler, compu {0=Cx0_kein_KD_Fehler (CM_GW_KD_Fehler_Cx0_kein_KD_Fehler), 1=Cx1_KD_Fehler (CM_GW_KD_Fehler_Cx1_KD_Fehler)}, range raw 0..1, transfer-property=TRIGGERED-ON-CHANGE-WITHOUT-REPETITION  # Kundendienstfehlerbit Gateway zur Anzeige eines im Gateway abgelegten Fehlerspeichereintrages.
          signal SI_T_Schutz_XIX_Systeminfo_01_XIX_E3V_K2CANFD: start 14, 1 bit, little-endian, data-type-policy=OVERRIDE, i-signal-type=PRIMITIVE, init-value=0, base-type=BT_SI_T_Schutz, compu {0=Cx0_Transportschutz_nicht_aktiv (CM_SI_T_Schutz_Cx0_Transportschutz_nicht_aktiv), 1=Cx1_Transportschutz_aktiv (CM_SI_T_Schutz_Cx1_Transportschutz_aktiv)}, range raw 0..1, transfer-property=TRIGGERED-ON-CHANGE-WITHOUT-REPETITION, to SAM(timeout 5 s)  # Transportschutz-Signal, das bei Transportmodus und Motorlauf aktiv bleibt 0x0: Transportschutz nicht aktiv 0x1: Transportschutz aktiv
          signal SI_P_Mode_XIX_Systeminfo_01_XIX_E3V_K2CANFD: start 15, 1 bit, little-endian, data-type-policy=OVERRIDE, i-signal-type=PRIMITIVE, init-value=0, base-type=BT_SI_P_Mode, compu {0=Cx0_inaktiv (CM_SI_P_Mode_Cx0_inaktiv), 1=Cx1_aktiv (CM_SI_P_Mode_Cx1_aktiv)}, range raw 0..1, transfer-property=TRIGGERED-ON-CHANGE-WITHOUT-REPETITION, to SAM(timeout 5 s)  # Zentrale Steuerung des Produktionsmodes gemäß Q-LAH-Produktionsmode (LAH.DUM.907.AS)
          signal SI_BUS_01_XIX_Systeminfo_01_XIX_E3V_K2CANFD: start 16, 1 bit, little-endian, data-type-policy=OVERRIDE, i-signal-type=PRIMITIVE, init-value=1, base-type=BT_SI_BUS_01, compu {0=Cx0_keine_Busruhe (CM_SI_BUS_01_Cx0_keine_Busruhe), 1=Cx1_Busruhe (CM_SI_BUS_01_Cx1_Busruhe)}, range raw 0..1, transfer-property=TRIGGERED-ON-CHANGE-WITHOUT-REPETITION, to SAM(timeout 5 s)  # MQB/MQB_A0/PQ26: ACAN MQB2020: ACAN(FD) MLBevo: HCAN E3_Volumen: ACAN(FD) MQBw_Baseline: ACAN(FD)
          signal SI_BUS_02_XIX_Systeminfo_01_XIX_E3V_K2CANFD: start 17, 1 bit, little-endian, data-type-policy=OVERRIDE, i-signal-type=PRIMITIVE, init-value=1, base-type=BT_SI_BUS_02, compu {0=Cx0_keine_Busruhe (CM_SI_BUS_02_Cx0_keine_Busruhe), 1=Cx1_Busruhe (CM_SI_BUS_02_Cx1_Busruhe)}, range raw 0..1, transfer-property=TRIGGERED-ON-CHANGE-WITHOUT-REPETITION, to SAM(timeout 5 s)  # MQB/MQB A0 Standard+, High: FCAN MQB2020: FCAN(FD) MLBevo: Frei E3_Volumen: FCAN(FD) MQBw_Baseline: FCAN(FD)
          signal SI_BUS_03_XIX_Systeminfo_01_XIX_E3V_K2CANFD: start 18, 1 bit, little-endian, data-type-policy=OVERRIDE, i-signal-type=PRIMITIVE, init-value=1, base-type=BT_SI_BUS_03, compu {0=Cx0_keine_Busruhe (CM_SI_BUS_03_Cx0_keine_Busruhe), 1=Cx1_Busruhe (CM_SI_BUS_03_Cx1_Busruhe)}, range raw 0..1, transfer-property=TRIGGERED-ON-CHANGE-WITHOUT-REPETITION, to SAM(timeout 5 s)  # MQB/MQB A0/PQ26: KCAN MQB2020: KCAN MLBevo: KCAN E3_Volumen: KCAN(HS) / K2CAN(FD) (Buskopplung) MQBw_Baseline: KCAN(HS)
          signal SI_BUS_04_XIX_Systeminfo_01_XIX_E3V_K2CANFD: start 19, 1 bit, little-endian, data-type-policy=OVERRIDE, i-signal-type=PRIMITIVE, init-value=1, base-type=BT_SI_BUS_04, compu {0=Cx0_keine_Busruhe (CM_SI_BUS_04_Cx0_keine_Busruhe), 1=Cx1_Busruhe (CM_SI_BUS_04_Cx1_Busruhe)}, range raw 0..1, transfer-property=TRIGGERED-ON-CHANGE-WITHOUT-REPETITION  # MQB/MQB A0 Standard+, High: ICAN MQB2020: ICAN(HS) MLBevo: ICAN E3_Volumen: ABCAN(FD) MQBw_Baseline: ICAN(HS)
          signal SI_BUS_05_XIX_Systeminfo_01_XIX_E3V_K2CANFD: start 20, 1 bit, little-endian, data-type-policy=OVERRIDE, i-signal-type=PRIMITIVE, init-value=1, base-type=BT_SI_BUS_05, compu {0=Cx0_keine_Busruhe (CM_SI_BUS_05_Cx0_keine_Busruhe), 1=Cx1_Busruhe (CM_SI_BUS_05_Cx1_Busruhe)}, range raw 0..1, transfer-property=TRIGGERED-ON-CHANGE-WITHOUT-REPETITION, to SAM(timeout 5 s)  # MQB/MQB A0/PQ26: DiagCAN MQB2020: DiagCAN(FD) MLBevo: DiagCAN E3_Volumen: DiagCAN(FD) MQBw_Baseline: DiagCAN(FD)
          signal SI_BUS_06_XIX_Systeminfo_01_XIX_E3V_K2CANFD: start 21, 1 bit, little-endian, data-type-policy=OVERRIDE, i-signal-type=PRIMITIVE, init-value=1, base-type=BT_SI_BUS_06, compu {0=Cx0_keine_Busruhe (CM_SI_BUS_06_Cx0_keine_Busruhe), 1=Cx1_Busruhe (CM_SI_BUS_06_Cx1_Busruhe)}, range raw 0..1, transfer-property=TRIGGERED-ON-CHANGE-WITHOUT-REPETITION, to SAM(timeout 5 s)  # MQB/MQB A0/PQ26: ECAN MQB2020: FASCAN(FD) MLBevo: ECAN E3_Volumen: FASCAN_1(FD) MQBw_Baseline: FASCAN_1(FD)
          signal SI_BUS_07_XIX_Systeminfo_01_XIX_E3V_K2CANFD: start 22, 1 bit, little-endian, data-type-policy=OVERRIDE, i-signal-type=PRIMITIVE, init-value=1, base-type=BT_SI_BUS_07, compu {0=Cx0_keine_Busruhe (CM_SI_BUS_07_Cx0_keine_Busruhe), 1=Cx1_Busruhe (CM_SI_BUS_07_Cx1_Busruhe)}, range raw 0..1, transfer-property=TRIGGERED-ON-CHANGE-WITHOUT-REPETITION  # MQB: LIN1 (Energie) MQB2020: LIN1 (Energie) MLBevo: LIN1 (Energie) E3_Volumen: LIN 1 (Energie) MQBw_Baseline: LIN1 (Energie)
          signal SI_BUS_08_XIX_Systeminfo_01_XIX_E3V_K2CANFD: start 23, 1 bit, little-endian, data-type-policy=OVERRIDE, i-signal-type=PRIMITIVE, init-value=1, base-type=BT_SI_BUS_08, compu {0=Cx0_keine_Busruhe (CM_SI_BUS_08_Cx0_keine_Busruhe), 1=Cx1_Busruhe (CM_SI_BUS_08_Cx1_Busruhe)}, range raw 0..1, transfer-property=TRIGGERED-ON-CHANGE-WITHOUT-REPETITION  # MQB: LIN2 (MFL) MQB2020: LIN2 (MFL) MLBevo: LIN2 (MFL) E3_Volumen: LIN2 (MFL) MQBw_Baseline: LIN2 (MFL)
          signal SI_BUS_09_XIX_Systeminfo_01_XIX_E3V_K2CANFD: start 24, 1 bit, little-endian, data-type-policy=OVERRIDE, i-signal-type=PRIMITIVE, init-value=1, base-type=BT_SI_BUS_09, compu {0=Cx0_keine_Busruhe (CM_SI_BUS_09_Cx0_keine_Busruhe), 1=Cx1_Busruhe (CM_SI_BUS_09_Cx1_Busruhe)}, range raw 0..1, transfer-property=TRIGGERED-ON-CHANGE-WITHOUT-REPETITION  # MQB: LIN3 (unbelegt) MQB2020: LIN3 (Uhr/FES) MLBevo: LIN3 (Energie2) MEB: LIN3 E³ 1.1 UNECE: MDKCAN
          signal SI_BUS_10_XIX_Systeminfo_01_XIX_E3V_K2CANFD: start 25, 1 bit, little-endian, data-type-policy=OVERRIDE, i-signal-type=PRIMITIVE, init-value=1, base-type=BT_SI_BUS_10, compu {0=Cx0_keine_Busruhe (CM_SI_BUS_10_Cx0_keine_Busruhe), 1=Cx1_Busruhe (CM_SI_BUS_10_Cx1_Busruhe)}, range raw 0..1, transfer-property=TRIGGERED-ON-CHANGE-WITHOUT-REPETITION, to SAM(timeout 5 s)  # MLBevo: Flexray MQB2020: MCAN MQBw_Baseline: FASCAN_2(FD) E³ 1.1 UNECE: FASCAN_2(FD)
          signal SI_BUS_11_XIX_Systeminfo_01_XIX_E3V_K2CANFD: start 26, 1 bit, little-endian, data-type-policy=OVERRIDE, i-signal-type=PRIMITIVE, init-value=1, base-type=BT_SI_BUS_11, compu {0=Cx0_keine_Busruhe (CM_SI_BUS_11_Cx0_keine_Busruhe), 1=Cx1_Busruhe (CM_SI_BUS_11_Cx1_Busruhe)}, range raw 0..1, transfer-property=TRIGGERED-ON-CHANGE-WITHOUT-REPETITION  # MLBevo: Ethernet MEB: LIN4
          signal SI_BUS_12_XIX_Systeminfo_01_XIX_E3V_K2CANFD: start 27, 1 bit, little-endian, data-type-policy=OVERRIDE, i-signal-type=PRIMITIVE, init-value=1, base-type=BT_SI_BUS_12, compu {0=Cx0_keine_Busruhe (CM_SI_BUS_12_Cx0_keine_Busruhe), 1=Cx1_Busruhe (CM_SI_BUS_12_Cx1_Busruhe)}, range raw 0..1, transfer-property=TRIGGERED-ON-CHANGE-WITHOUT-REPETITION  # MQB: unbelegt MLBevo: K2CAN E3_Volumen: MFLCAN MQBw_Baseline: K2CAN(FD)
          signal SI_BUS_13_XIX_Systeminfo_01_XIX_E3V_K2CANFD: start 28, 1 bit, little-endian, data-type-policy=OVERRIDE, i-signal-type=PRIMITIVE, init-value=1, base-type=BT_SI_BUS_13, compu {0=Cx0_keine_Busruhe (CM_SI_BUS_13_Cx0_keine_Busruhe), 1=Cx1_Busruhe (CM_SI_BUS_13_Cx1_Busruhe)}, range raw 0..1, transfer-property=TRIGGERED-ON-CHANGE-WITHOUT-REPETITION, to SAM(timeout 5 s)  # MQB: unbelegt MLBevo: DCAN MEB: CCAN MQBw_Baseline: K3CAN(FD)
          signal SI_BUS_14_XIX_Systeminfo_01_XIX_E3V_K2CANFD: start 29, 1 bit, little-endian, data-type-policy=OVERRIDE, i-signal-type=PRIMITIVE, init-value=1, base-type=BT_SI_BUS_14, compu {0=Cx0_keine_Busruhe (CM_SI_BUS_14_Cx0_keine_Busruhe), 1=Cx1_Busruhe (CM_SI_BUS_14_Cx1_Busruhe)}, range raw 0..1, transfer-property=TRIGGERED-ON-CHANGE-WITHOUT-REPETITION, to SAM(timeout 5 s)  # MQB/MQB A0: unbelegt MQB2020: HCAN MLBevo: CCAN E3_Volumen: EVCAN(FD) MQBw_Baseline: EVCANFD(FD)
          signal SI_BUS_15_XIX_Systeminfo_01_XIX_E3V_K2CANFD: start 30, 1 bit, little-endian, data-type-policy=OVERRIDE, i-signal-type=PRIMITIVE, init-value=1, base-type=BT_SI_BUS_15, compu {0=Cx0_keine_Busruhe (CM_SI_BUS_15_Cx0_keine_Busruhe), 1=Cx1_Busruhe (CM_SI_BUS_15_Cx1_Busruhe)}, range raw 0..1, transfer-property=TRIGGERED-ON-CHANGE-WITHOUT-REPETITION  # MQB: frei MQB2020: frei MLBevo: frei MEB: AFSCAN
          signal SI_NWDF_30_XIX_Systeminfo_01_XIX_E3V_K2CANFD: start 31, 1 bit, little-endian, data-type-policy=OVERRIDE, i-signal-type=PRIMITIVE, init-value=0, base-type=BT_SI_NWDF_30, compu {0=Cx0_Ueberwachung_nicht_freigegeben (CM_SI_NWDF_30_Cx0_Ueberwachung_nicht_freigegeben), 1=Cx1_Ueberwachung_freigegeben (CM_SI_NWDF_30_Cx1_Ueberwachung_freigegeben)}, range raw 0..1, transfer-property=PENDING  # Netzwerk-Diagnose Freigabe zur zentralen Aktivierung der Netzwerkdiagnose (keine Ausblendbedingung aktiv)
          signal SI_Bus_Identifikation_XIX_Systeminfo_01_XIX_E3V_K2CANFD: start 32, 8 bit, little-endian, data-type-policy=OVERRIDE, i-signal-type=PRIMITIVE, base-type=BT_SI_Bus_Identifikation, compu {16=Cx10_CAN_Diagnose (CM_SI_Bus_Identifikation_Cx10_CAN_Diagnose), 17=Cx11_CAN_Antrieb (CM_SI_Bus_Identifikation_Cx11_CAN_Antrieb), 18=Cx12_CAN_Komfort (CM_SI_Bus_Identifikation_Cx12_CAN_Komfort), 19=Cx13_CAN_Infotainment (CM_SI_Bus_Identifikation_Cx13_CAN_Infotainment), 20=Cx14_CAN_Fahrwerk (CM_SI_Bus_Identifikation_Cx14_CAN_Fahrwerk), 21=Cx15_CAN_Extended (CM_SI_Bus_Identifikation_Cx15_CAN_Extended), 22=Cx16_CAN_Hybrid (CM_SI_Bus_Identifikation_Cx16_CAN_Hybrid), 23=Cx17_CAN_Lade (CM_SI_Bus_Identifikation_Cx17_CAN_Lade), 24=Cx18_CAN_Kombi (CM_SI_Bus_Identifikation_Cx18_CAN_Kombi), 25=Cx19_CAN_Komfort_2 (CM_SI_Bus_Identifikation_Cx19_CAN_Komfort_2), 26=Cx1a_CAN_AFS (CM_SI_Bus_Identifikation_Cx1a_CAN_AFS), 27=Cx1b_CAN_MIB (CM_SI_Bus_Identifikation_Cx1b_CAN_MIB), 28=Cx1c_CAN_Batterie_BMC (CM_SI_Bus_Identifikation_Cx1c_CAN_Batterie_BMC), 29=Cx1d_CAN_Motor (CM_SI_Bus_Identifikation_Cx1d_CAN_Motor), 31=Cx1f_CAN_Airbag_Sicherheitssysteme (CM_SI_Bus_Identifikation_Cx1f_CAN_Airbag_Sicherheitssysteme), 33=Cx21_CAN_FahrerAssistenzSysteme (CM_SI_Bus_Identifikation_Cx21_CAN_FahrerAssistenzSysteme), 34=Cx22_CAN_Migration (CM_SI_Bus_Identifikation_Cx22_CAN_Migration), 35=Cx23_CAN_Connect (CM_SI_Bus_Identifikation_Cx23_CAN_Connect), 36=Cx24_CAN_AnzeigeBedienung (CM_SI_Bus_Identifikation_Cx24_CAN_AnzeigeBedienung), 37=Cx25_CAN_ElectricalVehicle (CM_SI_Bus_Identifikation_Cx25_CAN_ElectricalVehicle), 40=Cx28_CAN_Telematik (CM_SI_Bus_Identifikation_Cx28_CAN_Telematik), 41=Cx29_CAN_MFL (CM_SI_Bus_Identifikation_Cx29_CAN_MFL), 42=Cx2a_CAN_FahrerAssistenzSysteme_2 (CM_SI_Bus_Identifikation_Cx2a_CAN_FahrerAssistenzSysteme_2), 43=Cx2b_CAN_FahrerAssistenzSysteme_3 (CM_SI_Bus_Identifikation_Cx2b_CAN_FahrerAssistenzSysteme_3), 45=Cx2d_CAN_Fahrwerk_2 (CM_SI_Bus_Identifikation_Cx2d_CAN_Fahrwerk_2), 47=Cx2f_CAN_Komfort_3 (CM_SI_Bus_Identifikation_Cx2f_CAN_Komfort_3), 48=Cx30_FlexRay_A (CM_SI_Bus_Identifikation_Cx30_FlexRay_A), 49=Cx31_FlexRay_B (CM_SI_Bus_Identifikation_Cx31_FlexRay_B), 70=Cx46_CAN_PowerSupply (CM_SI_Bus_Identifikation_Cx46_CAN_PowerSupply), 71=Cx47_CAN_Passenger (CM_SI_Bus_Identifikation_Cx47_CAN_Passenger), 72=Cx48_CAN_Connect_2 (CM_SI_Bus_Identifikation_Cx48_CAN_Connect_2), 73=Cx49_CAN_ElectricalVehicle_2 (CM_SI_Bus_Identifikation_Cx49_CAN_ElectricalVehicle_2), 74=Cx4a_CAN_ElectricalVehicle_3 (CM_SI_Bus_Identifikation_Cx4a_CAN_ElectricalVehicle_3), 75=Cx4b_CAN_ElectricalVehicle_4 (CM_SI_Bus_Identifikation_Cx4b_CAN_ElectricalVehicle_4), 76=Cx4c_CAN_AutonomousDriving_1 (CM_SI_Bus_Identifikation_Cx4c_CAN_AutonomousDriving_1), 77=Cx4d_CAN_AutonomousDriving_2 (CM_SI_Bus_Identifikation_Cx4d_CAN_AutonomousDriving_2), 78=Cx4e_CAN_Drive (CM_SI_Bus_Identifikation_Cx4e_CAN_Drive), 79=Cx4f_CAN_NVEV (CM_SI_Bus_Identifikation_Cx4f_CAN_NVEV), 97=Cx61_VLAN_FAS (CM_SI_Bus_Identifikation_Cx61_VLAN_FAS), 98=Cx62_VLAN_Infotainment (CM_SI_Bus_Identifikation_Cx62_VLAN_Infotainment), 99=Cx63_VLAN_Connect (CM_SI_Bus_Identifikation_Cx63_VLAN_Connect), 100=Cx64_VLAN_Komfort (CM_SI_Bus_Identifikation_Cx64_VLAN_Komfort), 101=Cx65_VLAN_Antrieb (CM_SI_Bus_Identifikation_Cx65_VLAN_Antrieb), 102=Cx66_VLAN_Diagnose (CM_SI_Bus_Identifikation_Cx66_VLAN_Diagnose), 103=Cx67_VLAN_Internet (CM_SI_Bus_Identifikation_Cx67_VLAN_Internet), 104=Cx68_VLAN_Gateway (CM_SI_Bus_Identifikation_Cx68_VLAN_Gateway), 105=Cx69_VLAN_Remote_FC (CM_SI_Bus_Identifikation_Cx69_VLAN_Remote_FC), 106=Cx6a_VLAN_Connect_2 (CM_SI_Bus_Identifikation_Cx6a_VLAN_Connect_2), 107=Cx6b_VLAN_Licht (CM_SI_Bus_Identifikation_Cx6b_VLAN_Licht), 108=Cx6c_VLAN_Charge (CM_SI_Bus_Identifikation_Cx6c_VLAN_Charge), 109=Cx6d_VLAN_Cockpit (CM_SI_Bus_Identifikation_Cx6d_VLAN_Cockpit), 110=Cx6e_VLAN_Connect_3 (CM_SI_Bus_Identifikation_Cx6e_VLAN_Connect_3), 111=Cx6f_VLAN_IoT (CM_SI_Bus_Identifikation_Cx6f_VLAN_IoT), 112=Cx70_VLAN_CarPerformance (CM_SI_Bus_Identifikation_Cx70_VLAN_CarPerformance), 113=Cx71_VLAN_ConMod (CM_SI_Bus_Identifikation_Cx71_VLAN_ConMod), 114=Cx72_VLAN_FAS2 (CM_SI_Bus_Identifikation_Cx72_VLAN_FAS2), 115=Cx73_VLAN_DMZ_1 (CM_SI_Bus_Identifikation_Cx73_VLAN_DMZ_1), 116=Cx74_VLAN_SDS (CM_SI_Bus_Identifikation_Cx74_VLAN_SDS), 117=Cx75_VLAN_Rechenplattform (CM_SI_Bus_Identifikation_Cx75_VLAN_Rechenplattform), 118=Cx76_VLAN_Internet_2 (CM_SI_Bus_Identifikation_Cx76_VLAN_Internet_2), 119=Cx77_VLAN_MaaS (CM_SI_Bus_Identifikation_Cx77_VLAN_MaaS), 176=Cxb0_HCP1_CANFD01 (CM_SI_Bus_Identifikation_Cxb0_HCP1_CANFD01), 177=Cxb1_HCP1_CANFD02 (CM_SI_Bus_Identifikation_Cxb1_HCP1_CANFD02), 178=Cxb2_HCP1_CANFD03 (CM_SI_Bus_Identifikation_Cxb2_HCP1_CANFD03), 179=Cxb3_HCP1_CANFD04 (CM_SI_Bus_Identifikation_Cxb3_HCP1_CANFD04), 180=Cxb4_HCP1_CANFD05 (CM_SI_Bus_Identifikation_Cxb4_HCP1_CANFD05), 181=Cxb5_HCP1_CANFD06 (CM_SI_Bus_Identifikation_Cxb5_HCP1_CANFD06), 182=Cxb6_HCP1_CANFD07 (CM_SI_Bus_Identifikation_Cxb6_HCP1_CANFD07), 183=Cxb7_HCP1_CANFD08 (CM_SI_Bus_Identifikation_Cxb7_HCP1_CANFD08), 186=Cxba_HCP4_CANFD03 (CM_SI_Bus_Identifikation_Cxba_HCP4_CANFD03), 187=Cxbb_HCP4_CANFD04 (CM_SI_Bus_Identifikation_Cxbb_HCP4_CANFD04), 188=Cxbc_HCP1_CANFD09 (CM_SI_Bus_Identifikation_Cxbc_HCP1_CANFD09), 189=Cxbd_HCP4_CANFD06 (CM_SI_Bus_Identifikation_Cxbd_HCP4_CANFD06), 190=Cxbe_HCP4_CANFD07 (CM_SI_Bus_Identifikation_Cxbe_HCP4_CANFD07), 191=Cxbf_HCP4_CANFD08 (CM_SI_Bus_Identifikation_Cxbf_HCP4_CANFD08), 192=Cxc0_HCP4_CANFD09 (CM_SI_Bus_Identifikation_Cxc0_HCP4_CANFD09), 193=Cxc1_HCP4_CANFD10 (CM_SI_Bus_Identifikation_Cxc1_HCP4_CANFD10), 194=Cxc2_HCP1_CANFD10 (CM_SI_Bus_Identifikation_Cxc2_HCP1_CANFD10), 195=Cxc3_ICAS1_CANFD2_HCP5_CANFD02 (CM_SI_Bus_Identifikation_Cxc3_ICAS1_CANFD2_HCP5_CANFD02), 196=Cxc4_HCP1_CANFD11 (CM_SI_Bus_Identifikation_Cxc4_HCP1_CANFD11), 197=Cxc5_WU_HCP1_CANFD (CM_SI_Bus_Identifikation_Cxc5_WU_HCP1_CANFD), 199=Cxc7_WU_HCP2_CANFD (CM_SI_Bus_Identifikation_Cxc7_WU_HCP2_CANFD), 200=Cxc8_WU_HCP3_CANFD (CM_SI_Bus_Identifikation_Cxc8_WU_HCP3_CANFD), 201=Cxc9_WU_HCP4_CANFD (CM_SI_Bus_Identifikation_Cxc9_WU_HCP4_CANFD), 202=Cxca_HCP3_CANFD02 (CM_SI_Bus_Identifikation_Cxca_HCP3_CANFD02), 204=Cxcc_ESC_CANFD (CM_SI_Bus_Identifikation_Cxcc_ESC_CANFD), 205=Cxcd_HCP4_CANFD11 (CM_SI_Bus_Identifikation_Cxcd_HCP4_CANFD11), 206=Cxce_HCP4_CANFD12 (CM_SI_Bus_Identifikation_Cxce_HCP4_CANFD12), 207=Cxcf_CAN_Innenraumsensorik (CM_SI_Bus_Identifikation_Cxcf_CAN_Innenraumsensorik), 212=Cxd4_WU_ConMod_CANFD (CM_SI_Bus_Identifikation_Cxd4_WU_ConMod_CANFD), 213=Cxd5_WU_PASD_CANFD (CM_SI_Bus_Identifikation_Cxd5_WU_PASD_CANFD), 215=Cxd7_CAN_MobileDeviceKey (CM_SI_Bus_Identifikation_Cxd7_CAN_MobileDeviceKey), 217=Cxd9_CAN_Tuerantrieb_VL (CM_SI_Bus_Identifikation_Cxd9_CAN_Tuerantrieb_VL), 218=Cxda_CAN_Tuerantrieb_VR (CM_SI_Bus_Identifikation_Cxda_CAN_Tuerantrieb_VR), 219=Cxdb_CAN_Tuerantrieb_HL (CM_SI_Bus_Identifikation_Cxdb_CAN_Tuerantrieb_HL), 220=Cxdc_CAN_Tuerantrieb_HR (CM_SI_Bus_Identifikation_Cxdc_CAN_Tuerantrieb_HR), 221=Cxdd_CAN_Komfort_4 (CM_SI_Bus_Identifikation_Cxdd_CAN_Komfort_4), 222=Cxde_CAN_Komfort_5 (CM_SI_Bus_Identifikation_Cxde_CAN_Komfort_5)}, range raw 16..222, transfer-property=PENDING, to SAM(timeout 5 s)  # Das Signal identifiziert den Bus eindeutig. Das Signal ist konstant auf jedem Bus. Der Signalwert entspricht dem Wert "Busnummer" aus der VW80127 Gateway_component_list_databus_identification (0x2A2D) "Bus-Identifier".
          signal SI_CAB_V15_XIX_Systeminfo_01_XIX_E3V_K2CANFD: start 40, 24 bit, opaque, data-type-policy=OVERRIDE, i-signal-type=ARRAY, base-type=BT_SI_CAB_V15, compu {0=Cx0_Init (CM_SI_CAB_V15_Cx0_Init), 1=Cx1_CAB_01_Antrieb (CM_SI_CAB_V15_Cx1_CAB_01_Antrieb), 2=Cx2_CAB_02_Hybrid_Laden (CM_SI_CAB_V15_Cx2_CAB_02_Hybrid_Laden), 4=Cx4_CAB_03_Fahrwerk (CM_SI_CAB_V15_Cx4_CAB_03_Fahrwerk), 8=Cx8_CAB_04_Fahrerassistenz (CM_SI_CAB_V15_Cx8_CAB_04_Fahrerassistenz), 16=Cx10_CAB_05_Komfort (CM_SI_CAB_V15_Cx10_CAB_05_Komfort), 32=Cx20_CAB_06_Anzeige (CM_SI_CAB_V15_Cx20_CAB_06_Anzeige), 64=Cx40_CAB_07_Connect (CM_SI_CAB_V15_Cx40_CAB_07_Connect), 128=Cx80_CAB_08_MIB (CM_SI_CAB_V15_Cx80_CAB_08_MIB), 256=Cx100_CAB_09_Standheizung (CM_SI_CAB_V15_Cx100_CAB_09_Standheizung), 512=Cx200_CAB_10_MDK (CM_SI_CAB_V15_Cx200_CAB_10_MDK), 1024=Cx400_CAB_11_VLAN_Fahrerassistenz (CM_SI_CAB_V15_Cx400_CAB_11_VLAN_Fahrerassistenz), 4096=Cx1000_CAB_13_VLAN_Connect (CM_SI_CAB_V15_Cx1000_CAB_13_VLAN_Connect), 8192=Cx2000_CAB_14_VLAN_Infotainment (CM_SI_CAB_V15_Cx2000_CAB_14_VLAN_Infotainment), 16384=Cx4000_CAB_15_Laden (CM_SI_CAB_V15_Cx4000_CAB_15_Laden), 32768=Cx8000_CAB_16_Licht (CM_SI_CAB_V15_Cx8000_CAB_16_Licht), 65536=Cx10000_CAB_17_RTM (CM_SI_CAB_V15_Cx10000_CAB_17_RTM)}, range raw 0..65536, transfer-property=TRIGGERED-ON-CHANGE-WITHOUT-REPETITION  # CAB = Clusteraktivbits (V15)
      frame Temperaturen_01_XIX_E3V_K2CANFD: id 0x1A5555A6, to SAM, frame-length=8, can-addressing-mode=EXTENDED, can-frame-rx-behavior=CAN-FD, can-frame-tx-behavior=CAN-FD
        pdu Temperaturen_01_XIX_E3V_K2CANFD: length=8, transmission-mode-true-timing=cyclic-timing={time-offset=0.0, time-period=1.0}, unused-bit-pattern=0
          signal KBI_QBit_Aussen_Temp_gef_XIX_Temperaturen_01_XIX_E3V_K2CANFD: start 12, 1 bit, little-endian, data-type-policy=OVERRIDE, i-signal-type=PRIMITIVE, init-value=1, base-type=BT_KBI_QBit_Aussen_Temp_gef, compu {0=Cx0_gueltiger_Wert (CM_KBI_QBit_Aussen_Temp_gef_Cx0_gueltiger_Wert), 1=Cx1_Ersatz_Init_oder_Fehlerwert (CM_KBI_QBit_Aussen_Temp_gef_Cx1_Ersatz_Init_oder_Fehlerwert)}, range raw 0..1, transfer-property=PENDING  # 0x0 = gültiger Wert 0x1 = Ersatz-, Init- oder Fehlerwert
          signal KBI_Aussen_Temp_gef_XIX_Temperaturen_01_XIX_E3V_K2CANFD: start 16, 8 bit, little-endian, data-type-policy=OVERRIDE, i-signal-type=PRIMITIVE, init-value=254, base-type=BT_KBI_Aussen_Temp_gef, invalid-value=Invalid_KBI_Aussen_Temp_gef_XIX_Temperaturen_01_XIX_E3V_K2CANFD:255, compu {phys=raw*0.5-50 for raw 0..250, 253=Cxfd_nicht_verbaut (CM_KBI_Aussen_Temp_gef_Cxfd_nicht_verbaut) (nicht verbaut), 254=Cxfe_Init (CM_KBI_Aussen_Temp_gef_Cxfe_Init), 255=Cxff_Fehler (CM_KBI_Aussen_Temp_gef_Cxff_Fehler); unit Unit_DegreCelsi}, range phys -50..75 Unit_DegreCelsi, raw 0..255, unit=Unit_DegreCelsi, transfer-property=PENDING, to SAM(timeout 5 s)
      frame TM_01_XIX_E3V_K2CANFD: id 0x5A7, to SAM, frame-length=8, can-addressing-mode=STANDARD, can-frame-rx-behavior=CAN-FD, can-frame-tx-behavior=CAN-FD
        pdu TM_01_XIX_E3V_K2CANFD: length=8, minimum-delay=0.05, transmission-mode-false-timing={cyclic-timing={time-offset=0.0, time-period=1.0}, event-controlled-timing={number-of-repetitions=0, repetition-period=0.0}}, transmission-mode-true-timing={cyclic-timing={time-offset=0.0, time-period=0.1}, event-controlled-timing={number-of-repetitions=0, repetition-period=0.0}}, unused-bit-pattern=0
          transmission-mode-conditions:
            {data-filter={data-filter-type=MASKED-NEW-DIFFERS-X, mask=1, x=0}, i-signal-in-i-pdu=TM_Spiegel_Anklappen}
            {data-filter={data-filter-type=MASKED-NEW-DIFFERS-X, mask=1, x=0}, i-signal-in-i-pdu=TM_Nur_Hupen}
            {data-filter={data-filter-type=MASKED-NEW-DIFFERS-X, mask=1, x=0}, i-signal-in-i-pdu=TM_Door_Lock}
            {data-filter={data-filter-type=MASKED-NEW-DIFFERS-X, mask=1, x=0}, i-signal-in-i-pdu=TM_Door_Unlock}
            {data-filter={data-filter-type=MASKED-NEW-DIFFERS-X, mask=1, x=0}, i-signal-in-i-pdu=TM_Warnblinken}
            {data-filter={data-filter-type=MASKED-NEW-DIFFERS-X, mask=1, x=0}, i-signal-in-i-pdu=TM_Panik_Alarm}
          signal TM_01_BZ_XIX_TM_01_XIX_E3V_K2CANFD: start 8, 4 bit, little-endian, data-type-policy=OVERRIDE, i-signal-type=PRIMITIVE, init-value=0, base-type=BT_TM_01_BZ, compu {phys=raw for raw 0..15}, range phys 0..15, raw 0..15, transfer-property=PENDING  # 4bit Botschaftszähler, wird mit jeder Sendebotschaft inkrementiert
          signal OCU_Privacymode_Locationdata_XIX_TM_01_XIX_E3V_K2CANFD: start 12, 2 bit, little-endian, data-type-policy=OVERRIDE, i-signal-type=PRIMITIVE, init-value=0, base-type=BT_OCU_Privacymode_Locationdata, compu {0=Cx0_Init (CM_OCU_Privacymode_Locationdata_Cx0_Init), 1=Cx1_locationdata_freigabe (CM_OCU_Privacymode_Locationdata_Cx1_locationdata_freigabe), 2=Cx2_locationdata_gesperrt (CM_OCU_Privacymode_Locationdata_Cx2_locationdata_gesperrt)}, range raw 0..2, transfer-property=PENDING  # Signal zur Ausgabe des speziellen Privacymode Status zur Ausleitung von Fahrzeugpositionsdaten. 0 = Init 1 = Ausgabe der Fahrzeugpositionsdaten ist erlaubt 2 = Ausgabe der Fahrzeugpositionsdaten ist untersagt
          signal OCU_Privacymode_Status_XIX_TM_01_XIX_E3V_K2CANFD: start 14, 2 bit, little-endian, data-type-policy=OVERRIDE, i-signal-type=PRIMITIVE, init-value=0, base-type=BT_OCU_Privacymode_Status, compu {0=Cx0_Init (CM_OCU_Privacymode_Status_Cx0_Init), 1=Cx1_Privacymode_not_active (CM_OCU_Privacymode_Status_Cx1_Privacymode_not_active), 2=Cx2_Privacymode_active (CM_OCU_Privacymode_Status_Cx2_Privacymode_active)}, range raw 0..2, transfer-property=PENDING  # Signal zur Ausgabe des Privacymode Status 0 = Init 1 = Privacymode ist nicht aktiv 2 = Privacymode ist aktiv
          signal MOD_Energie_Anf_XIX_TM_01_XIX_E3V_K2CANFD: start 22, 2 bit, little-endian, data-type-policy=OVERRIDE, i-signal-type=PRIMITIVE, init-value=0, base-type=BT_MOD_Energie_Anf, invalid-value=Invalid_MOD_Energie_Anf_XIX_TM_01_XIX_E3V_K2CANFD:3, compu {0=Cx0_Keine_Anforderung (CM_MOD_Energie_Anf_Cx0_Keine_Anforderung), 1=Cx1_Anforderung_NV (CM_MOD_Energie_Anf_Cx1_Anforderung_NV), 2=Cx2_Anforderung_HV_Nutzung_Erlaubt (CM_MOD_Energie_Anf_Cx2_Anforderung_HV_Nutzung_Erlaubt), 3=Cx3_Fehler (CM_MOD_Energie_Anf_Cx3_Fehler)}, range raw 0..3, transfer-property=PENDING  # Anforderung Energieversorgung MOD-Job an das NVEM
          signal FaceRec_Enroll_Challenge_Request_XIX_TM_01_XIX_E3V_K2CANFD: start 24, 1 bit, little-endian, data-type-policy=OVERRIDE, i-signal-type=PRIMITIVE, init-value=0, base-type=BT_FaceRec_Enroll_Challenge_Request, compu {0=Cx0_SEND_NOTHING (CM_FaceRec_Enroll_Challenge_Request_Cx0_SEND_NOTHING), 1=Cx1_SEND_CHALLENGE (CM_FaceRec_Enroll_Challenge_Request_Cx1_SEND_CHALLENGE)}, range raw 0..1, transfer-property=PENDING  # When FaceRec on MIK receives this signal it will provide a challenge via SOK_FR_Enroll_MIK_Challenge.
          signal eCall_Mute_Anf_XIX_TM_01_XIX_E3V_K2CANFD: start 25, 1 bit, little-endian, data-type-policy=OVERRIDE, i-signal-type=PRIMITIVE, init-value=0, base-type=BT_eCall_Mute_Anf, compu {0=Cx0_kein_mute (CM_eCall_Mute_Anf_Cx0_kein_mute), 1=Cx1_mute (CM_eCall_Mute_Anf_Cx1_mute)}, range raw 0..1, transfer-property=PENDING  # Signalisiert die Aufforderungen alle Soundquellen im Fahrzeug während eines aktiven Notrufs zu muten
          signal iCall_active_XIX_TM_01_XIX_E3V_K2CANFD: start 38, 1 bit, little-endian, data-type-policy=OVERRIDE, i-signal-type=PRIMITIVE, init-value=0, base-type=BT_iCall_active, compu {0=Cx0_inaktiv (CM_iCall_active_Cx0_inaktiv), 1=Cx1_aktiv (CM_iCall_active_Cx1_aktiv)}, range raw 0..1, transfer-property=TRIGGERED-ON-CHANGE-WITHOUT-REPETITION, to SAM  # Statusrückmeldung von OCU über Infocall aktiv/inaktiv
          signal bCall_active_XIX_TM_01_XIX_E3V_K2CANFD: start 39, 1 bit, little-endian, data-type-policy=OVERRIDE, i-signal-type=PRIMITIVE, base-type=BT_bCall_active, compu {0=Cx0_bcall_inactive (CM_bCall_active_Cx0_bcall_inactive), 1=Cx1_bcall_active (CM_bCall_active_Cx1_bcall_active)}, range raw 0..1, transfer-property=TRIGGERED-ON-CHANGE-WITHOUT-REPETITION, to SAM  # 1: Breakdown call is active 0: BreakdownCall is inactive
          signal eCall_Funktionsstatus_02_XIX_TM_01_XIX_E3V_K2CANFD: start 41, 3 bit, little-endian, data-type-policy=OVERRIDE, i-signal-type=PRIMITIVE, init-value=7, base-type=BT_eCall_Funktionsstatus_02, compu {0=Cx0_kein_Fehler (CM_eCall_Funktionsstatus_02_Cx0_kein_Fehler), 1=Cx1_Manueller_Notruf_aktiv (CM_eCall_Funktionsstatus_02_Cx1_Manueller_Notruf_aktiv), 2=Cx2_Automatischer_Notruf_aktiv (CM_eCall_Funktionsstatus_02_Cx2_Automatischer_Notruf_aktiv), 7=Cx7_Init (CM_eCall_Funktionsstatus_02_Cx7_Init)}, range raw 0..7, transfer-property=PENDING  # Erweiterung des Funktionsstatus für andere Funktionen ACN aktiv, MEC aktiv MEC = manual emergency call = maueller Notruf ACN = automatic emergency call = automatischer Notruf
          signal eCall_Funktionsstatus_XIX_TM_01_XIX_E3V_K2CANFD: start 44, 3 bit, little-endian, data-type-policy=OVERRIDE, i-signal-type=PRIMITIVE, init-value=0, base-type=BT_eCall_Funktionsstatus, compu {0=Cx0_kein_Fehler (CM_eCall_Funktionsstatus_Cx0_kein_Fehler), 1=Cx1_Fkt_eingeschraenkt (CM_eCall_Funktionsstatus_Cx1_Fkt_eingeschraenkt), 2=Cx2_Fkt_eingeschraenkt_service (CM_eCall_Funktionsstatus_Cx2_Fkt_eingeschraenkt_service), 3=Cx3_Fkt_nicht_verfuegbar (CM_eCall_Funktionsstatus_Cx3_Fkt_nicht_verfuegbar), 4=Cx4_Fkt_Service (CM_eCall_Funktionsstatus_Cx4_Fkt_Service), 5=Cx5_Fkt_deaktiviert (CM_eCall_Funktionsstatus_Cx5_Fkt_deaktiviert), 6=Cx6_Fkt_aktiviert (CM_eCall_Funktionsstatus_Cx6_Fkt_aktiviert), 7=Cx7_init (CM_eCall_Funktionsstatus_Cx7_init)}, range raw 0..7, transfer-property=PENDING  # HMI-Aufruf im Kombi (Broadcast) Fehlerfälle die im Kombi angezeigt werden können
          signal TM_Spiegel_Anklappen_XIX_TM_01_XIX_E3V_K2CANFD: start 47, 1 bit, little-endian, data-type-policy=OVERRIDE, i-signal-type=PRIMITIVE, init-value=0, base-type=BT_TM_Spiegel_Anklappen, compu {0=Cx0_Init (CM_TM_Spiegel_Anklappen_Cx0_Init), 1=Cx1_Spiegel_anklappen (CM_TM_Spiegel_Anklappen_Cx1_Spiegel_anklappen)}, range raw 0..1, transfer-property=PENDING  # Anklappen der Außenspiegel über Remote MOD Anforderung
          signal TM_Nur_Hupen_XIX_TM_01_XIX_E3V_K2CANFD: start 48, 1 bit, little-endian, data-type-policy=OVERRIDE, i-signal-type=PRIMITIVE, init-value=0, base-type=BT_TM_Nur_Hupen, compu {0=Cx0_inaktiv (CM_TM_Nur_Hupen_Cx0_inaktiv), 1=Cx1_aktiv (CM_TM_Nur_Hupen_Cx1_aktiv)}, range raw 0..1, transfer-property=PENDING  # Remote Hupen (ohne Blinken) aktiviert
          signal TM_Door_Lock_XIX_TM_01_XIX_E3V_K2CANFD: start 49, 1 bit, little-endian, data-type-policy=OVERRIDE, i-signal-type=PRIMITIVE, init-value=0, base-type=BT_TM_Door_Lock, compu {0=Cx0_Init (CM_TM_Door_Lock_Cx0_Init), 1=Cx1_door_lock (CM_TM_Door_Lock_Cx1_door_lock)}, range raw 0..1, transfer-property=PENDING  # Remote Door lock angefordert: ZV zu/verriegeln
          signal TM_Door_Unlock_XIX_TM_01_XIX_E3V_K2CANFD: start 50, 1 bit, little-endian, data-type-policy=OVERRIDE, i-signal-type=PRIMITIVE, init-value=0, base-type=BT_TM_Door_Unlock, compu {0=Cx0_Init (CM_TM_Door_Unlock_Cx0_Init), 1=Cx1_door_unlock (CM_TM_Door_Unlock_Cx1_door_unlock)}, range raw 0..1, transfer-property=PENDING  # Remote Door unlock angefordert: ZV auf/entriegeln
          signal TM_Warnblinken_XIX_TM_01_XIX_E3V_K2CANFD: start 51, 1 bit, little-endian, data-type-policy=OVERRIDE, i-signal-type=PRIMITIVE, init-value=0, base-type=BT_TM_Warnblinken, compu {0=Cx0_Init (CM_TM_Warnblinken_Cx0_Init), 1=Cx1_Warnblinken_on (CM_TM_Warnblinken_Cx1_Warnblinken_on)}, range raw 0..1, transfer-property=PENDING  # Remote Blinken aktiviert
          signal TM_Panik_Alarm_XIX_TM_01_XIX_E3V_K2CANFD: start 52, 1 bit, little-endian, data-type-policy=OVERRIDE, i-signal-type=PRIMITIVE, init-value=0, base-type=BT_TM_Panik_Alarm, compu {0=Cx0_Init (CM_TM_Panik_Alarm_Cx0_Init), 1=Cx1_panik_alarm_on (CM_TM_Panik_Alarm_Cx1_panik_alarm_on)}, range raw 0..1, transfer-property=PENDING  # Remote Hupen und Blinken aktiv
          signal TM_ZV_Signatur_XIX_TM_01_XIX_E3V_K2CANFD: start 53, 11 bit, little-endian, data-type-policy=OVERRIDE, i-signal-type=PRIMITIVE, init-value=0, base-type=BT_TM_ZV_Signatur, compu {0=Cx0_Init (CM_TM_ZV_Signatur_Cx0_Init), phys=raw for raw 1..2047; unit Unit_None}, range phys 1..2047 Unit_None, raw 0..2047, unit=Unit_None, transfer-property=PENDING  # Gespeicherte Signatur der ZV für Authentifizierung
      frame TSG_BT_01_XIX_E3V_K2CANFD: id 0x3D1, to SAM, frame-length=8, can-addressing-mode=STANDARD, can-frame-rx-behavior=CAN-FD, can-frame-tx-behavior=CAN-FD
        pdu TSG_BT_01_XIX_E3V_K2CANFD: length=8, minimum-delay=0.02, transmission-mode-true-timing={cyclic-timing={time-offset=0.0, time-period=0.1}, event-controlled-timing={number-of-repetitions=0, repetition-period=0.0}}, unused-bit-pattern=0  # ab MQB 7.05
          signal BT_Tuer_geoeffnet_XIX_TSG_BT_01_XIX_E3V_K2CANFD: start 0, 1 bit, little-endian, data-type-policy=OVERRIDE, i-signal-type=PRIMITIVE, init-value=0, base-type=BT_BT_Tuer_geoeffnet, compu {0=Cx0_geschlossen (CM_BT_Tuer_geoeffnet_Cx0_geschlossen), 1=Cx1_offen (CM_BT_Tuer_geoeffnet_Cx1_offen)}, range raw 0..1, transfer-property=TRIGGERED-ON-CHANGE-WITHOUT-REPETITION, to SAM(timeout 1 s)  # Zeigt eine geöffnete Tür an
          signal BT_verriegelt_XIX_TSG_BT_01_XIX_E3V_K2CANFD: start 1, 1 bit, little-endian, data-type-policy=OVERRIDE, i-signal-type=PRIMITIVE, init-value=0, base-type=BT_BT_verriegelt, compu {0=Cx0_Init (CM_BT_verriegelt_Cx0_Init), 1=Cx1_verriegelt (CM_BT_verriegelt_Cx1_verriegelt)}, range raw 0..1, transfer-property=TRIGGERED-ON-CHANGE-WITHOUT-REPETITION  # Zeigt eine verriegelte Tür an ( Status wird erst nach vollständiger Schlossansteuerung ausgegeben (<=1,5sek))
          signal BT_gesafet_XIX_TSG_BT_01_XIX_E3V_K2CANFD: start 2, 1 bit, little-endian, data-type-policy=OVERRIDE, i-signal-type=PRIMITIVE, init-value=0, base-type=BT_BT_gesafet, compu {0=Cx0_Init (CM_BT_gesafet_Cx0_Init), 1=Cx1_gesafet (CM_BT_gesafet_Cx1_gesafet)}, range raw 0..1, transfer-property=TRIGGERED-ON-CHANGE-WITHOUT-REPETITION  # Im Zustand Safe wird auch das Signal BT_verriegelt = 1 gesendet
          signal BT_Schluesselschalter_auf_XIX_TSG_BT_01_XIX_E3V_K2CANFD: start 3, 1 bit, little-endian, data-type-policy=OVERRIDE, i-signal-type=PRIMITIVE, init-value=0, base-type=BT_BT_Schluesselschalter_auf, compu {0=Cx0_Init (CM_BT_Schluesselschalter_auf_Cx0_Init), 1=Cx1_Schluesselschalter_auf_betaetigt (CM_BT_Schluesselschalter_auf_Cx1_Schluesselschalter_auf_betaetigt)}, range raw 0..1, transfer-property=TRIGGERED-ON-CHANGE-WITHOUT-REPETITION  # Schlüsselschalter Richtung auf betätigt
          signal BT_Schluesselschalter_zu_XIX_TSG_BT_01_XIX_E3V_K2CANFD: start 4, 1 bit, little-endian, data-type-policy=OVERRIDE, i-signal-type=PRIMITIVE, init-value=0, base-type=BT_BT_Schluesselschalter_zu, compu {0=Cx0_Init (CM_BT_Schluesselschalter_zu_Cx0_Init), 1=Cx1_Schluesselschalter_zu_betaetigt (CM_BT_Schluesselschalter_zu_Cx1_Schluesselschalter_zu_betaetigt)}, range raw 0..1, transfer-property=TRIGGERED-ON-CHANGE-WITHOUT-REPETITION  # Schluesselschalter Richtung zu betaetigt
          signal BT_Unlock_Taster_XIX_TSG_BT_01_XIX_E3V_K2CANFD: start 5, 1 bit, little-endian, data-type-policy=OVERRIDE, i-signal-type=PRIMITIVE, init-value=0, base-type=BT_BT_Unlock_Taster, compu {0=Cx0_Init (CM_BT_Unlock_Taster_Cx0_Init), 1=Cx1_Unlock_Taster_betaetigt (CM_BT_Unlock_Taster_Cx1_Unlock_Taster_betaetigt)}, range raw 0..1, transfer-property=TRIGGERED-ON-CHANGE-WITHOUT-REPETITION  # Entriegelungstaster betätigt
          signal BT_Lock_Taster_XIX_TSG_BT_01_XIX_E3V_K2CANFD: start 6, 1 bit, little-endian, data-type-policy=OVERRIDE, i-signal-type=PRIMITIVE, init-value=0, base-type=BT_BT_Lock_Taster, compu {0=Cx0_Init (CM_BT_Lock_Taster_Cx0_Init), 1=Cx1_Lock_Taster_betaetigt (CM_BT_Lock_Taster_Cx1_Lock_Taster_betaetigt)}, range raw 0..1, transfer-property=TRIGGERED-ON-CHANGE-WITHOUT-REPETITION  # Verriegelungstaster
          signal BT_Sperrklinke_XIX_TSG_BT_01_XIX_E3V_K2CANFD: start 7, 1 bit, little-endian, data-type-policy=OVERRIDE, i-signal-type=PRIMITIVE, init-value=0, base-type=BT_BT_Sperrklinke, compu {0=Cx0_Schloss_in_Vorraste_und_Hauptraste (CM_BT_Sperrklinke_Cx0_Schloss_in_Vorraste_und_Hauptraste), 1=Cx1_Tuer_auf_oder_Tuer_Position_zwischen_Vor_und_Hauptraste (CM_BT_Sperrklinke_Cx1_Tuer_auf_oder_Tuer_Position_zwischen_Vor_und_Hauptraste)}, range raw 0..1, transfer-property=TRIGGERED-ON-CHANGE-WITHOUT-REPETITION  # Vorraste für Schloß zwischen Vor- und Hauptraste Signal kurz auf 1, danach wieder auf 0 wenn Tür in Hauptraste (Tür ist sicher zu wenn Sperrklinke und Türkontakt auf 0 sind)
          signal BT_TAG_betaetigt_XIX_TSG_BT_01_XIX_E3V_K2CANFD: start 8, 1 bit, little-endian, data-type-policy=OVERRIDE, i-signal-type=PRIMITIVE, init-value=0, base-type=BT_BT_TAG_betaetigt, compu {0=Cx0_Init (CM_BT_TAG_betaetigt_Cx0_Init), 1=Cx1_Tuerinnengriff_betaetigt (CM_BT_TAG_betaetigt_Cx1_Tuerinnengriff_betaetigt)}, range raw 0..1, transfer-property=TRIGGERED-ON-CHANGE-WITHOUT-REPETITION  # Türaussengriff
          signal BT_TIG_betaetigt_XIX_TSG_BT_01_XIX_E3V_K2CANFD: start 9, 1 bit, little-endian, data-type-policy=OVERRIDE, i-signal-type=PRIMITIVE, init-value=0, base-type=BT_BT_TIG_betaetigt, compu {0=Cx0_Init (CM_BT_TIG_betaetigt_Cx0_Init), 1=Cx1_Tuerinnengriff_betaetigt (CM_BT_TIG_betaetigt_Cx1_Tuerinnengriff_betaetigt)}, range raw 0..1, transfer-property=TRIGGERED-ON-CHANGE-WITHOUT-REPETITION  # Türinnengriff
          signal BT_EC_Spiegel_Helligkeit_XIX_TSG_BT_01_XIX_E3V_K2CANFD: start 10, 5 bit, little-endian, data-type-policy=OVERRIDE, i-signal-type=PRIMITIVE, init-value=0, base-type=BT_BT_EC_Spiegel_Helligkeit, compu {phys=raw*3.125 for raw 0..31; unit Unit_PerCent}, range phys 0..96.875 Unit_PerCent, raw 0..31, unit=Unit_PerCent, transfer-property=TRIGGERED-ON-CHANGE-WITHOUT-REPETITION  # Dimmung für den Aussenspiegel in %
          signal BT_Sp_Heizung_Anf_XIX_TSG_BT_01_XIX_E3V_K2CANFD: start 15, 1 bit, little-endian, data-type-policy=OVERRIDE, i-signal-type=PRIMITIVE, init-value=0, base-type=BT_BT_Sp_Heizung_Anf, compu {phys=raw*100 for raw 0..1; unit Unit_PerCent}, range phys 0..100 Unit_PerCent, raw 0..1, unit=Unit_PerCent, transfer-property=PENDING  # Kundenanforderung der Außenspiegelheizung Beifahrertür
          signal BT_Tuer_Status_XIX_TSG_BT_01_XIX_E3V_K2CANFD: start 16, 2 bit, little-endian, data-type-policy=OVERRIDE, i-signal-type=PRIMITIVE, base-type=BT_BT_Tuer_Status, invalid-value=Invalid_BT_Tuer_Status_XIX_TSG_BT_01_XIX_E3V_K2CANFD:3, compu {0=Cx0_Init (CM_BT_Tuer_Status_Cx0_Init), 1=Cx1_Tuer_geschlossen (CM_BT_Tuer_Status_Cx1_Tuer_geschlossen), 2=Cx2_Tuer_offen (CM_BT_Tuer_Status_Cx2_Tuer_offen), 3=Cx3_Fehler (CM_BT_Tuer_Status_Cx3_Fehler)}, range raw 0..3, transfer-property=TRIGGERED-ON-CHANGE-WITHOUT-REPETITION  # Türstatus mit Fehler und Initwert
          signal BT_TSG_hinten_verbaut_XIX_TSG_BT_01_XIX_E3V_K2CANFD: start 18, 1 bit, little-endian, data-type-policy=OVERRIDE, i-signal-type=PRIMITIVE, init-value=0, base-type=BT_BT_TSG_hinten_verbaut, compu {0=Cx0_nicht_verbaut (CM_BT_TSG_hinten_verbaut_Cx0_nicht_verbaut) (nicht verbaut), 1=Cx1_verbaut (CM_BT_TSG_hinten_verbaut_Cx1_verbaut)}, range raw 0..1, transfer-property=TRIGGERED-ON-CHANGE-WITHOUT-REPETITION
          signal BT_Sp_Blk_def_XIX_TSG_BT_01_XIX_E3V_K2CANFD: start 19, 1 bit, little-endian, data-type-policy=OVERRIDE, i-signal-type=PRIMITIVE, init-value=0, base-type=BT_BT_Sp_Blk_def, compu {0=Cx0_iO (CM_BT_Sp_Blk_def_Cx0_iO), 1=Cx1_Spiegel_Blinker_defekt (CM_BT_Sp_Blk_def_Cx1_Spiegel_Blinker_defekt)}, range raw 0..1, transfer-property=TRIGGERED-ON-CHANGE-WITHOUT-REPETITION, to SAM(timeout 1 s)  # Blinker am Spiegel defekt
          signal BT_FH_S_ManHoch_XIX_TSG_BT_01_XIX_E3V_K2CANFD: start 20, 1 bit, little-endian, data-type-policy=OVERRIDE, i-signal-type=PRIMITIVE, init-value=0, base-type=BT_BT_FH_S_ManHoch, compu {0=Cx0_Init (CM_BT_FH_S_ManHoch_Cx0_Init), 1=Cx1_FH_Schalter_man_hoch_gedrueckt (CM_BT_FH_S_ManHoch_Cx1_FH_Schalter_man_hoch_gedrueckt)}, range raw 0..1, transfer-property=TRIGGERED-ON-CHANGE-WITHOUT-REPETITION  # FH Schalter manuell hoch gedrückt
          signal BT_FH_S_AutoHoch_XIX_TSG_BT_01_XIX_E3V_K2CANFD: start 21, 1 bit, little-endian, data-type-policy=OVERRIDE, i-signal-type=PRIMITIVE, init-value=0, base-type=BT_BT_FH_S_AutoHoch, compu {0=Cx0_Init (CM_BT_FH_S_AutoHoch_Cx0_Init), 1=Cx1_FH_Schalter_auto_hoch_gedrueckt (CM_BT_FH_S_AutoHoch_Cx1_FH_Schalter_auto_hoch_gedrueckt)}, range raw 0..1, transfer-property=TRIGGERED-ON-CHANGE-WITHOUT-REPETITION  # FH Schalter automatisch hoch gedrückt
          signal BT_FH_S_ManTief_XIX_TSG_BT_01_XIX_E3V_K2CANFD: start 22, 1 bit, little-endian, data-type-policy=OVERRIDE, i-signal-type=PRIMITIVE, init-value=0, base-type=BT_BT_FH_S_ManTief, compu {0=Cx0_Init (CM_BT_FH_S_ManTief_Cx0_Init), 1=Cx1_FH_Schalter_man_tief_gedrueckt (CM_BT_FH_S_ManTief_Cx1_FH_Schalter_man_tief_gedrueckt)}, range raw 0..1, transfer-property=TRIGGERED-ON-CHANGE-WITHOUT-REPETITION  # FH Schalter manuell tief gedrückt
          signal BT_FH_S_AutoTief_XIX_TSG_BT_01_XIX_E3V_K2CANFD: start 23, 1 bit, little-endian, data-type-policy=OVERRIDE, i-signal-type=PRIMITIVE, init-value=0, base-type=BT_BT_FH_S_AutoTief, compu {0=Cx0_Init (CM_BT_FH_S_AutoTief_Cx0_Init), 1=Cx1_FH_Schalter_auto_tief_gedrueckt (CM_BT_FH_S_AutoTief_Cx1_FH_Schalter_auto_tief_gedrueckt)}, range raw 0..1, transfer-property=TRIGGERED-ON-CHANGE-WITHOUT-REPETITION  # FH Schalter automatisch tief gedrückt
          signal BT_FH_Oeffnung_XIX_TSG_BT_01_XIX_E3V_K2CANFD: start 24, 8 bit, little-endian, data-type-policy=OVERRIDE, i-signal-type=PRIMITIVE, init-value=0, base-type=BT_BT_FH_Oeffnung, compu {phys=raw*0.5 for raw 0..200; unit Unit_PerCent}, range phys 0..100 Unit_PerCent, raw 0..200, unit=Unit_PerCent, transfer-property=TRIGGERED-ON-CHANGE-WITHOUT-REPETITION  # Gibt den Fensteröffnungswert in % an.
          signal BT_FH_Bew_hoch_XIX_TSG_BT_01_XIX_E3V_K2CANFD: start 32, 1 bit, little-endian, data-type-policy=OVERRIDE, i-signal-type=PRIMITIVE, init-value=0, base-type=BT_BT_FH_Bew_hoch, compu {0=Cx0_Init (CM_BT_FH_Bew_hoch_Cx0_Init), 1=Cx1_FH_ist_in_Bewegung_hoch (CM_BT_FH_Bew_hoch_Cx1_FH_ist_in_Bewegung_hoch)}, range raw 0..1, transfer-property=TRIGGERED-ON-CHANGE-WITHOUT-REPETITION, to SAM(timeout 1 s)  # Fensterheber in Bewegung Richtung hoch
          signal BT_FH_Bew_tief_XIX_TSG_BT_01_XIX_E3V_K2CANFD: start 33, 1 bit, little-endian, data-type-policy=OVERRIDE, i-signal-type=PRIMITIVE, init-value=0, base-type=BT_BT_FH_Bew_tief, compu {0=Cx0_Init (CM_BT_FH_Bew_tief_Cx0_Init), 1=Cx1_FH_ist_in_Bewegung_tief (CM_BT_FH_Bew_tief_Cx1_FH_ist_in_Bewegung_tief)}, range raw 0..1, transfer-property=TRIGGERED-ON-CHANGE-WITHOUT-REPETITION, to SAM(timeout 1 s)  # Fensterheber in Bewegung Richtung tief
          signal BT_FH_Fang_XIX_TSG_BT_01_XIX_E3V_K2CANFD: start 34, 1 bit, little-endian, data-type-policy=OVERRIDE, i-signal-type=PRIMITIVE, init-value=0, base-type=BT_BT_FH_Fang, compu {0=Cx0_ausserhalb_Fangbereich (CM_BT_FH_Fang_Cx0_ausserhalb_Fangbereich), 1=Cx1_innerhalb_Fangbereich (CM_BT_FH_Fang_Cx1_innerhalb_Fangbereich)}, range raw 0..1, transfer-property=TRIGGERED-ON-CHANGE-WITHOUT-REPETITION  # Fangbereich ist 4mm von oberer Lippendichtung
          signal BT_FH_Block_XIX_TSG_BT_01_XIX_E3V_K2CANFD: start 35, 1 bit, little-endian, data-type-policy=OVERRIDE, i-signal-type=PRIMITIVE, init-value=0, base-type=BT_BT_FH_Block, compu {0=Cx0_Init (CM_BT_FH_Block_Cx0_Init), 1=Cx1_Fensterheber_Block (CM_BT_FH_Block_Cx1_Fensterheber_Block)}, range raw 0..1, transfer-property=TRIGGERED-ON-CHANGE-WITHOUT-REPETITION  # Fensterscheibe befindet sich im mechanischen Block (oben oder unten)
          signal BT_FH_Thermo_XIX_TSG_BT_01_XIX_E3V_K2CANFD: start 36, 1 bit, little-endian, data-type-policy=OVERRIDE, i-signal-type=PRIMITIVE, init-value=0, base-type=BT_BT_FH_Thermo, compu {0=Cx0_Init (CM_BT_FH_Thermo_Cx0_Init), 1=Cx1_Thermoschutz_aktiv (CM_BT_FH_Thermo_Cx1_Thermoschutz_aktiv)}, range raw 0..1, transfer-property=TRIGGERED-ON-CHANGE-WITHOUT-REPETITION  # gibt an ob Fensterheber im Thermoschutz ist
          signal BT_UEKB_aktiviert_XIX_TSG_BT_01_XIX_E3V_K2CANFD: start 37, 1 bit, little-endian, data-type-policy=OVERRIDE, i-signal-type=PRIMITIVE, init-value=0, base-type=BT_BT_UEKB_aktiviert, compu {0=Cx0_Init (CM_BT_UEKB_aktiviert_Cx0_Init), 1=Cx1_aktiv (CM_BT_UEKB_aktiviert_Cx1_aktiv)}, range raw 0..1, transfer-property=TRIGGERED-ON-CHANGE-WITHOUT-REPETITION  # Überschutzbegrenzungskraft bei Reversieren
          signal BT_Kisi_Fehler_XIX_TSG_BT_01_XIX_E3V_K2CANFD: start 38, 1 bit, little-endian, data-type-policy=OVERRIDE, i-signal-type=PRIMITIVE, init-value=0, base-type=BT_BT_Kisi_Fehler, invalid-value=Invalid_BT_Kisi_Fehler_XIX_TSG_BT_01_XIX_E3V_K2CANFD:1, compu {0=Cx0_kein_Fehler (CM_BT_Kisi_Fehler_Cx0_kein_Fehler), 1=Cx1_Fehler (CM_BT_Kisi_Fehler_Cx1_Fehler)}, range raw 0..1, transfer-property=TRIGGERED-ON-CHANGE-WITHOUT-REPETITION  # Fehlerstatus Kindersicherungsfunktion
          signal BT_FH_normiert_XIX_TSG_BT_01_XIX_E3V_K2CANFD: start 39, 1 bit, little-endian, data-type-policy=OVERRIDE, i-signal-type=PRIMITIVE, init-value=0, base-type=BT_BT_FH_normiert, compu {0=Cx0_Init (CM_BT_FH_normiert_Cx0_Init), 1=Cx1_Fenster_normiert (CM_BT_FH_normiert_Cx1_Fenster_normiert)}, range raw 0..1, transfer-property=TRIGGERED-ON-CHANGE-WITHOUT-REPETITION  # Die Position der Fensterheberscheibe ist bekannt
          signal BT_Schliesstaster_XIX_TSG_BT_01_XIX_E3V_K2CANFD: start 40, 1 bit, little-endian, data-type-policy=OVERRIDE, i-signal-type=PRIMITIVE, init-value=0, base-type=BT_BT_Schliesstaster, compu {0=Cx0_nicht_betaetigt (CM_BT_Schliesstaster_Cx0_nicht_betaetigt), 1=Cx1_betaetigt (CM_BT_Schliesstaster_Cx1_betaetigt)}, range raw 0..1, transfer-property=TRIGGERED-ON-CHANGE-WITHOUT-REPETITION  # Schliesstaster Beifahrertür
          signal BT_Zuziehhilfe_aktiv_XIX_TSG_BT_01_XIX_E3V_K2CANFD: start 41, 1 bit, little-endian, data-type-policy=OVERRIDE, i-signal-type=PRIMITIVE, init-value=0, base-type=BT_BT_Zuziehhilfe_aktiv, compu {0=Cx0_Init (CM_BT_Zuziehhilfe_aktiv_Cx0_Init), 1=Cx1_Zuziehhilfe_aktiv (CM_BT_Zuziehhilfe_aktiv_Cx1_Zuziehhilfe_aktiv)}, range raw 0..1, transfer-property=TRIGGERED-ON-CHANGE-WITHOUT-REPETITION  # Zuziehhilfe aktiv
          signal BT_SP_ausgerastet_XIX_TSG_BT_01_XIX_E3V_K2CANFD: start 42, 1 bit, little-endian, data-type-policy=OVERRIDE, i-signal-type=PRIMITIVE, init-value=0, base-type=BT_BT_SP_ausgerastet, compu {0=Cx0_Init (CM_BT_SP_ausgerastet_Cx0_Init), 1=Cx1_Spiegel_ausgerastet (CM_BT_SP_ausgerastet_Cx1_Spiegel_ausgerastet)}, range raw 0..1, transfer-property=TRIGGERED-ON-CHANGE-WITHOUT-REPETITION  # Spiegel ausgerastet
          signal BT_SP_lr_aktiv_XIX_TSG_BT_01_XIX_E3V_K2CANFD: start 43, 1 bit, little-endian, data-type-policy=OVERRIDE, i-signal-type=PRIMITIVE, init-value=0, base-type=BT_BT_SP_lr_aktiv, compu {0=Cx0_Init (CM_BT_SP_lr_aktiv_Cx0_Init), 1=Cx1_Spiegel_xAchse_aktiv (CM_BT_SP_lr_aktiv_Cx1_Spiegel_xAchse_aktiv)}, range raw 0..1, transfer-property=TRIGGERED-ON-CHANGE-WITHOUT-REPETITION  # Spiegelverstellung in Richtung links/rechts aktiv
          signal BT_SP_ht_aktiv_XIX_TSG_BT_01_XIX_E3V_K2CANFD: start 44, 1 bit, little-endian, data-type-policy=OVERRIDE, i-signal-type=PRIMITIVE, init-value=0, base-type=BT_BT_SP_ht_aktiv, compu {0=Cx0_Init (CM_BT_SP_ht_aktiv_Cx0_Init), 1=Cx1_Spiegel_yAchse_aktiv (CM_BT_SP_ht_aktiv_Cx1_Spiegel_yAchse_aktiv)}, range raw 0..1, transfer-property=TRIGGERED-ON-CHANGE-WITHOUT-REPETITION  # Spiegelverstellung in Richtung hoch/tief aktiv
          signal BT_SP_Heizung_aktiv_XIX_TSG_BT_01_XIX_E3V_K2CANFD: start 45, 1 bit, little-endian, data-type-policy=OVERRIDE, i-signal-type=PRIMITIVE, init-value=0, base-type=BT_BT_SP_Heizung_aktiv, compu {0=Cx0_BF_Spiegelheizung_aus (CM_BT_SP_Heizung_aktiv_Cx0_BF_Spiegelheizung_aus), 1=Cx1_BF_Spiegelheizung_ein (CM_BT_SP_Heizung_aktiv_Cx1_BF_Spiegelheizung_ein)}, range raw 0..1, transfer-property=TRIGGERED-ON-CHANGE-WITHOUT-REPETITION  # Zustand Spiegelheizung Beifahrertür
          signal BT_Oben_Block_erw_XIX_TSG_BT_01_XIX_E3V_K2CANFD: start 46, 1 bit, little-endian, data-type-policy=OVERRIDE, i-signal-type=PRIMITIVE, init-value=0, base-type=BT_BT_Oben_Block_erw, compu {0=Cx0_Fensterheber_nicht_in_Blockerwar (CM_BT_Oben_Block_erw_Cx0_Fensterheber_nicht_in_Blockerwar), 1=Cx1_Fensterheber_in_Blockerwartung_o (CM_BT_Oben_Block_erw_Cx1_Fensterheber_in_Blockerwartung_o)}, range raw 0..1, transfer-property=TRIGGERED-ON-CHANGE-WITHOUT-REPETITION, to SAM(timeout 1 s)  # Fensterheber in Blockerwartung oben
          signal BT_Unten_Block_erw_XIX_TSG_BT_01_XIX_E3V_K2CANFD: start 47, 1 bit, little-endian, data-type-policy=OVERRIDE, i-signal-type=PRIMITIVE, init-value=0, base-type=BT_BT_Unten_Block_erw, compu {0=Cx0_Fensterheber_nicht_in_Blockerwar (CM_BT_Unten_Block_erw_Cx0_Fensterheber_nicht_in_Blockerwar), 1=Cx1_Fensterheber_in_Blockerwartung_u (CM_BT_Unten_Block_erw_Cx1_Fensterheber_in_Blockerwartung_u)}, range raw 0..1, transfer-property=TRIGGERED-ON-CHANGE-WITHOUT-REPETITION, to SAM(timeout 1 s)  # Fensterheber in Blockerwartung unten
          signal BT_Tuer_Status_QBit_XIX_TSG_BT_01_XIX_E3V_K2CANFD: start 48, 1 bit, little-endian, data-type-policy=OVERRIDE, i-signal-type=PRIMITIVE, init-value=0, base-type=BT_BT_Tuer_Status_QBit, compu {0=Cx0_Status_Tuerkontakt_sicher (CM_BT_Tuer_Status_QBit_Cx0_Status_Tuerkontakt_sicher), 1=Cx1_Status_Tuerkontakt_unsicher (CM_BT_Tuer_Status_QBit_Cx1_Status_Tuerkontakt_unsicher)}, range raw 0..1, transfer-property=PENDING  # Dieses Bit gibt die Zuverlässigkeit des Türkontakts an. Ein auf dieses Bit folgender Fehlereintrag ist mit dem Sender des Bits abzustimmen (gültig ab PPE).
          signal BFS_Status_eTAG_XIX_TSG_BT_01_XIX_E3V_K2CANFD: start 49, 2 bit, little-endian, data-type-policy=OVERRIDE, i-signal-type=PRIMITIVE, init-value=0, base-type=BT_BFS_Status_eTAG, invalid-value=Invalid_BFS_Status_eTAG_XIX_TSG_BT_01_XIX_E3V_K2CANFD:3, compu {0=Cx0_Init (CM_BFS_Status_eTAG_Cx0_Init), 1=Cx1_Griff_ausgefahren (CM_BFS_Status_eTAG_Cx1_Griff_ausgefahren), 2=Cx2_Griff_eingefahren (CM_BFS_Status_eTAG_Cx2_Griff_eingefahren), 3=Cx3_Fehler (CM_BFS_Status_eTAG_Cx3_Fehler)}, range raw 0..3, transfer-property=TRIGGERED-ON-CHANGE-WITHOUT-REPETITION  # Status des elektrischen Tueraussengriffes Beifahrertuer
          signal BT_TCR_Mode_aktiv_XIX_TSG_BT_01_XIX_E3V_K2CANFD: start 51, 1 bit, little-endian, data-type-policy=OVERRIDE, i-signal-type=PRIMITIVE, init-value=0, base-type=BT_BT_TCR_Mode_aktiv, compu {0=Cx0_TCR_Mode_deaktiv (CM_BT_TCR_Mode_aktiv_Cx0_TCR_Mode_deaktiv), 1=Cx1_TCR_Mode_aktiv (CM_BT_TCR_Mode_aktiv_Cx1_TCR_Mode_aktiv)}, range raw 0..1, transfer-property=TRIGGERED-ON-CHANGE-WITHOUT-REPETITION  # Signal zeigt eine aktive mechanische Redundanz am Türschloss an.
          signal BT_Lock_Unlock_Taster_XIX_TSG_BT_01_XIX_E3V_K2CANFD: start 52, 1 bit, little-endian, data-type-policy=OVERRIDE, i-signal-type=PRIMITIVE, init-value=0, base-type=BT_BT_Lock_Unlock_Taster, compu {0=Cx0_nicht_betaetigt (CM_BT_Lock_Unlock_Taster_Cx0_nicht_betaetigt), 1=Cx1_betaetigt (CM_BT_Lock_Unlock_Taster_Cx1_betaetigt)}, range raw 0..1, transfer-property=TRIGGERED-ON-CHANGE-WITHOUT-REPETITION  # ZV Funktion Lock Unlock mit Toggle-Logik
          signal BT_SP_Heizung_Status_XIX_TSG_BT_01_XIX_E3V_K2CANFD: start 55, 1 bit, little-endian, data-type-policy=OVERRIDE, i-signal-type=PRIMITIVE, init-value=0, base-type=BT_BT_SP_Heizung_Status, compu {0=Cx0_Init (CM_BT_SP_Heizung_Status_Cx0_Init), 1=Cx1_Status_Spiegelheizung_ein (CM_BT_SP_Heizung_Status_Cx1_Status_Spiegelheizung_ein)}, range raw 0..1, transfer-property=TRIGGERED-ON-CHANGE-WITHOUT-REPETITION  # Status der Spiegelheizung
          signal ASW_Warnung_aktiv_BFS_XIX_TSG_BT_01_XIX_E3V_K2CANFD: start 56, 1 bit, little-endian, data-type-policy=OVERRIDE, i-signal-type=PRIMITIVE, init-value=0, base-type=BT_ASW_Warnung_aktiv_BFS, compu {0=Cx0_nicht_angefordert (CM_ASW_Warnung_aktiv_BFS_Cx0_nicht_angefordert), 1=Cx1_angefordert (CM_ASW_Warnung_aktiv_BFS_Cx1_angefordert)}, range raw 0..1, transfer-property=TRIGGERED-ON-CHANGE-WITHOUT-REPETITION, to SAM(timeout 1 s)  # Abschaltung der Ambientefunktion Beifahrertür bei aktiver ASW Warnung an der Fahrertür
          signal BT_FH_Pos_oben_XIX_TSG_BT_01_XIX_E3V_K2CANFD: start 57, 1 bit, little-endian, data-type-policy=OVERRIDE, i-signal-type=PRIMITIVE, init-value=0, base-type=BT_BT_FH_Pos_oben, compu {1=Cx1_Scheibe_oben_nach_Absenken_auf_Position (CM_BT_FH_Pos_oben_Cx1_Scheibe_oben_nach_Absenken_auf_Position) (Scheibe oben (nach Absenken auf Position))}, range raw 1, transfer-property=TRIGGERED-ON-CHANGE-WITHOUT-REPETITION
          signal BT_Tuerschloss_defekt_XIX_TSG_BT_01_XIX_E3V_K2CANFD: start 58, 1 bit, little-endian, data-type-policy=OVERRIDE, i-signal-type=PRIMITIVE, base-type=BT_BT_Tuerschloss_defekt, compu {0=Cx0_Tuerschloss_funktionsfaehig (CM_BT_Tuerschloss_defekt_Cx0_Tuerschloss_funktionsfaehig), 1=Cx1_Tuerschloss_defekt (CM_BT_Tuerschloss_defekt_Cx1_Tuerschloss_defekt)}, range raw 0..1, transfer-property=PENDING  # Das Beifahrertürschloss ist nicht mehr funktionsfähig.
          signal BT_Tueroeffnen_Warnung_XIX_TSG_BT_01_XIX_E3V_K2CANFD: start 59, 1 bit, little-endian, data-type-policy=OVERRIDE, i-signal-type=PRIMITIVE, init-value=0, base-type=BT_BT_Tueroeffnen_Warnung, compu {0=Cx0_Tuerwarnung_nicht_aktiv (CM_BT_Tueroeffnen_Warnung_Cx0_Tuerwarnung_nicht_aktiv), 1=Cx1_Tuerwarnung_aktiv (CM_BT_Tueroeffnen_Warnung_Cx1_Tuerwarnung_aktiv)}, range raw 0..1, transfer-property=TRIGGERED-ON-CHANGE-WITHOUT-REPETITION  # Bit wird gesetzt, wenn Tür während der Fahrt geoeffnet werden soll.
          signal BT_Lock_Taster_inv_XIX_TSG_BT_01_XIX_E3V_K2CANFD: start 60, 1 bit, little-endian, data-type-policy=OVERRIDE, i-signal-type=PRIMITIVE, init-value=0, base-type=BT_BT_Lock_Taster_inv, compu {0=Cx0_Lock_Taster_betaetigt (CM_BT_Lock_Taster_inv_Cx0_Lock_Taster_betaetigt) (Lock Taster betätigt), 1=Cx1_Lock_Taster_nicht_betaetigt (CM_BT_Lock_Taster_inv_Cx1_Lock_Taster_nicht_betaetigt) (Lock Taster nicht betätigt)}, range raw 0..1, transfer-property=TRIGGERED-ON-CHANGE-WITHOUT-REPETITION  # Lock Taster nicht betätigt
          signal BT_Schluesselschalter_zu_inv_XIX_TSG_BT_01_XIX_E3V_K2CANFD: start 61, 1 bit, little-endian, data-type-policy=OVERRIDE, i-signal-type=PRIMITIVE, init-value=0, base-type=BT_BT_Schluesselschalter_zu_inv, compu {0=Cx0_Schluesselschalter_betaetigt (CM_BT_Schluesselschalter_zu_inv_Cx0_Schluesselschalter_betaetigt) (Schlüsselschalter betätigt), 1=Cx1_Schluesselschalter_nicht_betaetigt (CM_BT_Schluesselschalter_zu_inv_Cx1_Schluesselschalter_nicht_betaetigt) (Schlüsselschalter nicht betätigt)}, range raw 0..1, transfer-property=TRIGGERED-ON-CHANGE-WITHOUT-REPETITION  # Schluesselschalter zu nicht betaetigt
          signal BT_SWA_HMI_defekt_XIX_TSG_BT_01_XIX_E3V_K2CANFD: start 62, 1 bit, little-endian, data-type-policy=OVERRIDE, i-signal-type=PRIMITIVE, init-value=0, base-type=BT_BT_SWA_HMI_defekt, compu {0=Cx0_SWA_kein_Fehler (CM_BT_SWA_HMI_defekt_Cx0_SWA_kein_Fehler), 1=Cx1_SWA_Fehler (CM_BT_SWA_HMI_defekt_Cx1_SWA_Fehler)}, range raw 0..1, transfer-property=PENDING  # Zeigt an, ob die SWA-Anzeige defekt ist.
          signal BT_ASW_HMI_defekt_XIX_TSG_BT_01_XIX_E3V_K2CANFD: start 63, 1 bit, little-endian, data-type-policy=OVERRIDE, i-signal-type=PRIMITIVE, init-value=0, base-type=BT_BT_ASW_HMI_defekt, compu {0=Cx0_ASW_kein_Fehler (CM_BT_ASW_HMI_defekt_Cx0_ASW_kein_Fehler), 1=Cx1_ASW_Fehler (CM_BT_ASW_HMI_defekt_Cx1_ASW_Fehler)}, range raw 0..1, transfer-property=PENDING  # Zeigt an, ob die ASW-Anzeige defekt ist.
